VERSION ""

NS_ :

BS_:

BU_: AIL CAB C_ECU C_ECU_GW

BO_ 552 RDR228: 8 C_ECU_GW
 SG_ RDR228_7_0_EYE_TIMEOUT_ERROR_FLG : 56|1@1+ (1,0) [0|1] "" Vector__XXX
 SG_ RDR228_7_1_BLOCKAGE_FORMING_2 : 57|1@1+ (1,0) [0|1] "" Vector__XXX
 SG_ RDR228_7_2_WARN_LCA_R_1ST : 58|1@1+ (1,0) [0|1] "" Vector__XXX
 SG_ RDR228_7_3_WARN_LCA_L_1ST : 59|1@1+ (1,0) [0|1] "" Vector__XXX
 SG_ RDR228_7_4_WARN_LCA_R_2ND : 60|1@1+ (1,0) [0|1] "" Vector__XXX
 SG_ RDR228_7_5_WARN_LCA_L_2ND : 61|1@1+ (1,0) [0|1] "" Vector__XXX
 SG_ RDR228_7_6_WARN_RCTA_R : 62|1@1+ (1,0) [0|1] ""  AIL,CAB
 SG_ RDR228_7_7_WARN_RCTA_L : 63|1@1+ (1,0) [0|1] ""  AIL,CAB
 SG_ RDR228_6_0_WARN_BSD_R_1ST : 48|1@1+ (1,0) [0|1] ""  AIL,CAB
 SG_ RDR228_6_1_WARN_BSD_L_1ST : 49|1@1+ (1,0) [0|1] ""  AIL,CAB
 SG_ RDR228_6_2_WARN_BSD_R_2ND : 50|1@1+ (1,0) [0|1] "" Vector__XXX
 SG_ RDR228_6_3_WARN_BSD_L_2ND : 51|1@1+ (1,0) [0|1] "" Vector__XXX
 SG_ RDR228_6_5_BLOCKAGE_STS : 53|3@1+ (1,0) [0|5] ""  AIL,CAB
 SG_ RDR228_5_0_BSD_R_E : 40|1@1+ (1,0) [0|1] "" Vector__XXX
 SG_ RDR228_5_1_BSD_L_E : 41|1@1+ (1,0) [0|1] "" Vector__XXX
 SG_ RDR228_5_2_LCA_R_E : 42|1@1+ (1,0) [0|1] "" Vector__XXX
 SG_ RDR228_5_3_LCA_L_E : 43|1@1+ (1,0) [0|1] "" Vector__XXX
 SG_ RDR228_5_4_BSD_R_A : 44|1@1+ (1,0) [0|1] "" Vector__XXX
 SG_ RDR228_5_5_BSD_L_A : 45|1@1+ (1,0) [0|1] "" Vector__XXX
 SG_ RDR228_5_6_LCA_R_A : 46|1@1+ (1,0) [0|1] "" Vector__XXX
 SG_ RDR228_5_7_LCA_L_A : 47|1@1+ (1,0) [0|1] "" Vector__XXX
 SG_ RDR228_4_0_DOW_ACTIVELAMP : 32|1@1+ (1,0) [0|1] ""  AIL,CAB
 SG_ RDR228_4_1_WARN_DOW_1ST_R : 33|1@1+ (1,0) [0|1] ""  AIL,CAB
 SG_ RDR228_4_2_WARN_DOW_1ST_L : 34|1@1+ (1,0) [0|1] ""  AIL,CAB
 SG_ RDR228_4_3_WARN_DOW_2ST_R : 35|1@1+ (1,0) [0|1] ""  AIL,CAB
 SG_ RDR228_4_4_WARN_DOW_2ST_L : 36|1@1+ (1,0) [0|1] ""  AIL,CAB
 SG_ RDR228_4_5_CSTM_STS_SRVD : 37|1@1+ (1,0) [0|1] "" Vector__XXX
 SG_ RDR228_4_6_CSTM_STS_BSD_LCA_2ND : 38|1@1+ (1,0) [0|1] "" Vector__XXX
 SG_ RDR228_4_7_CSTM_STS_RCTA : 39|1@1+ (1,0) [0|1] "" Vector__XXX
 SG_ RDR228_3_0_WARN_BSD_LCA_R_2ND : 24|1@1+ (1,0) [0|1] ""  AIL,CAB
 SG_ RDR228_3_1_WARN_BSD_LCA_L_2ND : 25|1@1+ (1,0) [0|1] ""  AIL,CAB
 SG_ RDR228_3_2_CSTM_STS_DOW : 26|1@1+ (1,0) [0|1] "" Vector__XXX
 SG_ RDR228_3_3_CSTM_STS_DOW_SFT_POS : 27|1@1+ (1,0) [0|1] "" Vector__XXX
 SG_ RDR228_3_5_CSTM_DSP_BSD_LCA : 29|1@1+ (1,0) [0|1] "" Vector__XXX
 SG_ RDR228_3_6_CSTM_DSP_BSD_LCA_2ND : 30|1@1+ (1,0) [0|1] "" Vector__XXX
 SG_ RDR228_3_7_CSTM_DSP_RCTA : 31|1@1+ (1,0) [0|1] "" Vector__XXX
 SG_ RDR228_2_0_CSTM_DSP_DOW : 16|1@1+ (1,0) [0|1] "" Vector__XXX
 SG_ RDR228_2_1_EYE_LOCAL_BUS1_FAIL : 17|1@1+ (1,0) [0|1] "" Vector__XXX
 SG_ RDR228_2_2_CSTM_DSP_DOW_SFT_POS : 18|1@1+ (1,0) [0|1] "" Vector__XXX
 SG_ RDR228_2_3_ELK_STOP_REQ_FLG : 19|1@1+ (1,0) [0|1] "" Vector__XXX
 SG_ RDR228_2_4_FAIL_RDRSYS : 20|1@1+ (1,0) [0|1] "" Vector__XXX
 SG_ RDR228_2_5_STOP_RDRSYS : 21|1@1+ (1,0) [0|1] "" Vector__XXX
 SG_ RDR228_2_6_ON_OFF_RDRSYS : 22|1@1+ (1,0) [0|1] "" Vector__XXX
 SG_ RDR228_2_7_BLOCKAGE_FORMING : 23|1@1+ (1,0) [0|1] "" Vector__XXX
 SG_ RDR228_1_0_MSG_COUNTER : 8|4@1+ (1,0) [0|15] ""  AIL
 SG_ RDR228_1_4_BATT_OFF_CAUSE : 12|1@1+ (1,0) [0|1] "" Vector__XXX
 SG_ RDR228_1_5_CSTM_GLO_1 : 13|1@1+ (1,0) [0|1] "" Vector__XXX
 SG_ RDR228_1_6_CSTM_GLO_3 : 14|1@1+ (1,0) [0|1] "" Vector__XXX
 SG_ RDR228_1_7_CSTM_GLO_2 : 15|1@1+ (1,0) [0|1] "" Vector__XXX
 SG_ RDR228_0_0_CHECK_SUM : 0|8@1+ (1,0) [0|255] ""  AIL

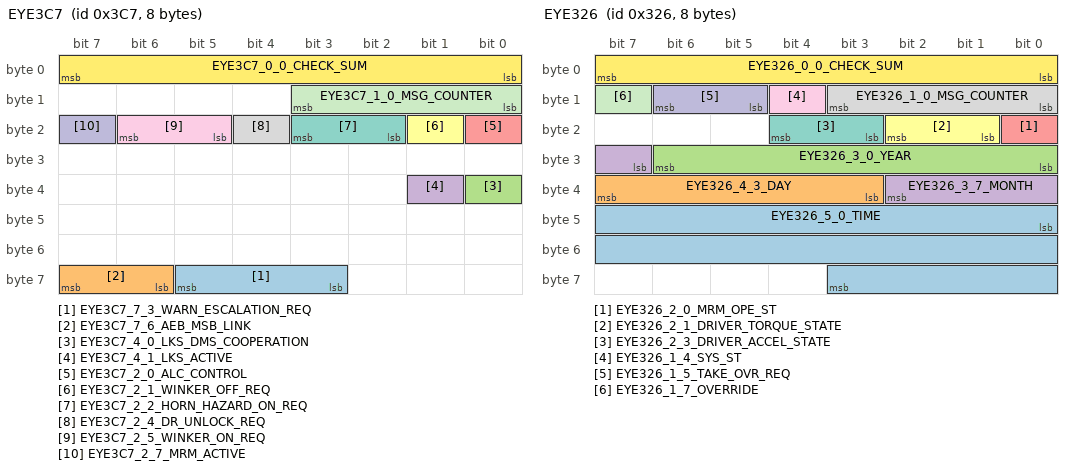
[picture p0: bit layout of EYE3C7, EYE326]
BO_ 967 EYE3C7: 8 C_ECU_GW
 SG_ EYE3C7_7_3_WARN_ESCALATION_REQ : 59|3@1+ (1,0) [0|7] "" Vector__XXX
 SG_ EYE3C7_7_6_AEB_MSB_LINK : 62|2@1+ (1,0) [0|3] "" Vector__XXX
 SG_ EYE3C7_4_0_LKS_DMS_COOPERATION : 32|1@1+ (1,0) [0|1] "" Vector__XXX
 SG_ EYE3C7_4_1_LKS_ACTIVE : 33|1@1+ (1,0) [0|1] "" Vector__XXX
 SG_ EYE3C7_2_0_ALC_CONTROL : 16|1@1+ (1,0) [0|1] "" Vector__XXX
 SG_ EYE3C7_2_1_WINKER_OFF_REQ : 17|1@1+ (1,0) [0|1] "" Vector__XXX
 SG_ EYE3C7_2_2_HORN_HAZARD_ON_REQ : 18|2@1+ (1,0) [0|3] "" Vector__XXX
 SG_ EYE3C7_2_4_DR_UNLOCK_REQ : 20|1@1+ (1,0) [0|1] "" Vector__XXX
 SG_ EYE3C7_2_5_WINKER_ON_REQ : 21|2@1+ (1,0) [0|3] "" Vector__XXX
 SG_ EYE3C7_2_7_MRM_ACTIVE : 23|1@1+ (1,0) [0|1] ""  CAB
 SG_ EYE3C7_1_0_MSG_COUNTER : 8|4@1+ (1,0) [0|15] ""  AIL
 SG_ EYE3C7_0_0_CHECK_SUM : 0|8@1+ (1,0) [0|255] ""  AIL

BO_ 966 EYE3C6: 8 C_ECU_GW
 SG_ EYE3C6_7_0_VEHICLE_DIST_L_LANE1 : 56|7@1+ (1,0) [0|27] "" Vector__XXX
 SG_ EYE3C6_7_7_VEHICLE_L_LANE1 : 63|1@1+ (1,0) [0|1] "" Vector__XXX
 SG_ EYE3C6_6_0_VEHICLE_DIST_R_LANE1 : 48|7@1+ (1,0) [0|27] "" Vector__XXX
 SG_ EYE3C6_6_7_VEHICLE_R_LANE1 : 55|1@1+ (1,0) [0|1] "" Vector__XXX
 SG_ EYE3C6_5_0_VEHICLE_DIST_WY_WAY1 : 40|7@1+ (1,0) [0|27] "" Vector__XXX
 SG_ EYE3C6_5_7_VEHICLE_MY_WAY1 : 47|1@1+ (1,0) [0|1] "" Vector__XXX
 SG_ EYE3C6_4_0_SIDE_MOVEMENT : 32|8@1- (1,0) [-100|100] "" Vector__XXX
 SG_ EYE3C6_3_0_RADER_RR : 24|2@1+ (1,0) [0|3] ""  AIL,CAB
 SG_ EYE3C6_3_2_RADER_RL : 26|2@1+ (1,0) [0|3] ""  AIL,CAB
 SG_ EYE3C6_3_4_RADER_FR : 28|2@1+ (1,0) [0|3] ""  AIL,CAB
 SG_ EYE3C6_3_6_RADER_FL : 30|2@1+ (1,0) [0|3] ""  AIL,CAB
 SG_ EYE3C6_2_0_RADER_R : 16|2@1+ (1,0) [0|3] ""  AIL,CAB
 SG_ EYE3C6_2_2_MY_WAY_LANE_CAR_COLOR : 18|2@1+ (1,0) [0|3] "" Vector__XXX
 SG_ EYE3C6_2_4_TARGET_CAR : 20|3@1+ (1,0) [0|7] "" Vector__XXX
 SG_ EYE3C6_2_7_ALC_STS : 23|1@1+ (1,0) [0|1] "" Vector__XXX
 SG_ EYE3C6_1_0_MSG_COUNTER : 8|4@1+ (1,0) [0|15] ""  AIL
 SG_ EYE3C6_1_4_L_LANE_CAR_COLOR : 12|2@1+ (1,0) [0|3] "" Vector__XXX
 SG_ EYE3C6_1_6_R_LANE_CAR_COLOR : 14|2@1+ (1,0) [0|3] "" Vector__XXX
 SG_ EYE3C6_0_0_CHECK_SUM : 0|8@1+ (1,0) [0|255] ""  AIL

BO_ 965 EYE3C5: 8 C_ECU_GW
 SG_ EYE3C5_7_0_GSR_AEBS_FUNC_INFO : 56|1@1+ (1,0) [0|1] "" Vector__XXX
 SG_ EYE3C5_7_1_CSTM_CRV_ADJUST : 57|2@1+ (1,0) [0|3] "" Vector__XXX
 SG_ EYE3C5_7_3_BRAKE_HAPTIC_CURR : 59|2@1+ (1,0) [0|3] "" Vector__XXX
 SG_ EYE3C5_7_5_SAFETY_MODE_FUNC_INFO : 61|1@1+ (1,0) [0|1] "" Vector__XXX
 SG_ EYE3C5_7_6_SAFETY_MODE_CURR : 62|1@1+ (1,0) [0|1] "" Vector__XXX
 SG_ EYE3C5_7_7_GSR_DDAW_FUNC_INFO : 63|1@1+ (1,0) [0|1] "" Vector__XXX
 SG_ EYE3C5_6_0_IND_SAFETY_MODE : 48|1@1+ (1,0) [0|1] "" Vector__XXX
 SG_ EYE3C5_6_1_ALC_ACTIVE_L : 49|1@1+ (1,0) [0|1] "" Vector__XXX
 SG_ EYE3C5_6_2_FLASHING_IND_SAFETY : 50|1@1+ (1,0) [0|1] "" Vector__XXX
 SG_ EYE3C5_6_3_OVERTAKE_FUNC_INFO : 51|1@1+ (1,0) [0|1] ""  AIL,CAB
 SG_ EYE3C5_6_4_CRV_ADJUST_FUNC_INFO : 52|1@1+ (1,0) [0|1] "" Vector__XXX
 SG_ EYE3C5_6_5_STRG_TOUCHSENSOR_WRNG : 53|1@1+ (1,0) [0|1] "" Vector__XXX
 SG_ EYE3C5_6_6_ALC_ACTIVE_R : 54|1@1+ (1,0) [0|1] "" Vector__XXX
 SG_ EYE3C5_6_7_CSTM_GSR_ISA : 55|1@1+ (1,0) [0|1] "" Vector__XXX
 SG_ EYE3C5_5_0_LANE_COLOR_R : 40|2@1+ (1,0) [0|3] "" Vector__XXX
 SG_ EYE3C5_5_2_LINE_LANE_R : 42|2@1+ (1,0) [0|3] "" Vector__XXX
 SG_ EYE3C5_5_4_LANE_COLOR_L : 44|2@1+ (1,0) [0|3] "" Vector__XXX
 SG_ EYE3C5_5_6_LINE_LANE_L : 46|2@1+ (1,0) [0|3] "" Vector__XXX
 SG_ EYE3C5_4_0_ROAD_SHAPE_CURVE : 32|4@1+ (1,0) [0|15] "" Vector__XXX
 SG_ EYE3C5_4_4_ROAD_SHAPE_DIRECTION : 36|1@1+ (1,0) [0|1] "" Vector__XXX
 SG_ EYE3C5_4_5_CSTM_GSR_ELKS : 37|1@1+ (1,0) [0|1] "" Vector__XXX
 SG_ EYE3C5_4_6_MY_WAY_COLOR : 38|2@1+ (1,0) [0|3] "" Vector__XXX
 SG_ EYE3C5_3_0_AD_DRV_ICON : 24|2@1+ (1,0) [0|3] "" Vector__XXX
 SG_ EYE3C5_3_2_AUTO_HANDLE_ICON : 26|2@1+ (1,0) [0|3] "" Vector__XXX
 SG_ EYE3C5_3_4_WITH_HANDS_ICON : 28|1@1+ (1,0) [0|1] ""  AIL,CAB
 SG_ EYE3C5_3_5_STRG_HAPTIC_WRNG : 29|1@1+ (1,0) [0|1] "" Vector__XXX
 SG_ EYE3C5_3_6_BRK_HPTC_FUNC_INFO : 30|1@1+ (1,0) [0|1] "" Vector__XXX
 SG_ EYE3C5_3_7_SPECIAL_DISP_INFO : 31|1@1+ (1,0) [0|1] "" Vector__XXX
 SG_ EYE3C5_2_0_SLOWDWN_CURVE_ICON : 16|3@1+ (1,0) [0|7] "" Vector__XXX
 SG_ EYE3C5_2_3_FLASHING_IND : 19|1@1+ (1,0) [0|1] "" Vector__XXX
 SG_ EYE3C5_2_4_ATTENTION_TOLLGATE : 20|2@1+ (1,0) [0|3] "" Vector__XXX
 SG_ EYE3C5_2_6_MAPLOCATOR_IND : 22|2@1+ (1,0) [0|3] "" Vector__XXX
 SG_ EYE3C5_1_0_MSG_COUNTER : 8|4@1+ (1,0) [0|15] ""  AIL
 SG_ EYE3C5_1_4_ISA_FAIL_IND : 12|1@1+ (1,0) [0|1] "" Vector__XXX
 SG_ EYE3C5_1_5_SLWF_OFF_IND : 13|1@1+ (1,0) [0|1] "" Vector__XXX
 SG_ EYE3C5_1_6_CSTM_SLWF_SET : 14|1@1+ (1,0) [0|1] "" Vector__XXX
 SG_ EYE3C5_1_7_CSTM_TSR_SOUND_SET : 15|1@1+ (1,0) [0|1] "" Vector__XXX
 SG_ EYE3C5_0_0_CHECK_SUM : 0|8@1+ (1,0) [0|255] ""  AIL

BO_ 964 EYE3C4: 8 C_ECU_GW
 SG_ EYE3C4_7_0_PCR_FAIL_OFF_IND : 56|2@1+ (1,0) [0|3] "" Vector__XXX
 SG_ EYE3C4_7_2_AES_FAIL_OFF_IND : 58|2@1+ (1,0) [0|3] "" Vector__XXX
 SG_ EYE3C4_7_4_LDP_FAIL_OFF_IND : 60|2@1+ (1,0) [0|3] "" Vector__XXX
 SG_ EYE3C4_7_6_ELK_FAIL_OFF_IND : 62|2@1+ (1,0) [0|3] "" Vector__XXX
 SG_ EYE3C4_6_0_MCAM_SYS_FAIL_HALT : 48|2@1+ (1,0) [0|3] "" Vector__XXX
 SG_ EYE3C4_6_2_MCAM_FUNC_INFO : 50|1@1+ (1,0) [0|1] "" Vector__XXX
 SG_ EYE3C4_6_3_EYE_DRV_ACTION_REQ : 51|3@1+ (1,0) [0|7] "" Vector__XXX
 SG_ EYE3C4_6_6_LDW_SND_OFF_FAIL_IND : 54|2@1+ (1,0) [0|3] "" Vector__XXX
 SG_ EYE3C4_5_0_EAM_GREEN : 40|2@1+ (1,0) [0|3] "" Vector__XXX
 SG_ EYE3C4_5_2_EAM_BLUE : 42|2@1+ (1,0) [0|3] "" Vector__XXX
 SG_ EYE3C4_5_4_EAM_GREEN_2 : 44|2@1+ (1,0) [0|3] "" Vector__XXX
 SG_ EYE3C4_5_6_FCW_SND_OFF_FAIL_IND : 46|2@1+ (1,0) [0|3] "" Vector__XXX
 SG_ EYE3C4_4_0_EAM_YELLOW : 32|4@1+ (1,0) [0|15] "" Vector__XXX
 SG_ EYE3C4_4_4_EAM_RED : 36|4@1+ (1,0) [0|15] "" Vector__XXX
 SG_ EYE3C4_3_0_CODE_NO_BUZZER : 24|8@1+ (1,0) [0|255] ""  AIL,CAB
 SG_ EYE3C4_2_0_CODE_WARN : 16|8@1+ (1,0) [0|255] ""  AIL,CAB
 SG_ EYE3C4_1_0_MSG_COUNTER : 8|4@1+ (1,0) [0|15] ""  AIL
 SG_ EYE3C4_1_5_SNR_DRV_ACTION_REQ : 13|3@1+ (1,0) [0|7] "" Vector__XXX
 SG_ EYE3C4_0_0_CHECK_SUM : 0|8@1+ (1,0) [0|255] ""  AIL

BO_ 806 EYE326: 8 C_ECU_GW
 SG_ EYE326_5_0_TIME : 40|20@1+ (0.1,0) [0|86399.9] "sec" Vector__XXX
 SG_ EYE326_4_3_DAY : 35|5@1+ (1,0) [1|31] "日" Vector__XXX
 SG_ EYE326_3_0_YEAR : 24|7@1+ (1,2000) [2000|2126] "年" Vector__XXX
 SG_ EYE326_3_7_MONTH : 31|4@1+ (1,0) [1|12] "月" Vector__XXX
 SG_ EYE326_2_0_MRM_OPE_ST : 16|1@1+ (1,0) [0|1] "" Vector__XXX
 SG_ EYE326_2_1_DRIVER_TORQUE_STATE : 17|2@1+ (1,0) [0|3] "" Vector__XXX
 SG_ EYE326_2_3_DRIVER_ACCEL_STATE : 19|2@1+ (1,0) [0|3] ""  AIL,CAB
 SG_ EYE326_1_0_MSG_COUNTER : 8|4@1+ (1,0) [0|15] ""  AIL
 SG_ EYE326_1_4_SYS_ST : 12|1@1+ (1,0) [0|1] "" Vector__XXX
 SG_ EYE326_1_5_TAKE_OVR_REQ : 13|2@1+ (1,0) [0|3] "" Vector__XXX
 SG_ EYE326_1_7_OVERRIDE : 15|1@1+ (1,0) [0|1] "" Vector__XXX
 SG_ EYE326_0_0_CHECK_SUM : 0|8@1+ (1,0) [0|255] ""  AIL

BO_ 805 EYE325: 8 C_ECU_GW
 SG_ EYE325_6_5_SONAR_DISP_INT : 53|1@1+ (1,0) [0|1] "" Vector__XXX
 SG_ EYE325_5_0_SONAR_R_L_CORNER_4LVL : 40|3@1+ (1,0) [0|7] "" Vector__XXX
 SG_ EYE325_5_3_SONAR_R_R_CORNER_4LVL : 43|3@1+ (1,0) [0|7] "" Vector__XXX
 SG_ EYE325_4_0_SONAR_R_CENTER : 32|3@1+ (1,0) [0|7] "" Vector__XXX
 SG_ EYE325_4_3_SONAR_LEVEL : 35|3@1+ (1,0) [0|7] "" Vector__XXX
 SG_ EYE325_4_6_RAB_WARNING : 38|2@1+ (1,0) [0|3] ""  AIL,CAB
 SG_ EYE325_3_0_SONAR_R_L_CORNER : 24|2@1+ (1,0) [0|3] "" Vector__XXX
 SG_ EYE325_3_2_SONAR_R_R_CORNER : 26|2@1+ (1,0) [0|3] "" Vector__XXX
 SG_ EYE325_3_4_SONAR_R_L_SIDE : 28|2@1+ (1,0) [0|3] "" Vector__XXX
 SG_ EYE325_3_6_SONAR_R_R_SIDE : 30|2@1+ (1,0) [0|3] "" Vector__XXX
 SG_ EYE325_2_0_RAB_OFF : 16|1@1+ (1,0) [0|1] "" Vector__XXX
 SG_ EYE325_2_1_SONAR_OFF : 17|1@1+ (1,0) [0|1] "" Vector__XXX
 SG_ EYE325_2_2_SONAR_SYS_HALT : 18|2@1+ (1,0) [0|3] "" Vector__XXX
 SG_ EYE325_2_4_SONAR_SYS_FAIL : 20|2@1+ (1,0) [0|3] "" Vector__XXX
 SG_ EYE325_2_6_RAB_DISABLE : 22|1@1+ (1,0) [0|1] "" Vector__XXX
 SG_ EYE325_2_7_SONAR_DISABLE : 23|1@1+ (1,0) [0|1] "" Vector__XXX
 SG_ EYE325_1_0_MSG_COUNTER : 8|4@1+ (1,0) [0|15] ""  AIL
 SG_ EYE325_1_4_CSTM_RAB_SET : 12|1@1+ (1,0) [0|1] "" Vector__XXX
 SG_ EYE325_1_5_CSTM_CLR_SNR_SET : 13|1@1+ (1,0) [0|1] "" Vector__XXX
 SG_ EYE325_1_6_RAB : 14|1@1+ (1,0) [0|1] "" Vector__XXX
 SG_ EYE325_1_7_SONAR_NO_DISP : 15|1@1+ (1,0) [0|1] "" Vector__XXX
 SG_ EYE325_0_0_CHECK_SUM : 0|8@1+ (1,0) [0|255] ""  AIL

BO_ 803 EYE323: 8 C_ECU_GW
 SG_ EYE323_7_0_ISA_OFFSET_CURR : 56|5@1+ (1,-10) [-10|10] "" Vector__XXX
 SG_ EYE323_7_5_SLIF_FUNC_INFO : 61|1@1+ (1,0) [0|1] "" Vector__XXX
 SG_ EYE323_7_6_ISA_FUNC_INFO : 62|1@1+ (1,0) [0|1] "" Vector__XXX
 SG_ EYE323_7_7_ISA_CUSTOMIZE_CURR : 63|1@1+ (1,0) [0|1] "" Vector__XXX
 SG_ EYE323_6_0_LDW_OFFSW_INFO : 48|1@1+ (1,0) [0|1] "" Vector__XXX
 SG_ EYE323_6_1_LDW_ON_OFF_SET : 49|1@1+ (1,0) [0|1] "" Vector__XXX
 SG_ EYE323_6_2_CSTM_DDAW_WARN_SET : 50|1@1+ (1,0) [0|1] "" Vector__XXX
 SG_ EYE323_6_3_IACC_FUNC_INFO : 51|1@1+ (1,0) [0|1] "" Vector__XXX
 SG_ EYE323_6_5_CSTM_LDW_TIMING_SET : 53|1@1+ (1,0) [0|1] "" Vector__XXX
 SG_ EYE323_6_6_CSTM_LDW_TIMING : 54|1@1+ (1,0) [0|1] "" Vector__XXX
 SG_ EYE323_6_7_SLOWDOWNL_FUNC_INFO : 55|1@1+ (1,0) [0|1] "" Vector__XXX
 SG_ EYE323_5_0_CNG_GRN_CONT_CURR : 40|1@1+ (1,0) [0|1] "" Vector__XXX
 SG_ EYE323_5_1_TRAFFIC_FUNC_INFO : 41|1@1+ (1,0) [0|1] "" Vector__XXX
 SG_ EYE323_5_2_FCW_OFFSW_INFO : 42|1@1+ (1,0) [0|1] "" Vector__XXX
 SG_ EYE323_5_3_FCW_ON_OFF_SET : 43|1@1+ (1,0) [0|1] "" Vector__XXX
 SG_ EYE323_5_4_WARNING_SEL_CURR : 44|1@1+ (1,0) [0|1] "" Vector__XXX
 SG_ EYE323_5_5_HAPT_FUNC_INFO : 45|1@1+ (1,0) [0|1] "" Vector__XXX
 SG_ EYE323_5_6_TOLLGATE_CONT_CURR : 46|1@1+ (1,0) [0|1] "" Vector__XXX
 SG_ EYE323_5_7_CURVE_CONT_CURR : 47|1@1+ (1,0) [0|1] "" Vector__XXX
 SG_ EYE323_4_0_FCTB_ICON_L : 32|2@1+ (1,0) [0|3] "" Vector__XXX
 SG_ EYE323_4_2_FCTB_ICON_R : 34|2@1+ (1,0) [0|3] "" Vector__XXX
 SG_ EYE323_4_4_FCW_CONT_CURR : 36|2@1+ (1,0) [0|3] "" Vector__XXX
 SG_ EYE323_4_6_FCW_DISPLAY_SEL : 38|2@1+ (1,0) [0|3] "" Vector__XXX
 SG_ EYE323_3_0_AES_FUNC_INFO : 24|1@1+ (1,0) [0|1] "" Vector__XXX
 SG_ EYE323_3_1_CSTM_TSR_NO_ENTRY_SET : 25|1@1+ (1,0) [0|1] "" Vector__XXX
 SG_ EYE323_3_2_CSTM_TSR_STOP_SET : 26|1@1+ (1,0) [0|1] "" Vector__XXX
 SG_ EYE323_3_3_CSTM_TSR_GIVE_WAY_SET : 27|1@1+ (1,0) [0|1] "" Vector__XXX
 SG_ EYE323_3_4_WILDERNESS : 28|1@1+ (1,0) [0|1] "" Vector__XXX
 SG_ EYE323_3_5_AES_OFF : 29|1@1+ (1,0) [0|1] "" Vector__XXX
 SG_ EYE323_3_6_FCTB_IND : 30|2@1+ (1,0) [0|3] "" Vector__XXX
 SG_ EYE323_2_0_CSTM_LDW_ALK_B : 16|2@1+ (1,0) [0|3] "" Vector__XXX
 SG_ EYE323_2_2_CSTM_P_CR : 18|1@1+ (1,0) [0|1] "" Vector__XXX
 SG_ EYE323_2_3_SLOWDOWN_FUNC_INFO2 : 19|1@1+ (1,0) [0|1] "" Vector__XXX
 SG_ EYE323_2_4_CID_CODE_WARN : 20|4@1+ (1,0) [0|15] ""  AIL,CAB
 SG_ EYE323_1_0_MSG_COUNTER : 8|4@1+ (1,0) [0|15] ""  AIL,CAB
 SG_ EYE323_1_4_DISP_FOLLOW_FORWARD : 12|1@1+ (1,0) [0|1] ""  AIL,CAB
 SG_ EYE323_1_5_KEEP_LINE_SENTER_ACT : 13|1@1+ (1,0) [0|1] ""  AIL,CAB
 SG_ EYE323_1_6_DDAW_FAIL_OFF : 14|2@1+ (1,0) [0|3] "" Vector__XXX
 SG_ EYE323_0_0_CHECK_SUM : 0|8@1+ (1,0) [0|255] ""  AIL,CAB

BO_ 802 EYE322: 8 C_ECU_GW
 SG_ EYE322_7_0_CSTM_ACC_CONT_SET : 56|2@1+ (1,0) [0|3] "" Vector__XXX
 SG_ EYE322_7_2_ELK_OFF_IND : 58|1@1+ (1,0) [0|1] "" Vector__XXX
 SG_ EYE322_7_3_LIGHT_EAM_YELLOW : 59|2@1+ (1,0) [0|3] "" Vector__XXX
 SG_ EYE322_7_5_BROKEN_LINE_L : 61|1@1+ (1,0) [0|1] "" Vector__XXX
 SG_ EYE322_7_6_TJA_ACTIVE : 62|1@1+ (1,0) [0|1] "" Vector__XXX
 SG_ EYE322_7_7_BROKEN_LINE_R : 63|1@1+ (1,0) [0|1] "" Vector__XXX
 SG_ EYE322_6_0_CSTM_MIS_AT_START : 48|2@1+ (1,0) [0|3] "" Vector__XXX
 SG_ EYE322_6_2_CSTM_ALK_TJA_SET : 50|1@1+ (1,0) [0|1] "" Vector__XXX
 SG_ EYE322_6_3_CSTM_LANE_SET : 51|1@1+ (1,0) [0|1] "" Vector__XXX
 SG_ EYE322_6_4_LDP_OFF_IND : 52|1@1+ (1,0) [0|1] "" Vector__XXX
 SG_ EYE322_6_5_INDICATOR_MODE_L : 53|2@1+ (1,0) [0|3] "" Vector__XXX
 SG_ EYE322_6_7_CSTM_ELK_SET : 55|1@1+ (1,0) [0|1] "" Vector__XXX
 SG_ EYE322_5_0_CSTM_MIS_AT_BACK : 40|1@1+ (1,0) [0|1] "" Vector__XXX
 SG_ EYE322_5_1_CSTM_ALK_TJA : 41|1@1+ (1,0) [0|1] "" Vector__XXX
 SG_ EYE322_5_2_CSTM_SAS : 42|1@1+ (1,0) [0|1] "" Vector__XXX
 SG_ EYE322_5_3_CSTM_HBA : 43|1@1+ (1,0) [0|1] "" Vector__XXX
 SG_ EYE322_5_4_CSTM_ACC_CONT : 44|1@1+ (1,0) [0|1] "" Vector__XXX
 SG_ EYE322_5_5_CSTM_LANE : 45|1@1+ (1,0) [0|1] "" Vector__XXX
 SG_ EYE322_5_6_LDW_SOUND_OFF_IND : 46|1@1+ (1,0) [0|1] "" Vector__XXX
 SG_ EYE322_5_7_CSTM_ELK_SET : 47|1@1+ (1,0) [0|1] "" Vector__XXX
 SG_ EYE322_4_0_CODE_WARN : 32|5@1+ (1,0) [0|31] "" Vector__XXX
 SG_ EYE322_4_5_CSTM_GSR : 37|1@1+ (1,0) [0|1] "" Vector__XXX
 SG_ EYE322_3_0_LANE_L : 24|2@1+ (1,0) [0|3] "" Vector__XXX
 SG_ EYE322_3_2_LANE_R : 26|2@1+ (1,0) [0|3] "" Vector__XXX
 SG_ EYE322_3_4_LANE_L_COLOR : 28|2@1+ (1,0) [0|3] "" Vector__XXX
 SG_ EYE322_3_6_LANE_R_COLOR : 30|2@1+ (1,0) [0|3] "" Vector__XXX
 SG_ EYE322_2_0_FCW_OFF_IND : 16|1@1+ (1,0) [0|1] "" Vector__XXX
 SG_ EYE322_2_1_MOV_EYESIGHT_SCREEN : 17|1@1+ (1,0) [0|1] "" Vector__XXX
 SG_ EYE322_2_2_ALK_ICON : 18|2@1+ (1,0) [0|3] ""  AIL,CAB
 SG_ EYE322_2_4_INDICATOR_CTRL_REQ : 20|1@1+ (1,0) [0|1] "" Vector__XXX
 SG_ EYE322_2_5_INDICATOR_MODE_R : 21|2@1+ (1,0) [0|3] "" Vector__XXX
 SG_ EYE322_2_7_LIMITER_BACK_SPEED : 23|1@1+ (1,0) [0|1] "" Vector__XXX
 SG_ EYE322_1_0_MSG_COUNTER : 8|4@1+ (1,0) [0|15] ""  AIL
 SG_ EYE322_1_4_CODE_NO_BUZZER : 12|3@1+ (1,0) [0|7] "" Vector__XXX
 SG_ EYE322_1_7_DISTWARN_DMS : 15|1@1+ (1,0) [0|1] "" Vector__XXX
 SG_ EYE322_0_0_CHECK_SUM : 0|8@1+ (1,0) [0|255] ""  AIL

BO_ 801 EYE321: 8 C_ECU_GW
 SG_ EYE321_7_0_INFO_DIST_FORWARD : 56|4@1+ (1,0) [0|15] ""  AIL,CAB
 SG_ EYE321_7_4_INFO_KEEP_STOP : 60|1@1+ (1,0) [0|1] "" Vector__XXX
 SG_ EYE321_7_5_INFO_READY : 61|1@1+ (1,0) [0|1] "" Vector__XXX
 SG_ EYE321_7_6_INFO_SET_CC : 62|1@1+ (1,0) [0|1] ""  AIL,CAB
 SG_ EYE321_7_7_INFO_OFF : 63|1@1+ (1,0) [0|1] "" Vector__XXX
 SG_ EYE321_6_0_FAIL_EYESIGHT : 48|1@1+ (1,0) [0|1] ""  AIL,CAB
 SG_ EYE321_6_1_MOV_EYESIGHT_SCREEN : 49|1@1+ (1,0) [0|1] "" Vector__XXX
 SG_ EYE321_6_2_IND_VEHICLE : 50|1@1+ (1,0) [0|1] "" Vector__XXX
 SG_ EYE321_6_3_BRAKELAMP_VEHICLE : 51|1@1+ (1,0) [0|1] "" Vector__XXX
 SG_ EYE321_6_4_IND_FORWARD_VECL : 52|1@1+ (1,0) [0|1] ""  AIL,CAB
 SG_ EYE321_6_5_BRAKELAMP_FORWARD : 53|1@1+ (1,0) [0|1] ""  AIL,CAB
 SG_ EYE321_6_6_CC_OR_LIM_SON : 54|1@1+ (1,0) [0|1] "" Vector__XXX
 SG_ EYE321_6_7_TEMP_OFF_STATE : 55|1@1+ (1,0) [0|1] "" Vector__XXX
 SG_ EYE321_5_0_INFO_SET_SPD : 40|8@1+ (1,0) [0|255] "km/h or MPH"  CAB
 SG_ EYE321_4_0_ACC_MODE : 32|2@1+ (1,0) [0|3] "" Vector__XXX
 SG_ EYE321_4_2_SRVD_LASTMEM_ST_REQ : 34|1@1+ (1,0) [0|1] "" Vector__XXX
 SG_ EYE321_4_3_INFO_MAIN_CC : 35|2@1+ (1,0) [0|3] ""  AIL,CAB
 SG_ EYE321_4_5_TRAFFIC_LIGHT : 37|3@1+ (1,0) [0|7] "" Vector__XXX
 SG_ EYE321_3_0_CODE_HALT : 24|3@1+ (1,0) [0|7] "" Vector__XXX
 SG_ EYE321_3_3_ELK_EQUIP : 27|1@1+ (1,0) [0|1] "" Vector__XXX
 SG_ EYE321_3_4_SET_DIST : 28|3@1+ (1,0) [0|7] ""  AIL,CAB
 SG_ EYE321_3_7_TJA : 31|1@1+ (1,0) [0|1] "" Vector__XXX
 SG_ EYE321_2_0_ACC_CANCEL_OR_CSTM : 16|4@1+ (1,0) [0|15] "" Vector__XXX
 SG_ EYE321_2_4_ALK_CANCEL_OR_CSTM : 20|3@1+ (1,0) [0|7] "" Vector__XXX
 SG_ EYE321_2_7_ALK_CANCEL_DISP_TYPE : 23|1@1+ (1,0) [0|1] "" Vector__XXX
 SG_ EYE321_1_0_MSG_COUNTER : 8|4@1+ (1,0) [0|15] ""  AIL,CAB
 SG_ EYE321_1_4_PRECRASH_BRAKE_OFF : 12|1@1+ (1,0) [0|1] "" Vector__XXX
 SG_ EYE321_1_5_LANE_DEPARTURE_OFF : 13|1@1+ (1,0) [0|1] "" Vector__XXX
 SG_ EYE321_1_6_MET_AD_DRV_ASS : 14|1@1+ (1,0) [0|1] "" Vector__XXX
 SG_ EYE321_1_7_ALC_EQUIP : 15|1@1+ (1,0) [0|1] "" Vector__XXX
 SG_ EYE321_0_0_CHECK_SUM : 0|8@1+ (1,0) [0|255] ""  AIL,CAB

BO_ 556 EYE22C: 8 C_ECU_GW
 SG_ EYE22C_7_0_COMMANDSW_CC : 56|3@1+ (1,0) [0|7] "" Vector__XXX
 SG_ EYE22C_7_3_MODE_CC : 59|1@1+ (1,0) [0|1] ""  AIL,CAB
 SG_ EYE22C_7_4_CC_SETLAMP_INFO : 60|1@1+ (1,0) [0|1] "" Vector__XXX
 SG_ EYE22C_7_5_MSA_CNT_STS_EGI_HEV : 61|1@1+ (1,0) [0|1] "" Vector__XXX
 SG_ EYE22C_7_6_SET_MSA : 62|1@1+ (1,0) [0|1] "" Vector__XXX
 SG_ EYE22C_7_7_SET_CC : 63|1@1+ (1,0) [0|1] "" Vector__XXX
 SG_ EYE22C_5_0_TRQDWN_FORCE_LIMIT : 40|16@1+ (1.6,0) [0|408] "Nm" Vector__XXX
 SG_ EYE22C_4_0_BLIPPING_INHI : 32|1@1+ (1,0) [0|1] "" Vector__XXX
 SG_ EYE22C_4_4_ACTIVE_BRAKE_ACC : 36|1@1+ (1,0) [0|1] "" Vector__XXX
 SG_ EYE22C_4_5_REQ_FMW : 37|1@1+ (1,0) [0|1] "" Vector__XXX
 SG_ EYE22C_4_6_FLG_BEFORE_RESERVE : 38|1@1+ (1,0) [0|1] "" Vector__XXX
 SG_ EYE22C_4_7_REQ_TARGET_TORQUE : 39|1@1+ (1,0) [0|1] "" Vector__XXX
 SG_ EYE22C_2_0_TGT_SPD_TRQ_FORCE : 16|16@1+ (0.1,-1000) [-1000|5553.5] "Nm" Vector__XXX
 SG_ EYE22C_1_0_MSG_COUNTER : 8|4@1+ (1,0) [0|15] ""  AIL
 SG_ EYE22C_1_4_FLG_ADAPTIVE_CC : 12|1@1+ (1,0) [0|1] ""  AIL,CAB
 SG_ EYE22C_1_5_MAIN_CC : 13|1@1+ (1,0) [0|1] "" Vector__XXX
 SG_ EYE22C_1_6_FLG_EYESIGHT_VERSION : 14|1@1+ (1,0) [0|1] "" Vector__XXX
 SG_ EYE22C_1_7_FAIL_EYESIGHT : 15|1@1+ (1,0) [0|1] "" Vector__XXX
 SG_ EYE22C_0_0_CHECK_SUM : 0|8@1+ (1,0) [0|255] ""  AIL

BO_ 545 EYE221: 8 C_ECU_GW
 SG_ EYE221_7_0_COMMANDSW_CC : 56|3@1+ (1,0) [0|7] "" Vector__XXX
 SG_ EYE221_7_3_MODE_CC : 59|1@1+ (1,0) [0|1] ""  CAB
 SG_ EYE221_7_4_MSA_CNT_STS_EGI_HEV : 60|2@1+ (1,0) [0|2] "" Vector__XXX
 SG_ EYE221_7_6_EQUIP_MSA : 62|1@1+ (1,0) [0|1] "" Vector__XXX
 SG_ EYE221_7_7_INHIBIT_FUEL_CUT : 63|1@1+ (1,0) [0|1] "" Vector__XXX
 SG_ EYE221_5_0_TRQDWN_FORCE_LIMIT : 40|16@1+ (1.6,0) [0|408] "Nm" Vector__XXX
 SG_ EYE221_4_0_STATE_TRACKING : 32|1@1+ (1,0) [0|1] "" Vector__XXX
 SG_ EYE221_4_1_STATE_LSF : 33|1@1+ (1,0) [0|1] "" Vector__XXX
 SG_ EYE221_4_2_FORCED_CANCEL_ACC : 34|1@1+ (1,0) [0|1] "" Vector__XXX
 SG_ EYE221_4_3_BRAKE_TYPE : 35|1@1+ (1,0) [0|1] "" Vector__XXX
 SG_ EYE221_4_4_ACTIVE_BRAKE_ACC : 36|1@1+ (1,0) [0|1] "" Vector__XXX
 SG_ EYE221_4_5_REQ_FMW : 37|1@1+ (1,0) [0|1] "" Vector__XXX
 SG_ EYE221_4_6_FLG_BEFORE_RESERVE : 38|1@1+ (1,0) [0|1] "" Vector__XXX
 SG_ EYE221_4_7_REQ_TARGET_TORQUE : 39|1@1+ (1,0) [0|1] "" Vector__XXX
 SG_ EYE221_2_0_TGT_SPD_TRQ_FORCE : 16|16@1+ (0.1,-1000) [-1000|5553.5] "Nm" Vector__XXX
 SG_ EYE221_1_0_MSG_COUNTER : 8|4@1+ (1,0) [0|15] "" Vector__XXX
 SG_ EYE221_1_4_FLG_ADAPTIVE_CC : 12|1@1+ (1,0) [0|1] ""  CAB
 SG_ EYE221_1_5_CANCEL_SW_INFO : 13|1@1+ (1,0) [0|1] "" Vector__XXX
 SG_ EYE221_1_6_FLG_EYESIGHT_VERSION : 14|1@1+ (1,0) [0|1] "" Vector__XXX
 SG_ EYE221_1_7_FAIL_EYESIGHT : 15|1@1+ (1,0) [0|1] "" Vector__XXX
 SG_ EYE221_0_0_CHECK_SUM : 0|8@1+ (1,0) [0|255] "" Vector__XXX

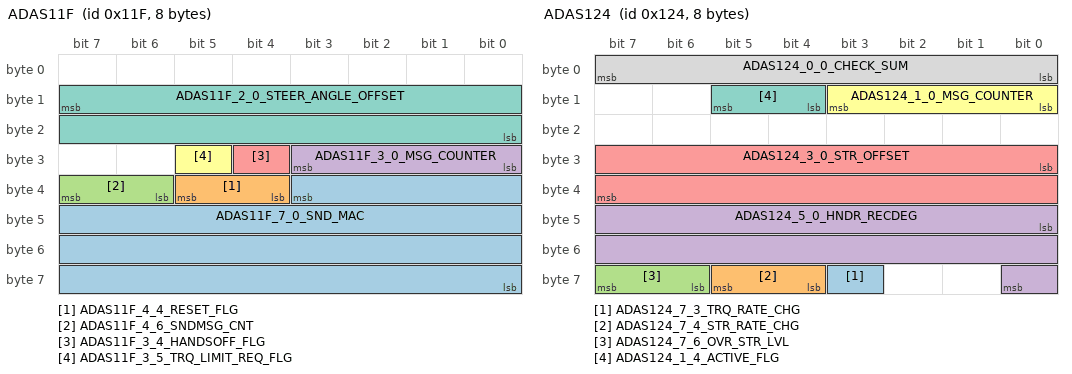
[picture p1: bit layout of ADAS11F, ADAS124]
BO_ 287 ADAS11F: 8 C_ECU_GW
 SG_ ADAS11F_7_0_SND_MAC : 35|28@0+ (1,0) [0|268435455] "" Vector__XXX
 SG_ ADAS11F_4_4_RESET_FLG : 37|2@0+ (1,0) [0|3] "" Vector__XXX
 SG_ ADAS11F_4_6_SNDMSG_CNT : 39|2@0+ (1,0) [0|3] "" Vector__XXX
 SG_ ADAS11F_3_0_MSG_COUNTER : 27|4@0+ (1,0) [0|15] ""  AIL
 SG_ ADAS11F_3_4_HANDSOFF_FLG : 28|1@0+ (1,0) [0|1] ""  AIL,CAB
 SG_ ADAS11F_3_5_TRQ_LIMIT_REQ_FLG : 29|1@0+ (1,0) [0|1] "" Vector__XXX
 SG_ ADAS11F_2_0_STEER_ANGLE_OFFSET : 15|16@0- (0.01,0) [-327.67|327.67] "deg" Vector__XXX

BO_ 292 ADAS124: 8 C_ECU_GW
 SG_ ADAS124_7_3_TRQ_RATE_CHG : 59|1@1+ (1,0) [0|1] "" Vector__XXX
 SG_ ADAS124_7_4_STR_RATE_CHG : 60|2@1+ (1,0) [0|3] "" Vector__XXX
 SG_ ADAS124_7_6_OVR_STR_LVL : 62|2@1+ (1,0) [0|3] "" Vector__XXX
 SG_ ADAS124_5_0_HNDR_RECDEG : 40|17@1- (0.01,0) [-655|655] "deg"  CAB
 SG_ ADAS124_3_0_STR_OFFSET : 24|16@1- (0.01,0) [-327.67|327.67] "deg"  CAB
 SG_ ADAS124_1_0_MSG_COUNTER : 8|4@1+ (1,0) [0|15] ""  CAB
 SG_ ADAS124_1_4_ACTIVE_FLG : 12|2@1+ (1,0) [0|3] ""  CAB
 SG_ ADAS124_0_0_CHECK_SUM : 0|8@1+ (1,0) [0|255] ""  CAB

BO_ 279 SNR117: 8 C_ECU_GW
 SG_ SNR117_16_0_CSTM_SNR_DSPREEQ : 128|2@1+ (1,0) [0|3] "" Vector__XXX
 SG_ SNR117_16_2_CSTM_RAB_DSPREQ : 130|2@1+ (1,0) [0|3] "" Vector__XXX
 SG_ SNR117_16_4_CSTM_PED_DSPREQ : 132|2@1+ (1,0) [0|3] "" Vector__XXX
 SG_ SNR117_16_6_CSTM_PEDTIM_DSPREQ : 134|2@1+ (1,0) [0|3] "" Vector__XXX
 SG_ SNR117_15_0_CSTM_SNR_CLEAR : 120|1@1+ (1,0) [0|1] "" Vector__XXX
 SG_ SNR117_15_1_CSTM_RAB : 121|1@1+ (1,0) [0|1] "" Vector__XXX
 SG_ SNR117_15_2_CSTM_RAB_PED : 122|1@1+ (1,0) [0|1] "" Vector__XXX
 SG_ SNR117_15_3_CSTM_RAB_PED_TIMING : 123|2@1+ (1,0) [0|3] "" Vector__XXX
 SG_ SNR117_14_0_RAB_WARNING : 112|3@1+ (1,0) [0|7] "" Vector__XXX
 SG_ SNR117_14_3_SONAR_LEVEL : 115|5@1+ (1,0) [0|8] "" Vector__XXX
 SG_ SNR117_13_0_PED_WARN_CENTER : 104|1@1+ (1,0) [0|1] "" Vector__XXX
 SG_ SNR117_13_1_PED_WARN_LEFT : 105|1@1+ (1,0) [0|1] "" Vector__XXX
 SG_ SNR117_13_2_PED_WARN_RIGHT : 106|1@1+ (1,0) [0|1] "" Vector__XXX
 SG_ SNR117_13_3_RAB_TRIG_TYPE : 107|2@1+ (1,0) [0|3] "" Vector__XXX
 SG_ SNR117_13_4_RAB_TRIG_TYPE : 108|1@1+ (1,0) [0|0] "" Vector__XXX
 SG_ SNR117_9_0_SONAR_R_R_CORNER_4LV : 72|3@1+ (1,0) [0|7] "" Vector__XXX
 SG_ SNR117_8_0_SONAR_DISP_INT : 64|1@1+ (1,0) [0|1] "" Vector__XXX
 SG_ SNR117_8_1_SONAR_R_CENTER : 65|3@1+ (1,0) [0|7] "" Vector__XXX
 SG_ SNR117_8_4_SONAR_R_L_CORNER_4LV : 68|3@1+ (1,0) [0|7] "" Vector__XXX
 SG_ SNR117_7_0_SONAR_SYS_FAIL : 56|2@1+ (1,0) [0|3] "" Vector__XXX
 SG_ SNR117_7_2_RAB_HALT : 58|2@1+ (1,0) [0|3] "" Vector__XXX
 SG_ SNR117_7_4_CAMERA_FAIL : 60|2@1+ (1,0) [0|3] "" Vector__XXX
 SG_ SNR117_7_6_RAB_PED_HALT : 62|2@1+ (1,0) [0|3] "" Vector__XXX
 SG_ SNR117_6_0_REQ_ACT_EPB : 48|1@1+ (1,0) [0|1] "" Vector__XXX
 SG_ SNR117_6_1_STOP_HOJI_BUZ_ACT : 49|1@1+ (1,0) [0|1] "" Vector__XXX
 SG_ SNR117_6_2_RAB_OFF : 50|1@1+ (1,0) [0|1] "" Vector__XXX
 SG_ SNR117_6_3_SONAR_OFF : 51|1@1+ (1,0) [0|1] "" Vector__XXX
 SG_ SNR117_6_4_RAB_PED_OFF : 52|1@1+ (1,0) [0|1] "" Vector__XXX
 SG_ SNR117_6_5_SONAR_HALT : 53|2@1+ (1,0) [0|3] "" Vector__XXX
 SG_ SNR117_5_0_YOATSU_ACT : 40|1@1+ (1,0) [0|1] "" Vector__XXX
 SG_ SNR117_5_1_TORQUE_LIM_ACT : 41|1@1+ (1,0) [0|1] "" Vector__XXX
 SG_ SNR117_5_2_TORQUE_LIM_VAL : 42|6@1+ (0.01,0) [0|0.63] "G" Vector__XXX
 SG_ SNR117_4_0_RAB_ACT : 32|1@1+ (1,0) [0|1] ""  CAB
 SG_ SNR117_4_1_RAB_VAL : 33|7@1+ (0.01,0) [0|1.27] "G" Vector__XXX
 SG_ SNR117_3_0_RAB : 24|1@1+ (1,0) [0|1] "" Vector__XXX
 SG_ SNR117_3_1_RAB_PED : 25|1@1+ (1,0) [0|1] "" Vector__XXX
 SG_ SNR117_2_0_E2E_COUNTER : 16|8@1+ (1,0) [0|255] "" Vector__XXX
 SG_ SNR117_0_0_E2E_CRC : 0|16@1+ (1,0) [0|65535] "" Vector__XXX

BO_ 845 ADAS34D: 8 Vector__XXX
 SG_ ADAS34D_16_0_CSTM_SNR_DSPREEQ : 128|2@1+ (1,0) [0|3] "" Vector__XXX
 SG_ ADAS34D_16_2_CSTM_RAB_DSPREQ : 130|2@1+ (1,0) [0|3] "" Vector__XXX
 SG_ ADAS34D_16_4_CSTM_PED_DSPREQ : 132|2@1+ (1,0) [0|3] "" Vector__XXX
 SG_ ADAS34D_16_6_CSTM_PEDTIM_DSPREQ : 134|2@1+ (1,0) [0|3] "" Vector__XXX
 SG_ ADAS34D_15_0_CSTM_SNR_CLEAR : 120|1@1+ (1,0) [0|1] "" Vector__XXX
 SG_ ADAS34D_15_1_CSTM_RAB : 121|1@1+ (1,0) [0|1] "" Vector__XXX
 SG_ ADAS34D_15_2_CSTM_RAB_PED : 122|1@1+ (1,0) [0|1] "" Vector__XXX
 SG_ ADAS34D_15_3_CSTM_RAB_PED_TIMING : 123|2@1+ (1,0) [0|3] "" Vector__XXX
 SG_ ADAS34D_15_5_CSTM_TEMP_OFF : 125|2@1+ (1,0) [0|3] "" Vector__XXX
 SG_ ADAS34D_15_7_TEMP_OFF_STATE : 127|1@1+ (1,0) [0|1] "" Vector__XXX
 SG_ ADAS34D_14_0_RAB_WARNING : 112|3@1+ (1,0) [0|7] "" Vector__XXX
 SG_ ADAS34D_14_3_SONAR_LEVEL : 115|5@1+ (1,0) [0|8] "" Vector__XXX
 SG_ ADAS34D_13_0_PED_WARN_CENTER : 104|1@1+ (1,0) [0|1] "" Vector__XXX
 SG_ ADAS34D_13_1_PED_WARN_LEFT : 105|1@1+ (1,0) [0|1] "" Vector__XXX
 SG_ ADAS34D_13_2_PED_WARN_RIGHT : 106|1@1+ (1,0) [0|1] "" Vector__XXX
 SG_ ADAS34D_13_3_RAB_TRIG_TYPE : 107|2@1+ (1,0) [0|3] "" Vector__XXX
 SG_ ADAS34D_9_0_SONAR_R_R_CORNER_4LV : 72|3@1+ (1,0) [0|7] "" Vector__XXX
 SG_ ADAS34D_8_0_SONAR_DISP_INT : 64|1@1+ (1,0) [0|1] "" Vector__XXX
 SG_ ADAS34D_8_1_SONAR_R_CENTER : 65|3@1+ (1,0) [0|7] "" Vector__XXX
 SG_ ADAS34D_8_4_SONAR_R_L_CORNER_4LV : 68|3@1+ (1,0) [0|7] "" Vector__XXX
 SG_ ADAS34D_7_0_SONAR_SYS_FAIL : 56|2@1+ (1,0) [0|3] "" Vector__XXX
 SG_ ADAS34D_7_2_RAB_HALT : 58|2@1+ (1,0) [0|3] "" Vector__XXX
 SG_ ADAS34D_7_4_CAMERA_FAIL : 60|2@1+ (1,0) [0|3] "" Vector__XXX
 SG_ ADAS34D_7_6_RAB_PED_HALT : 62|2@1+ (1,0) [0|3] "" Vector__XXX
 SG_ ADAS34D_6_0_REQ_ACT_EPB : 48|1@1+ (1,0) [0|1] "" Vector__XXX
 SG_ ADAS34D_6_1_STOP_HOJI_BUZ_ACT : 49|1@1+ (1,0) [0|1] "" Vector__XXX
 SG_ ADAS34D_6_2_RAB_OFF : 50|1@1+ (1,0) [0|1] "" Vector__XXX
 SG_ ADAS34D_6_3_SONAR_OFF : 51|1@1+ (1,0) [0|1] "" Vector__XXX
 SG_ ADAS34D_6_4_RAB_PED_OFF : 52|1@1+ (1,0) [0|1] "" Vector__XXX
 SG_ ADAS34D_6_5_SONAR_HALT : 53|2@1+ (1,0) [0|3] "" Vector__XXX
 SG_ ADAS34D_5_0_YOATSU_ACT : 40|1@1+ (1,0) [0|1] "" Vector__XXX
 SG_ ADAS34D_5_1_TORQUE_LIM_ACT : 41|1@1+ (1,0) [0|1] "" Vector__XXX
 SG_ ADAS34D_5_2_TORQUE_LIM_VAL : 42|6@1+ (0.01,0) [0|0.63] "G" Vector__XXX
 SG_ ADAS34D_4_0_RAB_ACT : 32|1@1+ (1,0) [0|1] ""  CAB
 SG_ ADAS34D_4_1_RAB_VAL : 33|7@1+ (0.01,0) [0|1.27] "G" Vector__XXX
 SG_ ADAS34D_3_0_RAB : 24|1@1+ (1,0) [0|1] "" Vector__XXX
 SG_ ADAS34D_3_1_RAB_PED : 25|1@1+ (1,0) [0|1] "" Vector__XXX
 SG_ ADAS34D_2_0_E2E_COUNTER : 16|8@1+ (1,0) [0|255] "" Vector__XXX
 SG_ ADAS34D_0_0_E2E_CRC : 0|16@1+ (1,0) [0|65535] "" Vector__XXX

BO_ 1109 CHR455: 8 Vector__XXX
 SG_ CHR455_31_3_CHGCNRLOCSTT_DISPREQ : 251|2@1+ (1,0) [0|2] "" Vector__XXX
 SG_ CHR455_28_4_VEH_CHGPWRUPLMT : 228|17@1+ (1,0) [0|131071] "kW" Vector__XXX
 SG_ CHR455_27_4_V2H_MODE : 220|8@1+ (1,0) [0|1] "" Vector__XXX
 SG_ CHR455_26_4_DCPWRSUPSTT : 212|8@1+ (1,0) [0|255] "" Vector__XXX
 SG_ CHR455_26_3_CHGMNTDISP_REQ : 211|1@1+ (1,0) [0|1] "" Vector__XXX
 SG_ CHR455_26_2_MNTLIT_REQ : 210|1@1+ (1,0) [0|1] "" Vector__XXX
 SG_ CHR455_25_0_CHGVLT_DISP : 200|10@1+ (1,0) [0|1023] "V" Vector__XXX
 SG_ CHR455_23_0_CHGCUR_DISP : 184|16@1+ (1,0) [0|65535] "A" Vector__XXX
 SG_ CHR455_22_1_CHGSTPCOMP : 177|1@1+ (1,0) [0|1] "" Vector__XXX
 SG_ CHR455_20_1_ENERGY_CHARGED_DISP : 161|16@1+ (1,0) [0|65535] "kWh" Vector__XXX
 SG_ CHR455_19_2_DLTSOCCALC_FIN : 154|7@1+ (1,0) [0|127] "%"  CAB
 SG_ CHR455_18_3_DLTSOCCALC_STRT : 147|7@1+ (1,0) [0|127] "%"  CAB
 SG_ CHR455_18_2_STLMT_TYPE : 146|1@1+ (1,0) [0|1] "" Vector__XXX
 SG_ CHR455_18_1_ACDC_INFO : 145|1@1+ (1,0) [0|1] ""  CAB
 SG_ CHR455_16_6_EVSEOUTPWR : 134|10@1+ (1,0) [0|1023] "kW" Vector__XXX
 SG_ CHR455_13_3_CHG_FINTIM : 107|27@1+ (1,0) [0|134217727] ""  CAB
 SG_ CHR455_12_0_CHGTIM : 96|12@1+ (1,0) [0|63] "min" Vector__XXX
 SG_ CHR455_10_7_DCPWRSUP_PWR_DISP : 87|8@1+ (1,0) [0|255] "kW" Vector__XXX
 SG_ CHR455_8_7_CHGPWR_DISP : 71|16@1+ (1,0) [0|65535] "kW" Vector__XXX
 SG_ CHR455_7_1_DCPWRSUP_ADMTIM : 57|14@1+ (1,0) [0|16383] "min" Vector__XXX
 SG_ CHR455_6_1_CHGSTT : 49|8@1+ (1,0) [0|255] "" Vector__XXX
 SG_ CHR455_5_2_FED_LOLMT : 42|7@1+ (1,0) [0|100] "%" Vector__XXX
 SG_ CHR455_4_6_DCCHG_PWRUPLMT : 38|4@1+ (1,0) [0|15] "" Vector__XXX
 SG_ CHR455_4_2_ACCHG_CURUPLMT : 34|4@1+ (1,0) [0|15] "" Vector__XXX
 SG_ CHR455_3_3_CHG_HILMT : 27|7@1+ (1,0) [0|127] "%" Vector__XXX
 SG_ CHR455_3_1_CHG_CNRLOCSTT : 25|2@1+ (1,0) [0|3] "" Vector__XXX
 SG_ CHR455_3_0_CHG_CNRCNTSTT : 24|1@1+ (1,0) [0|1] "" Vector__XXX
 SG_ CHR455_2_0_E2E_COUNTER : 16|8@1+ (1,0) [0|255] "" Vector__XXX
 SG_ CHR455_0_0_E2E_CRC : 0|16@1+ (1,0) [0|65535] "" Vector__XXX

BO_ 116 BEV074: 8 C_ECU_GW
 SG_ BEV074_7_0_LVPWRDWN : 56|6@1+ (1,0) [0|3] ""  AIL
 SG_ BEV074_7_6_CHRCONSTA : 62|1@1+ (1,0) [0|1] "" Vector__XXX
 SG_ BEV074_7_7_VEHICLE_IGN : 63|1@1+ (1,0) [0|1] "" Vector__XXX
 SG_ BEV074_6_0_EV_CAU : 48|2@1+ (1,0) [0|3] "" Vector__XXX
 SG_ BEV074_6_2_BEV_OBD_CAU : 50|3@1+ (1,0) [0|7] "" Vector__XXX
 SG_ BEV074_6_5_SIDRIVE_DISP : 53|3@1+ (1,0) [0|7] "" Vector__XXX
 SG_ BEV074_5_0_ACCHG_STATE : 40|1@1+ (1,0) [0|1] ""  AIL,CAB
 SG_ BEV074_5_1_DCCHG_STATE : 41|1@1+ (1,0) [0|1] ""  AIL,CAB
 SG_ BEV074_5_2_RANGE_DG : 42|1@1+ (1,0) [0|1] "" Vector__XXX
 SG_ BEV074_5_3_ACCP_DG : 43|1@1+ (1,0) [0|1] "" Vector__XXX
 SG_ BEV074_5_4_REZ_SPD_BK : 44|2@1+ (1,0) [0|3] "" Vector__XXX
 SG_ BEV074_5_6_OBDRDY : 46|1@1+ (1,0) [0|1] "" Vector__XXX
 SG_ BEV074_5_7_FHVB : 47|1@1+ (1,0) [0|1] "" Vector__XXX
 SG_ BEV074_3_0_RANGE_POS : 24|3@1+ (1,0) [0|7] "" Vector__XXX
 SG_ BEV074_3_3_DRVRDY : 27|2@1+ (1,0) [0|3] ""  AIL
 SG_ BEV074_3_5_HVSYSTS : 29|2@1+ (1,0) [0|3] "" Vector__XXX
 SG_ BEV074_3_7_REZ_SPD_GL : 31|9@1- (1,0) [-256|255] "km/h" Vector__XXX
 SG_ BEV074_2_0_ACCP_USR : 16|8@1+ (0.5,0) [0|127.5] "%"  AIL,CAB
 SG_ BEV074_1_0_MSG_COUNTER : 8|4@1+ (1,0) [0|15] ""  AIL
 SG_ BEV074_1_4_RANGE_DG2 : 12|1@1+ (1,0) [0|1] "" Vector__XXX
 SG_ BEV074_1_5_REZ_SPD_BK : 13|3@1+ (1,0) [0|5] "" Vector__XXX
 SG_ BEV074_0_0_CHECK_SUM : 0|8@1+ (1,0) [0|255] ""  AIL

BO_ 2564481223 AIL18DAE0C7: 8 AIL
 SG_ AIL18DAE0C7_DIAG_DATA : 7|64@0+ (1,0) [0|1.844674407371E+19] ""  C_ECU_GW

BO_ 2564474848 DNT18DAC7E0: 8 C_ECU_GW
 SG_ DNT18DAC7E0_DIAG_DATA : 7|64@0+ (1,0) [0|1.844674407371E+19] ""  AIL

BO_ 2564550625 CECU18DBEFE1: 8 C_ECU
 SG_ CECU18DBEFE1_DIAG_DATA : 7|64@0+ (1,0) [0|1.844674407371E+19] ""  AIL,CAB

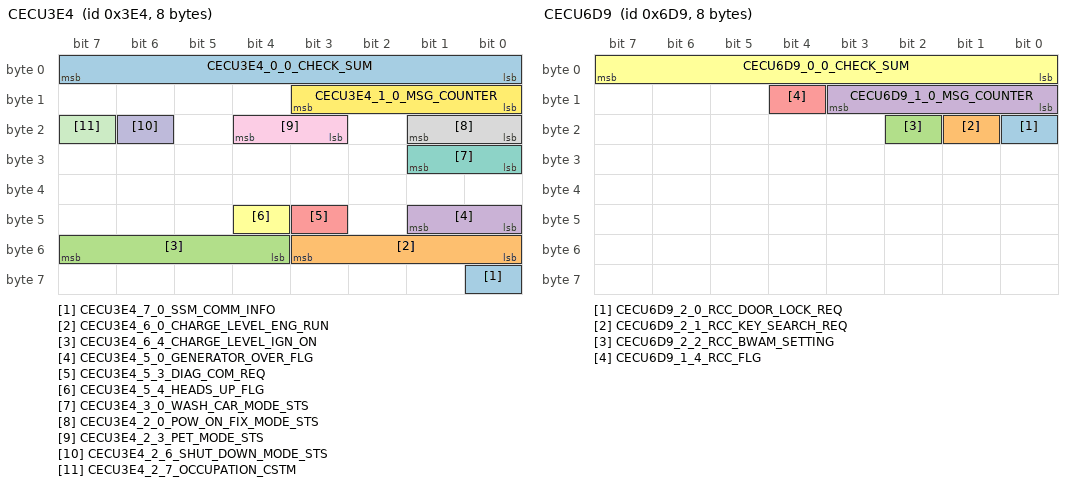
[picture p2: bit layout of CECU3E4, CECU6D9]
BO_ 996 CECU3E4: 8 C_ECU
 SG_ CECU3E4_7_0_SSM_COMM_INFO : 56|1@0+ (1,0) [0|1] ""  AIL
 SG_ CECU3E4_6_0_CHARGE_LEVEL_ENG_RUN : 51|4@0+ (1,0) [0|9] ""  AIL
 SG_ CECU3E4_6_4_CHARGE_LEVEL_IGN_ON : 55|4@0+ (1,0) [0|9] ""  AIL
 SG_ CECU3E4_5_0_GENERATOR_OVER_FLG : 41|2@0+ (1,0) [0|3] ""  AIL
 SG_ CECU3E4_5_3_DIAG_COM_REQ : 43|1@0+ (1,0) [0|1] ""  AIL
 SG_ CECU3E4_5_4_HEADS_UP_FLG : 44|1@0+ (1,0) [0|1] ""  AIL
 SG_ CECU3E4_3_0_WASH_CAR_MODE_STS : 25|2@0+ (1,0) [0|3] "" Vector__XXX
 SG_ CECU3E4_2_0_POW_ON_FIX_MODE_STS : 17|2@0+ (1,0) [0|3] "" Vector__XXX
 SG_ CECU3E4_2_3_PET_MODE_STS : 20|2@0+ (1,0) [0|3] ""  AIL
 SG_ CECU3E4_2_6_SHUT_DOWN_MODE_STS : 22|1@0+ (1,0) [0|1] "" Vector__XXX
 SG_ CECU3E4_2_7_OCCUPATION_CSTM : 23|1@0+ (1,0) [0|1] "" Vector__XXX
 SG_ CECU3E4_1_0_MSG_COUNTER : 11|4@0+ (1,0) [0|15] ""  AIL
 SG_ CECU3E4_0_0_CHECK_SUM : 7|8@0+ (1,0) [0|255] ""  AIL

BO_ 1280 CGW500: 8 C_ECU
 SG_ CGW500_1_4_ActiveWakeUpBit : 12|1@1+ (1,0) [0|1] ""  AIL
 SG_ CGW500_0_0_SourceNodeID : 0|8@1+ (1,0) [0|255] ""  AIL

BO_ 1749 CECU6D5: 8 C_ECU
 SG_ CECU6D5_6_0_CSTM_FMHD : 48|3@1+ (1,0) [0|7] "" Vector__XXX
 SG_ CECU6D5_5_0_CSTM_WRH : 40|1@1+ (1,0) [0|1] "" Vector__XXX
 SG_ CECU6D5_5_1_CSTM_LMHD : 41|2@1+ (1,0) [0|3] ""  AIL
 SG_ CECU6D5_5_3 : 43|2@1+ (1,0) [0|3] ""  AIL
 SG_ CECU6D5_5_5_CSTM_HBA : 45|2@1+ (1,0) [0|3] "" Vector__XXX
 SG_ CECU6D5_5_7_ADB_ACTIVE : 47|1@1+ (1,0) [0|1] "" Vector__XXX
 SG_ CECU6D5_4_0_JUDGE_ILL : 32|1@1+ (1,0) [0|1] "" Vector__XXX
 SG_ CECU6D5_4_1_HEADLAMP_AUTO_SW : 33|1@1+ (1,0) [0|1] "" Vector__XXX
 SG_ CECU6D5_4_2_IND_ACTIVE_HBA : 34|2@1+ (1,0) [0|3] "" Vector__XXX
 SG_ CECU6D5_4_4_FGT_LGTOFF_WARNING : 36|1@1+ (1,0) [0|1] "" Vector__XXX
 SG_ CECU6D5_3_0_CRN_R_REQ : 24|2@1+ (1,0) [0|3] "" Vector__XXX
 SG_ CECU6D5_3_2_CRN_L_REQ : 26|2@1+ (1,0) [0|3] "" Vector__XXX
 SG_ CECU6D5_3_4_FMH : 28|1@1+ (1,0) [0|1] "" Vector__XXX
 SG_ CECU6D5_3_5_LMH : 29|1@1+ (1,0) [0|1] "" Vector__XXX
 SG_ CECU6D5_2_0_LGT_1 : 16|1@1+ (1,0) [0|1] "" Vector__XXX
 SG_ CECU6D5_2_1_LGT_LO : 17|1@1+ (1,0) [0|1] "" Vector__XXX
 SG_ CECU6D5_2_2_LGT_HI : 18|2@1+ (1,0) [0|1] "" Vector__XXX
 SG_ CECU6D5_2_4_FFOG_RELAY_REQ : 20|1@1+ (1,0) [0|1] "" Vector__XXX
 SG_ CECU6D5_2_5_RFOG_RELAY_REQ : 21|1@1+ (1,0) [0|1] "" Vector__XXX
 SG_ CECU6D5_2_6_LGT_DRL : 22|1@1+ (1,0) [0|1] "" Vector__XXX
 SG_ CECU6D5_1_0_MSG_COUNTER : 8|4@1+ (1,0) [0|15] ""  AIL
 SG_ CECU6D5_0_0_CHECK_SUM : 0|8@1+ (1,0) [0|255] ""  AIL

BO_ 1753 CECU6D9: 8 C_ECU
 SG_ CECU6D9_2_0_RCC_DOOR_LOCK_REQ : 16|1@1+ (1,0) [0|1] "" Vector__XXX
 SG_ CECU6D9_2_1_RCC_KEY_SEARCH_REQ : 17|1@1+ (1,0) [0|1] "" Vector__XXX
 SG_ CECU6D9_2_2_RCC_BWAM_SETTING : 18|1@1+ (1,0) [0|1] "" Vector__XXX
 SG_ CECU6D9_1_0_MSG_COUNTER : 8|4@1+ (1,0) [0|15] "" Vector__XXX
 SG_ CECU6D9_1_4_RCC_FLG : 12|1@1+ (1,0) [0|1] "" Vector__XXX
 SG_ CECU6D9_0_0_CHECK_SUM : 0|8@1+ (1,0) [0|255] "" Vector__XXX

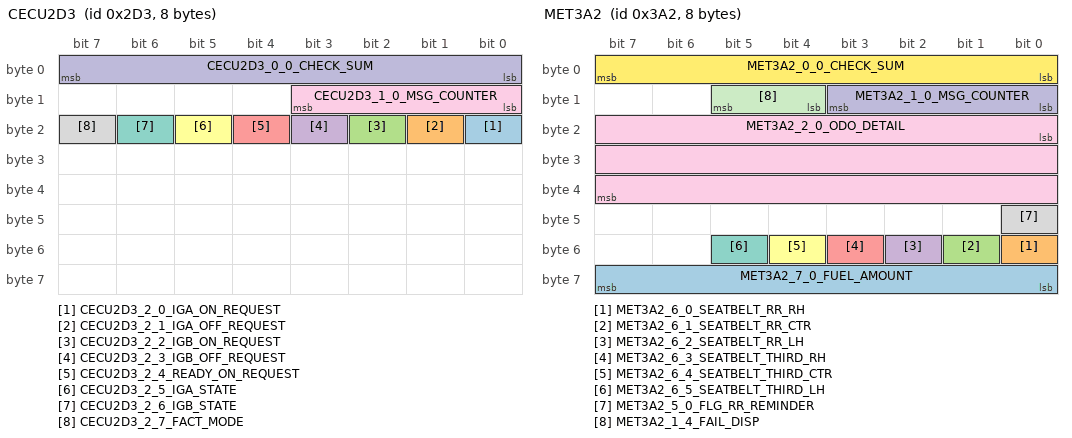
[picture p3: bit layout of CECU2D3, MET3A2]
BO_ 723 CECU2D3: 8 C_ECU
 SG_ CECU2D3_2_0_IGA_ON_REQUEST : 16|1@1+ (1,0) [0|1] "" Vector__XXX
 SG_ CECU2D3_2_1_IGA_OFF_REQUEST : 17|1@1+ (1,0) [0|1] "" Vector__XXX
 SG_ CECU2D3_2_2_IGB_ON_REQUEST : 18|1@1+ (1,0) [0|1] "" Vector__XXX
 SG_ CECU2D3_2_3_IGB_OFF_REQUEST : 19|1@1+ (1,0) [0|1] "" Vector__XXX
 SG_ CECU2D3_2_4_READY_ON_REQUEST : 20|1@1+ (1,0) [0|1] "" Vector__XXX
 SG_ CECU2D3_2_5_IGA_STATE : 21|1@1+ (1,0) [0|1] ""  AIL,CAB
 SG_ CECU2D3_2_6_IGB_STATE : 22|1@1+ (1,0) [0|1] ""  AIL,CAB
 SG_ CECU2D3_2_7_FACT_MODE : 23|1@1+ (1,0) [0|1] "" Vector__XXX
 SG_ CECU2D3_1_0_MSG_COUNTER : 8|4@1+ (1,0) [0|15] ""  AIL
 SG_ CECU2D3_0_0_CHECK_SUM : 0|8@1+ (1,0) [0|255] ""  AIL

BO_ 1739 DCM6CB: 8 C_ECU_GW
 SG_ DCM6CB_7_0 : 56|40@1+ (1,0) [0|1099511627775] "" Vector__XXX
 SG_ DCM6CB_5_0_DKY_SLOT_ID : 40|16@1+ (1,0) [0|65535] "" Vector__XXX
 SG_ DCM6CB_4_0_DKY_COM_REQ : 32|4@1+ (1,0) [0|18] "" Vector__XXX
 SG_ DCM6CB_3_5_PNC_SW_REQ_SRV : 29|3@1+ (1,0) [0|5] "" Vector__XXX
 SG_ DCM6CB_2_0_SHUTDOWN_REQ : 16|1@1+ (1,0) [0|1] "" Vector__XXX
 SG_ DCM6CB_2_3_IGB_OFF_REQUEST : 19|1@1+ (1,0) [0|1] "" Vector__XXX
 SG_ DCM6CB_2_4_IGB_ON_REQUEST : 20|1@1+ (1,0) [0|1] "" Vector__XXX
 SG_ DCM6CB_2_5_REARGATE_UNLOCK_REQ : 21|1@1+ (1,0) [0|1] ""  AIL,CAB
 SG_ DCM6CB_2_6_DOOR_UNLOCK_REQ : 22|1@1+ (1,0) [0|1] ""  AIL,CAB
 SG_ DCM6CB_2_7_DOOR_LOCK_REQUEST : 23|1@1+ (1,0) [0|1] ""  AIL,CAB
 SG_ DCM6CB_1_0_MSG_COUNTER : 8|4@1+ (1,0) [0|15] ""  AIL
 SG_ DCM6CB_1_4_REQ_SVR_HAZARD_ON : 12|1@1+ (1,0) [0|1] ""  AIL,CAB
 SG_ DCM6CB_1_5_HORNHZRD_DEACT_REQ : 13|1@1+ (1,0) [0|1] "" Vector__XXX
 SG_ DCM6CB_1_6_HAZARD_ACT_REQ : 14|1@1+ (1,0) [0|1] "" Vector__XXX
 SG_ DCM6CB_1_7_HORNHAZARD_ACT_REQ : 15|1@1+ (1,0) [0|1] "" Vector__XXX
 SG_ DCM6CB_0_0_CHECK_SUM : 0|8@1+ (1,0) [0|255] ""  AIL

BO_ 1705 MVS6A9: 8 C_ECU_GW
 SG_ MVS6A9_6_0_CSTM_HITCHLINE_DSPREQ : 48|2@1+ (1,0) [0|3] "" Vector__XXX
 SG_ MVS6A9_6_2_CSTM_HITCHLINE : 50|1@1+ (1,0) [0|1] "" Vector__XXX
 SG_ MVS6A9_5_0_RR_WIDE_VIEW_SW_STATE : 40|2@1+ (1,0) [0|3] "" Vector__XXX
 SG_ MVS6A9_5_2_RR_NRW_VIEW_SW_STATE : 42|2@1+ (1,0) [0|3] "" Vector__XXX
 SG_ MVS6A9_5_4_HITCH_VIEW_SW_STATE : 44|2@1+ (1,0) [0|3] "" Vector__XXX
 SG_ MVS6A9_4_0_FT_NRW_VIEW_SW_STATE : 32|2@1+ (1,0) [0|3] "" Vector__XXX
 SG_ MVS6A9_4_2_FT_WIDE_VIEW_SW_STATE : 34|2@1+ (1,0) [0|3] "" Vector__XXX
 SG_ MVS6A9_4_4_SIDE_VIEW_SW_STATE : 36|2@1+ (1,0) [0|3] "" Vector__XXX
 SG_ MVS6A9_4_6_3D_VIEW_SW_STATE : 38|2@1+ (1,0) [0|3] "" Vector__XXX
 SG_ MVS6A9_3_0_CSTM_AUTO_DISPLAY_SET : 24|1@1+ (1,0) [0|1] "" Vector__XXX
 SG_ MVS6A9_3_1_CSTM_AUTO_DISPLAY : 25|1@1+ (1,0) [0|1] "" Vector__XXX
 SG_ MVS6A9_3_2_VIEW_MODE : 26|3@1+ (1,0) [0|3] "" Vector__XXX
 SG_ MVS6A9_3_5_STOP_SWITCH : 29|1@1+ (1,0) [0|1] "" Vector__XXX
 SG_ MVS6A9_3_6_CSTM_HITCH_VIEW : 30|1@1+ (1,0) [0|1] "" Vector__XXX
 SG_ MVS6A9_2_0_CURRENT_VIEW : 16|5@1+ (1,0) [0|31] ""  CAB
 SG_ MVS6A9_2_5_HOLD_TIME : 21|1@1+ (1,0) [0|1] "" Vector__XXX
 SG_ MVS6A9_1_0_MSG_COUNTER : 8|4@1+ (1,0) [0|15] ""  CAB
 SG_ MVS6A9_1_4_FAIL_MVS : 12|1@1+ (1,0) [0|1] ""  CAB
 SG_ MVS6A9_1_5_FAIL_MVS_CAUSE : 13|3@1+ (1,0) [0|7] ""  CAB
 SG_ MVS6A9_0_0_CHECK_SUM : 0|8@1+ (1,0) [0|255] ""  CAB

BO_ 930 MET3A2: 8 C_ECU_GW
 SG_ MET3A2_7_0_FUEL_AMOUNT : 56|8@1+ (1,0) [0|100] "%" Vector__XXX
 SG_ MET3A2_6_0_SEATBELT_RR_RH : 48|1@1+ (1,0) [0|1] "" Vector__XXX
 SG_ MET3A2_6_1_SEATBELT_RR_CTR : 49|1@1+ (1,0) [0|1] "" Vector__XXX
 SG_ MET3A2_6_2_SEATBELT_RR_LH : 50|1@1+ (1,0) [0|1] "" Vector__XXX
 SG_ MET3A2_6_3_SEATBELT_THIRD_RH : 51|1@1+ (1,0) [0|1] "" Vector__XXX
 SG_ MET3A2_6_4_SEATBELT_THIRD_CTR : 52|1@1+ (1,0) [0|1] "" Vector__XXX
 SG_ MET3A2_6_5_SEATBELT_THIRD_LH : 53|1@1+ (1,0) [0|1] "" Vector__XXX
 SG_ MET3A2_5_0_FLG_RR_REMINDER : 40|1@1+ (1,0) [0|1] ""  CAB
 SG_ MET3A2_2_0_ODO_DETAIL : 16|24@1+ (0.1,0) [0|1609103.5] "km" Vector__XXX
 SG_ MET3A2_1_0_MSG_COUNTER : 8|4@1+ (1,0) [0|15] "" Vector__XXX
 SG_ MET3A2_1_4_FAIL_DISP : 12|2@1+ (1,0) [0|3] "" Vector__XXX
 SG_ MET3A2_0_0_CHECK_SUM : 0|8@1+ (1,0) [0|255] "" Vector__XXX

BO_ 1677 MET68D: 8 C_ECU_GW
 SG_ MET68D_7_0_STATUS_WASHER_LAMP : 56|1@1+ (1,0) [0|1] "" Vector__XXX
 SG_ MET68D_7_1_OILPRESSURE_SW : 57|1@1+ (1,0) [0|1] "" Vector__XXX
 SG_ MET68D_7_2_FLG_EAM : 58|1@1+ (1,0) [0|1] "" Vector__XXX
 SG_ MET68D_7_3_CSTM_IND_RED : 59|1@1+ (1,0) [0|1] "" Vector__XXX
 SG_ MET68D_7_4_CSTM_IND_YELLOW : 60|1@1+ (1,0) [0|1] "" Vector__XXX
 SG_ MET68D_7_5_CSTM_IND_GREEN : 61|1@1+ (1,0) [0|1] "" Vector__XXX
 SG_ MET68D_7_6_REQ_CSTM_SRH : 62|1@1+ (1,0) [0|1] "" Vector__XXX
 SG_ MET68D_7_7_CSTM_SRH : 63|1@1+ (1,0) [0|1] "" Vector__XXX
 SG_ MET68D_6_5_REQ_CHG_CSTM_RAB : 53|1@1+ (1,0) [0|1] "" Vector__XXX
 SG_ MET68D_6_6_CSTM_RAB : 54|1@1+ (1,0) [0|1] "" Vector__XXX
 SG_ MET68D_6_7_CSTM_SONNER : 55|1@1+ (1,0) [0|1] "" Vector__XXX
 SG_ MET68D_5_0_TEMP_FOR_PPA : 40|13@1- (0.1,-400) [-400|419.1] "℃" Vector__XXX
 SG_ MET68D_2_0_ODO : 16|24@1+ (0.1,0) [0|999999.9] "km"  CAB
 SG_ MET68D_1_0_MSG_COUNTER : 8|4@1+ (1,0) [0|15] ""  CAB
 SG_ MET68D_1_4_RESET_CSTM_TPMS_RAEB : 12|1@1+ (1,0) [0|1] "" Vector__XXX
 SG_ MET68D_1_5_REQ_CHG_CSTM_TPMS : 13|1@1+ (1,0) [0|1] "" Vector__XXX
 SG_ MET68D_1_6_CSTM_TIRE_UNIT : 14|2@1+ (1,0) [0|3] "" Vector__XXX
 SG_ MET68D_0_0_CHECK_SUM : 0|8@1+ (1,0) [0|255] ""  CAB

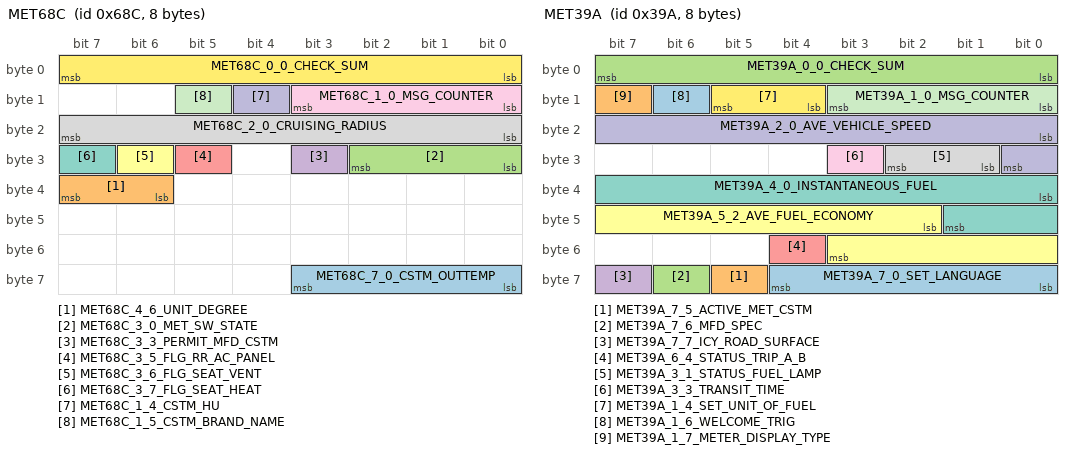
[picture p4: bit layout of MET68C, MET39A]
BO_ 1676 MET68C: 8 C_ECU_GW
 SG_ MET68C_7_0_CSTM_OUTTEMP : 56|4@1+ (1,0) [0|15] "℃" Vector__XXX
 SG_ MET68C_4_6_UNIT_DEGREE : 38|2@1+ (1,0) [0|3] "" Vector__XXX
 SG_ MET68C_3_0_MET_SW_STATE : 24|3@1+ (1,0) [0|3] "" Vector__XXX
 SG_ MET68C_3_3_PERMIT_MFD_CSTM : 27|1@1+ (1,0) [0|1] "" Vector__XXX
 SG_ MET68C_3_5_FLG_RR_AC_PANEL : 29|1@1+ (1,0) [0|1] "" Vector__XXX
 SG_ MET68C_3_6_FLG_SEAT_VENT : 30|1@1+ (1,0) [0|1] "" Vector__XXX
 SG_ MET68C_3_7_FLG_SEAT_HEAT : 31|1@1+ (1,0) [0|1] "" Vector__XXX
 SG_ MET68C_2_0_CRUISING_RADIUS : 16|8@1+ (10,0) [10|2540] "km(mile)"  CAB
 SG_ MET68C_1_0_MSG_COUNTER : 8|4@1+ (1,0) [0|15] ""  CAB
 SG_ MET68C_1_4_CSTM_HU : 12|1@1+ (1,0) [0|1] "" Vector__XXX
 SG_ MET68C_1_5_CSTM_BRAND_NAME : 13|1@1+ (1,0) [0|1] "" Vector__XXX
 SG_ MET68C_0_0_CHECK_SUM : 0|8@1+ (1,0) [0|255] ""  CAB

BO_ 922 MET39A: 8 C_ECU_GW
 SG_ MET39A_7_0_SET_LANGUAGE : 56|5@1+ (1,0) [0|21] "" Vector__XXX
 SG_ MET39A_7_5_ACTIVE_MET_CSTM : 61|1@1+ (1,0) [0|1] "" Vector__XXX
 SG_ MET39A_7_6_MFD_SPEC : 62|1@1+ (1,0) [0|1] "" Vector__XXX
 SG_ MET39A_7_7_ICY_ROAD_SURFACE : 63|1@1+ (1,0) [0|2] ""  CAB
 SG_ MET39A_6_4_STATUS_TRIP_A_B : 52|1@1+ (1,0) [0|1] ""  CAB
 SG_ MET39A_5_2_AVE_FUEL_ECONOMY : 42|10@1+ (0.1,0) [0|99.9] "km/l,l/100km,MPG"  CAB
 SG_ MET39A_4_0_INSTANTANEOUS_FUEL : 32|10@1+ (0.1,0) [0|99.9] "km/l,l/100km,MPG"  CAB
 SG_ MET39A_3_1_STATUS_FUEL_LAMP : 25|2@1+ (1,0) [0|3] ""  CAB
 SG_ MET39A_3_3_TRANSIT_TIME : 27|1@1+ (1,0) [0|1] ""  AIL,CAB
 SG_ MET39A_2_0_AVE_VEHICLE_SPEED : 16|9@1+ (1,0) [0|300] "km/h(MPH)"  AIL,CAB
 SG_ MET39A_1_0_MSG_COUNTER : 8|4@1+ (1,0) [0|15] ""  AIL,CAB
 SG_ MET39A_1_4_SET_UNIT_OF_FUEL : 12|2@1+ (1,0) [0|3] ""  CAB
 SG_ MET39A_1_6_WELCOME_TRIG : 14|1@1+ (1,0) [0|2] ""  AIL,CAB
 SG_ MET39A_1_7_METER_DISPLAY_TYPE : 15|1@1+ (1,0) [0|2] "" Vector__XXX
 SG_ MET39A_0_0_CHECK_SUM : 0|8@1+ (1,0) [0|255] ""  AIL,CAB

BO_ 915 MET393: 8 C_ECU_GW
 SG_ MET393_7_0_REQ_CHG_CSTM_EYE : 56|1@1+ (1,0) [0|1] "" Vector__XXX
 SG_ MET393_7_1_REQ_RESET_CSTM_EYE : 57|1@1+ (1,0) [0|1] "" Vector__XXX
 SG_ MET393_7_2_CSTM_ALK : 58|1@1+ (1,0) [0|1] "" Vector__XXX
 SG_ MET393_7_3_CSTM_HBA : 59|1@1+ (1,0) [0|1] "" Vector__XXX
 SG_ MET393_7_4_CSTM_MIS_AT_BACK : 60|2@1+ (1,0) [0|3] "" Vector__XXX
 SG_ MET393_7_6_CSTM_ACC_CONT : 62|2@1+ (1,0) [0|3] "" Vector__XXX
 SG_ MET393_6_0_R_DIFF_TEMP : 48|8@1+ (1,-50) [-50|200] "℃" Vector__XXX
 SG_ MET393_5_2_WARN_R_DIFF_TEMP : 42|2@1+ (1,0) [0|3] "" Vector__XXX
 SG_ MET393_5_4_ADAPTIVECC_NOALIVE : 44|1@1+ (1,0) [0|1] "" Vector__XXX
 SG_ MET393_5_5_DUAL_RANGE_LO : 45|1@1+ (1,0) [0|1] "" Vector__XXX
 SG_ MET393_5_6_CSTM_SPD_LIMITER : 46|1@1+ (1,0) [0|1] "" Vector__XXX
 SG_ MET393_5_7_CSTM_LANE_CONT : 47|1@1+ (1,0) [0|1] "" Vector__XXX
 SG_ MET393_4_0_FUEL_LEVEL_RESIST : 32|10@1+ (0.5,0) [0|480] "ohm" Vector__XXX
 SG_ MET393_3_5_SI_DRIVE_SW : 29|3@1+ (1,0) [0|7] ""  AIL
 SG_ MET393_2_0_OUTTEMP_FOR_DIAG : 16|13@1+ (0.1,-400) [-400|419.1] "℃"  CAB
 SG_ MET393_1_0_MSG_COUNTER : 8|4@1+ (1,0) [0|15] ""  AIL,CAB
 SG_ MET393_1_4_CSTM_IND_BLUE : 12|1@1+ (1,0) [0|1] "" Vector__XXX
 SG_ MET393_1_5_CSTM_AES_CONT : 13|1@1+ (1,0) [0|1] "" Vector__XXX
 SG_ MET393_1_6_FLG_PEDESTRIAN_AIRBAG : 14|1@1+ (1,0) [0|1] "" Vector__XXX
 SG_ MET393_0_0_CHECK_SUM : 0|8@1+ (1,0) [0|255] ""  AIL,CAB

BO_ 912 MET390: 8 C_ECU_GW
 SG_ MET390_7_0_VDC_ON_OFF : 56|2@1+ (1,0) [0|3] "" Vector__XXX
 SG_ MET390_7_2_RR_DOOR_RECORD_L : 58|1@1+ (1,0) [0|1] "" Vector__XXX
 SG_ MET390_7_3_RR_DOOR_RECORD_R : 59|1@1+ (1,0) [0|1] "" Vector__XXX
 SG_ MET390_7_4_REQ_CHG_CSTM_PSM : 60|1@1+ (1,0) [0|1] "" Vector__XXX
 SG_ MET390_7_5_REQ_RESET_CSTM_PSM : 61|1@1+ (1,0) [0|1] "" Vector__XXX
 SG_ MET390_7_6_CSTM_MIR_AFOLD_CONT : 62|1@1+ (1,0) [0|1] "" Vector__XXX
 SG_ MET390_7_7_CSTM_MIR_RTILT_CONT : 63|1@1+ (1,0) [0|1] "" Vector__XXX
 SG_ MET390_6_0_SEATBELT_DRVR : 48|1@1+ (1,0) [0|1] ""  AIL,CAB
 SG_ MET390_6_1_SEATBELT_PASS : 49|1@1+ (1,0) [0|1] ""  AIL,CAB
 SG_ MET390_6_2_TURN_SIG_LEFT : 50|1@1+ (1,0) [0|1] ""  CAB
 SG_ MET390_6_3_TURN_SIG_RIGHT : 51|1@1+ (1,0) [0|1] ""  CAB
 SG_ MET390_6_4_BRIGHT_SW : 52|1@1+ (1,0) [0|1] ""  AIL,CAB
 SG_ MET390_6_5_FAIL_UART_WA_BOX : 53|1@1+ (1,0) [0|1] "" Vector__XXX
 SG_ MET390_6_6_ISS_OFF_SW : 54|1@1+ (1,0) [0|1] "" Vector__XXX
 SG_ MET390_6_7_FLG_DMS : 55|1@1+ (1,0) [0|1] "" Vector__XXX
 SG_ MET390_5_0_ILL_BRIGHTNESS : 40|8@1+ (0.4,0) [0|100] "%"  AIL,CAB
 SG_ MET390_4_0_OUTTEMP_FOR_IND : 32|8@1+ (0.5,-40) [-40|80] "℃"  AIL,CAB
 SG_ MET390_3_0_UNIT_SPEED_TRIP : 24|1@1+ (1,0) [0|1] ""  AIL,CAB
 SG_ MET390_3_1_FLG_EYESIGHT : 25|1@1+ (1,0) [0|1] "" Vector__XXX
 SG_ MET390_3_2_FLG_ISS : 26|1@1+ (1,0) [0|1] "" Vector__XXX
 SG_ MET390_3_3_FLG_HEV : 27|1@1+ (1,0) [0|1] "" Vector__XXX
 SG_ MET390_3_4_FLG_IMB : 28|1@1+ (1,0) [0|1] "" Vector__XXX
 SG_ MET390_3_5_TIRE_SIZE : 29|1@1+ (1,0) [0|1] "" Vector__XXX
 SG_ MET390_3_6_FLG_XMODE : 30|2@1+ (1,0) [0|3] "" Vector__XXX
 SG_ MET390_2_0_VEHICLE_SERIES : 16|3@1+ (1,0) [0|7] "" Vector__XXX
 SG_ MET390_2_3_DESTINATION : 19|4@1+ (1,0) [0|12] "" Vector__XXX
 SG_ MET390_2_7_PASS_DOOR_RECORD : 23|1@1+ (1,0) [0|1] "" Vector__XXX
 SG_ MET390_1_0_MSG_COUNTER : 8|4@1+ (1,0) [0|15] ""  AIL,CAB
 SG_ MET390_1_4_WAKE_UP_FRAME : 12|1@1+ (1,0) [0|1] "" Vector__XXX
 SG_ MET390_1_5_REQ_COMM_CONT : 13|1@1+ (1,0) [0|1] "" Vector__XXX
 SG_ MET390_1_6_DMS_ID_SET : 14|1@1+ (1,0) [0|1] "" Vector__XXX
 SG_ MET390_1_7_FAIL_EEPROM : 15|1@1+ (1,0) [0|1] "" Vector__XXX
 SG_ MET390_0_0_CHECK_SUM : 0|8@1+ (1,0) [0|255] ""  AIL,CAB

CM_ SG_ 552 RDR228_7_0_EYE_TIMEOUT_ERROR_FLG "後側方ﾚｰﾀﾞ ｱｲｻｲﾄﾃﾞｰﾀ未着・異常検知ﾌﾗｸﾞ
";
CM_ SG_ 552 RDR228_7_1_BLOCKAGE_FORMING_2 "ﾌﾞﾛｯｹｰｼﾞ2条件成立ﾌﾗｸﾞ
";
CM_ SG_ 552 RDR228_7_2_WARN_LCA_R_1ST "右側LCA警報1次ﾌﾗｸﾞ（注意喚起）
";
CM_ SG_ 552 RDR228_7_3_WARN_LCA_L_1ST "左側LCA警報1次ﾌﾗｸﾞ（注意喚起）
";
CM_ SG_ 552 RDR228_7_4_WARN_LCA_R_2ND "右側LCA警報2次ﾌﾗｸﾞ（ｳｨﾝｶｰON）
";
CM_ SG_ 552 RDR228_7_5_WARN_LCA_L_2ND "左側LCA警報2次ﾌﾗｸﾞ（ｳｨﾝｶｰON）
";
CM_ SG_ 552 RDR228_7_6_WARN_RCTA_R "右RCTA警報ﾌﾗｸﾞ
";
CM_ SG_ 552 RDR228_7_7_WARN_RCTA_L "左RCTA警報ﾌﾗｸﾞ
";
CM_ SG_ 552 RDR228_6_0_WARN_BSD_R_1ST "右側BSD警報ﾌﾗｸﾞ(注意喚起)
";
CM_ SG_ 552 RDR228_6_1_WARN_BSD_L_1ST "左側BSD警報ﾌﾗｸﾞ(注意喚起)
";
CM_ SG_ 552 RDR228_6_2_WARN_BSD_R_2ND "右側BSD警報2次ﾌﾗｸﾞ(ｳｨﾝｶｰON)
";
CM_ SG_ 552 RDR228_6_3_WARN_BSD_L_2ND "左側BSD警報2次ﾌﾗｸﾞ(ｳｨﾝｶｰON)
";
CM_ SG_ 552 RDR228_6_5_BLOCKAGE_STS "ﾌﾞﾛｯｹｰｼﾞｽﾃｰﾀｽ
";
CM_ SG_ 552 RDR228_5_0_BSD_R_E "右側BSDﾌﾗｸﾞ(EYE-ELK用)
";
CM_ SG_ 552 RDR228_5_1_BSD_L_E "左側BSDﾌﾗｸﾞ(EYE-ELK用)
";
CM_ SG_ 552 RDR228_5_2_LCA_R_E "右側LCAﾌﾗｸﾞ(EYE-ELK用)
";
CM_ SG_ 552 RDR228_5_3_LCA_L_E "左側LCAﾌﾗｸﾞ(EYE-ELK用)
";
CM_ SG_ 552 RDR228_5_4_BSD_R_A "右側BSDﾌﾗｸﾞ(EYE-AES用)
";
CM_ SG_ 552 RDR228_5_5_BSD_L_A "左側BSDﾌﾗｸﾞ(EYE-AES用)
";
CM_ SG_ 552 RDR228_5_6_LCA_R_A "右側LCAﾌﾗｸﾞ(EYE-AES用)
";
CM_ SG_ 552 RDR228_5_7_LCA_L_A "左側LCAﾌﾗｸﾞ(EYE-AES用)
";
CM_ SG_ 552 RDR228_4_0_DOW_ACTIVELAMP "DOW Active灯表示ﾌﾗｸﾞ
";
CM_ SG_ 552 RDR228_4_1_WARN_DOW_1ST_R "右側DOW警報1次ﾌﾗｸﾞ
";
CM_ SG_ 552 RDR228_4_2_WARN_DOW_1ST_L "左側DOW警報1次ﾌﾗｸﾞ
";
CM_ SG_ 552 RDR228_4_3_WARN_DOW_2ST_R "右側DOW警報2次ﾌﾗｸﾞ
";
CM_ SG_ 552 RDR228_4_4_WARN_DOW_2ST_L "左側DOW警報2次ﾌﾗｸﾞ
";
CM_ SG_ 552 RDR228_4_5_CSTM_STS_SRVD "ｶｽﾀﾏｲｽﾞ状態－BSD/LCA警報ON-OFF
";
CM_ SG_ 552 RDR228_4_6_CSTM_STS_BSD_LCA_2ND "ｶｽﾀﾏｲｽﾞ状態－BSD/LCA2次ﾌﾞｻﾞｰON-OFF
";
CM_ SG_ 552 RDR228_4_7_CSTM_STS_RCTA "ｶｽﾀﾏｲｽﾞ状態－RCTA　ON-OFF
";
CM_ SG_ 552 RDR228_3_0_WARN_BSD_LCA_R_2ND "右側BSD/LCA2次ﾌﾞｻﾞｰﾌﾗｸﾞ
";
CM_ SG_ 552 RDR228_3_1_WARN_BSD_LCA_L_2ND "左側BSD/LCA2次ﾌﾞｻﾞｰﾌﾗｸﾞ
";
CM_ SG_ 552 RDR228_3_2_CSTM_STS_DOW "ｶｽﾀﾏｲｽﾞ状態－DOW　ON-OFF
";
CM_ SG_ 552 RDR228_3_3_CSTM_STS_DOW_SFT_POS "ｶｽﾀﾏｲｽﾞ状態－DOW有効ｼﾌﾄﾎﾟｼﾞｼｮﾝ
";
CM_ SG_ 552 RDR228_3_5_CSTM_DSP_BSD_LCA "ｶｽﾀﾏｲｽﾞ表示有効－BSD/LCA警報
";
CM_ SG_ 552 RDR228_3_6_CSTM_DSP_BSD_LCA_2ND "ｶｽﾀﾏｲｽﾞ表示有効－BSD/LCA2次ﾌﾞｻﾞｰ
";
CM_ SG_ 552 RDR228_3_7_CSTM_DSP_RCTA "ｶｽﾀﾏｲｽﾞ表示有効－RCTA
";
CM_ SG_ 552 RDR228_2_0_CSTM_DSP_DOW "ｶｽﾀﾏｲｽﾞ表示有効－DOW
";
CM_ SG_ 552 RDR228_2_1_EYE_LOCAL_BUS1_FAIL "後側方ﾚｰﾀﾞ ｱｲｻｲﾄﾛｰｶﾙBUS1異常検知ﾌﾗｸﾞ
";
CM_ SG_ 552 RDR228_2_2_CSTM_DSP_DOW_SFT_POS "ｶｽﾀﾏｲｽﾞ表示有効－DOW有効ｼﾌﾄﾎﾟｼﾞｼｮﾝ
";
CM_ SG_ 552 RDR228_2_3_ELK_STOP_REQ_FLG "後側方ﾚｰﾀﾞELK停止要求ﾌﾗｸﾞ
";
CM_ SG_ 552 RDR228_2_4_FAIL_RDRSYS "後側方ﾚｰﾀﾞｼｽﾃﾑﾌｪｰﾙﾌﾗｸﾞ
";
CM_ SG_ 552 RDR228_2_5_STOP_RDRSYS "後側方ﾚｰﾀﾞｼｽﾃﾑ一時停止ﾌﾗｸﾞ
";
CM_ SG_ 552 RDR228_2_6_ON_OFF_RDRSYS "後側方ﾚｰﾀﾞｼｽﾃﾑON-OFFﾌﾗｸﾞ
";
CM_ SG_ 552 RDR228_2_7_BLOCKAGE_FORMING "ﾌﾞﾛｯｹｰｼﾞ条件成立ﾌﾗｸﾞ
";
CM_ SG_ 552 RDR228_1_0_MSG_COUNTER "ﾒｯｾｰｼﾞｶｳﾝﾀ
";
CM_ SG_ 552 RDR228_1_4_BATT_OFF_CAUSE "DOW電源OFF要求ﾌﾗｸﾞ
";
CM_ SG_ 552 RDR228_1_5_CSTM_GLO_1 "ｶｽﾀﾏｲｽﾞ表示ｸﾞﾚｰｱｳﾄ－1
";
CM_ SG_ 552 RDR228_1_6_CSTM_GLO_3 "ｶｽﾀﾏｲｽﾞ表示ｸﾞﾚｰｱｳﾄ－3
";
CM_ SG_ 552 RDR228_1_7_CSTM_GLO_2 "ｶｽﾀﾏｲｽﾞ表示ｸﾞﾚｰｱｳﾄ－2
";
CM_ SG_ 552 RDR228_0_0_CHECK_SUM "ﾁｪｯｸｻﾑ
";
CM_ SG_ 967 EYE3C7_7_3_WARN_ESCALATION_REQ "警報エスカレーション連動
";
CM_ SG_ 967 EYE3C7_7_6_AEB_MSB_LINK "AEB連動信号
";
CM_ SG_ 967 EYE3C7_4_0_LKS_DMS_COOPERATION "LKS_DMS連携有無
";
CM_ SG_ 967 EYE3C7_4_1_LKS_ACTIVE "LKSアクティブ状態
";
CM_ SG_ 967 EYE3C7_2_0_ALC_CONTROL "ALC制御状態
";
CM_ SG_ 967 EYE3C7_2_1_WINKER_OFF_REQ "ウィンカー消灯要求
";
CM_ SG_ 967 EYE3C7_2_2_HORN_HAZARD_ON_REQ "ホーンハザード駆動要求
";
CM_ SG_ 967 EYE3C7_2_4_DR_UNLOCK_REQ "ドアアンロック要求
";
CM_ SG_ 967 EYE3C7_2_5_WINKER_ON_REQ "ウィンカー点灯要求
";
CM_ SG_ 967 EYE3C7_2_7_MRM_ACTIVE "MRMアクティブ状態
";
CM_ SG_ 967 EYE3C7_1_0_MSG_COUNTER "ﾒｯｾｰｼﾞｶｳﾝﾀ
";
CM_ SG_ 967 EYE3C7_0_0_CHECK_SUM "ﾁｪｯｸｻﾑ
";
CM_ SG_ 966 EYE3C6_7_0_VEHICLE_DIST_L_LANE1 "左車線先行車１縦位置
";
CM_ SG_ 966 EYE3C6_7_7_VEHICLE_L_LANE1 "左車線先行車１
";
CM_ SG_ 966 EYE3C6_6_0_VEHICLE_DIST_R_LANE1 "右車線先行車１縦位置
";
CM_ SG_ 966 EYE3C6_6_7_VEHICLE_R_LANE1 "右車線先行車１
";
CM_ SG_ 966 EYE3C6_5_0_VEHICLE_DIST_WY_WAY1 "自車線先行車１縦位置
";
CM_ SG_ 966 EYE3C6_5_7_VEHICLE_MY_WAY1 "自車線先行車１
";
CM_ SG_ 966 EYE3C6_4_0_SIDE_MOVEMENT "自車表示_位置
";
CM_ SG_ 966 EYE3C6_3_0_RADER_RR "後側方レーダ-_右
";
CM_ SG_ 966 EYE3C6_3_2_RADER_RL "後側方レーダ-_左
";
CM_ SG_ 966 EYE3C6_3_4_RADER_FR "前側方レーダ-_右
";
CM_ SG_ 966 EYE3C6_3_6_RADER_FL "前側方レーダ-_左
";
CM_ SG_ 966 EYE3C6_2_0_RADER_R "後方レーダ-
";
CM_ SG_ 966 EYE3C6_2_2_MY_WAY_LANE_CAR_COLOR "自車線車両色
";
CM_ SG_ 966 EYE3C6_2_4_TARGET_CAR "先行車ターゲット
";
CM_ SG_ 966 EYE3C6_2_7_ALC_STS "ALC状態
";
CM_ SG_ 966 EYE3C6_1_0_MSG_COUNTER "ﾒｯｾｰｼﾞｶｳﾝﾀ
";
CM_ SG_ 966 EYE3C6_1_4_L_LANE_CAR_COLOR "左車線車両色
";
CM_ SG_ 966 EYE3C6_1_6_R_LANE_CAR_COLOR "右車線車両色
";
CM_ SG_ 966 EYE3C6_0_0_CHECK_SUM "ﾁｪｯｸｻﾑ
";
CM_ SG_ 965 EYE3C5_7_0_GSR_AEBS_FUNC_INFO "GSR-AEBS機能有無フラグ
";
CM_ SG_ 965 EYE3C5_7_1_CSTM_CRV_ADJUST "カスタマイズ現在値(カーブ前減速度調整機能)
";
CM_ SG_ 965 EYE3C5_7_3_BRAKE_HAPTIC_CURR "カスタマイズ現在値設定(ブレーキハプティック)
";
CM_ SG_ 965 EYE3C5_7_5_SAFETY_MODE_FUNC_INFO "障害物なし加速抑制機能有無フラグ
";
CM_ SG_ 965 EYE3C5_7_6_SAFETY_MODE_CURR "カスタマイズ現在値設定(障害物なし加速抑制)
";
CM_ SG_ 965 EYE3C5_7_7_GSR_DDAW_FUNC_INFO "GSR-DDAW機能有無フラグ
";
CM_ SG_ 965 EYE3C5_6_0_IND_SAFETY_MODE "アクセル急踏み加速抑制機能ON灯
";
CM_ SG_ 965 EYE3C5_6_1_ALC_ACTIVE_L "ALC制御中表示_左
";
CM_ SG_ 965 EYE3C5_6_2_FLASHING_IND_SAFETY "安全重視モード点滅表示指示
";
CM_ SG_ 965 EYE3C5_6_3_OVERTAKE_FUNC_INFO "追い抜き抑制制御有無フラグ
";
CM_ SG_ 965 EYE3C5_6_4_CRV_ADJUST_FUNC_INFO "カーブ前減速度調整機能有無フラグ
";
CM_ SG_ 965 EYE3C5_6_5_STRG_TOUCHSENSOR_WRNG "ステアリングタッチセンサ故障灯
";
CM_ SG_ 965 EYE3C5_6_6_ALC_ACTIVE_R "ALC制御中表示_右
";
CM_ SG_ 965 EYE3C5_6_7_CSTM_GSR_ISA "GSR-ISA有無フラグ
";
CM_ SG_ 965 EYE3C5_5_0_LANE_COLOR_R "隣レーン色_右
";
CM_ SG_ 965 EYE3C5_5_2_LINE_LANE_R "隣外側車線表示_右
";
CM_ SG_ 965 EYE3C5_5_4_LANE_COLOR_L "隣レーン色_左
";
CM_ SG_ 965 EYE3C5_5_6_LINE_LANE_L "隣外側車線表示_左
";
CM_ SG_ 965 EYE3C5_4_0_ROAD_SHAPE_CURVE "道路形状_湾曲
";
CM_ SG_ 965 EYE3C5_4_4_ROAD_SHAPE_DIRECTION "道路形状_方向
";
CM_ SG_ 965 EYE3C5_4_5_CSTM_GSR_ELKS "GSR-ELKS有無フラグ
";
CM_ SG_ 965 EYE3C5_4_6_MY_WAY_COLOR "自レーンの色
";
CM_ SG_ 965 EYE3C5_3_0_AD_DRV_ICON "高度運転支援アイコン
";
CM_ SG_ 965 EYE3C5_3_2_AUTO_HANDLE_ICON "AUTOハンドルアイコン
";
CM_ SG_ 965 EYE3C5_3_4_WITH_HANDS_ICON "ハンズオン/ハンズオフ表示
";
CM_ SG_ 965 EYE3C5_3_5_STRG_HAPTIC_WRNG "ステアリングハプティック故障灯
";
CM_ SG_ 965 EYE3C5_3_6_BRK_HPTC_FUNC_INFO "ブレーキハプティック機能有無フラグ
";
CM_ SG_ 965 EYE3C5_3_7_SPECIAL_DISP_INFO "特殊標識表示機能有無フラグ
";
CM_ SG_ 965 EYE3C5_2_0_SLOWDWN_CURVE_ICON "カーブ前減速アイコン
";
CM_ SG_ 965 EYE3C5_2_3_FLASHING_IND "自車点滅指示
";
CM_ SG_ 965 EYE3C5_2_4_ATTENTION_TOLLGATE "料金所注意アイコン
";
CM_ SG_ 965 EYE3C5_2_6_MAPLOCATOR_IND "ロケータインジケータ
";
CM_ SG_ 965 EYE3C5_1_0_MSG_COUNTER "ﾒｯｾｰｼﾞｶｳﾝﾀ
";
CM_ SG_ 965 EYE3C5_1_4_ISA_FAIL_IND "ISA故障灯
";
CM_ SG_ 965 EYE3C5_1_5_SLWF_OFF_IND "SLWFOFF灯
";
CM_ SG_ 965 EYE3C5_1_6_CSTM_SLWF_SET "カスタマイズ現在値(SLWF)
";
CM_ SG_ 965 EYE3C5_1_7_CSTM_TSR_SOUND_SET "カスタマイズ現在値(標識切り替わり警報音)
";
CM_ SG_ 965 EYE3C5_0_0_CHECK_SUM "ﾁｪｯｸｻﾑ
";
CM_ SG_ 964 EYE3C4_7_0_PCR_FAIL_OFF_IND "プリクラ故障/OFF灯指示
";
CM_ SG_ 964 EYE3C4_7_2_AES_FAIL_OFF_IND "AES故障/OFF灯指示
";
CM_ SG_ 964 EYE3C4_7_4_LDP_FAIL_OFF_IND "LDP故障/OFF灯指示
";
CM_ SG_ 964 EYE3C4_7_6_ELK_FAIL_OFF_IND "ELK故障/OFF灯指示
";
CM_ SG_ 964 EYE3C4_6_0_MCAM_SYS_FAIL_HALT "単眼故障状態通知(HALT/FAIL)
";
CM_ SG_ 964 EYE3C4_6_2_MCAM_FUNC_INFO "単眼機能有無フラグ
";
CM_ SG_ 964 EYE3C4_6_3_EYE_DRV_ACTION_REQ "アイサイトドライバアクション要求
";
CM_ SG_ 964 EYE3C4_6_6_LDW_SND_OFF_FAIL_IND "LDW音OFF灯/SW故障警告表示
";
CM_ SG_ 964 EYE3C4_5_0_EAM_GREEN "EAM点灯指示　緑
";
CM_ SG_ 964 EYE3C4_5_2_EAM_BLUE "EAM点灯指示　青
";
CM_ SG_ 964 EYE3C4_5_4_EAM_GREEN_2 "EAM点灯指示_緑2
";
CM_ SG_ 964 EYE3C4_5_6_FCW_SND_OFF_FAIL_IND "FCW音OFF灯/SW故障警告表示
";
CM_ SG_ 964 EYE3C4_4_0_EAM_YELLOW "EAM点灯指示　黄
";
CM_ SG_ 964 EYE3C4_4_4_EAM_RED "EAM点灯指示　赤
";
CM_ SG_ 964 EYE3C4_3_0_CODE_NO_BUZZER "警報コード（表示のみ）
";
CM_ SG_ 964 EYE3C4_2_0_CODE_WARN "警報コード（音有）
";
CM_ SG_ 964 EYE3C4_1_0_MSG_COUNTER "ﾒｯｾｰｼﾞｶｳﾝﾀ
";
CM_ SG_ 964 EYE3C4_1_5_SNR_DRV_ACTION_REQ "ソナードライバアクション要求
";
CM_ SG_ 964 EYE3C4_0_0_CHECK_SUM "ﾁｪｯｸｻﾑ
";
CM_ SG_ 806 EYE326_5_0_TIME "時刻情報
";
CM_ SG_ 806 EYE326_4_3_DAY "日付情報：日
";
CM_ SG_ 806 EYE326_3_0_YEAR "日付情報：年
";
CM_ SG_ 806 EYE326_3_7_MONTH "日付情報：月
";
CM_ SG_ 806 EYE326_2_0_MRM_OPE_ST "MRM動作状態
";
CM_ SG_ 806 EYE326_2_1_DRIVER_TORQUE_STATE "ドライバートルク状態
";
CM_ SG_ 806 EYE326_2_3_DRIVER_ACCEL_STATE "ドライバーアクセル状態
";
CM_ SG_ 806 EYE326_1_0_MSG_COUNTER "ﾒｯｾｰｼﾞｶｳﾝﾀ
";
CM_ SG_ 806 EYE326_1_4_SYS_ST "システム状態
";
CM_ SG_ 806 EYE326_1_5_TAKE_OVR_REQ "引継要求
";
CM_ SG_ 806 EYE326_1_7_OVERRIDE "オーバライド
";
CM_ SG_ 806 EYE326_0_0_CHECK_SUM "ﾁｪｯｸｻﾑ
";
CM_ SG_ 805 EYE325_6_5_SONAR_DISP_INT "ｸﾘｿﾅ割り込み表示ﾌﾗｸﾞ
";
CM_ SG_ 805 EYE325_5_0_SONAR_R_L_CORNER_4LVL "リアソナー距離警報情報(左コーナー4段階)
";
CM_ SG_ 805 EYE325_5_3_SONAR_R_R_CORNER_4LVL "リアソナー距離警報情報(右コーナー4段階)
";
CM_ SG_ 805 EYE325_4_0_SONAR_R_CENTER "ﾘｱｿﾅｰ距離警報情報：Rcenter（中央4段階）
";
CM_ SG_ 805 EYE325_4_3_SONAR_LEVEL "RAB/ｸﾘｿﾅ警報音ﾚﾍﾞﾙ
";
CM_ SG_ 805 EYE325_4_6_RAB_WARNING "RAB警報割込み表示指示
";
CM_ SG_ 805 EYE325_3_0_SONAR_R_L_CORNER "ﾘｱｿﾅｰ距離警報情報：RLConner（左ｺｰﾅ3段階）
";
CM_ SG_ 805 EYE325_3_2_SONAR_R_R_CORNER "ﾘｱｿﾅｰ距離警報情報：RRConner（右ｺｰﾅ3段階）
";
CM_ SG_ 805 EYE325_3_4_SONAR_R_L_SIDE "ﾘｱｿﾅｰ距離警報情報：RLSide（左ｻｲﾄﾞ3段階：予約）
";
CM_ SG_ 805 EYE325_3_6_SONAR_R_R_SIDE "ﾘｱｿﾅｰ距離警報情報：RRSide（右ｻｲﾄﾞ3段階：予約）
";
CM_ SG_ 805 EYE325_2_0_RAB_OFF "RAB 機能OFF状態通知
";
CM_ SG_ 805 EYE325_2_1_SONAR_OFF "警報音機能OFF状態通知
";
CM_ SG_ 805 EYE325_2_2_SONAR_SYS_HALT "ｿﾅｰｼｽﾃﾑ一時停止状態通知 (Fault)
";
CM_ SG_ 805 EYE325_2_4_SONAR_SYS_FAIL "ｿﾅｰｼｽﾃﾑ故障状態通知 (Fail)
";
CM_ SG_ 805 EYE325_2_6_RAB_DISABLE "RAB機能一時OFF操作不可
";
CM_ SG_ 805 EYE325_2_7_SONAR_DISABLE "警報音一時OFF操作不可
";
CM_ SG_ 805 EYE325_1_0_MSG_COUNTER "ﾒｯｾｰｼﾞｶｳﾝﾀ
";
CM_ SG_ 805 EYE325_1_4_CSTM_RAB_SET "SNRｶｽﾀﾏｲｽﾞ現在値設定(RAB機能)
";
CM_ SG_ 805 EYE325_1_5_CSTM_CLR_SNR_SET "SNRｶｽﾀﾏｲｽﾞ現在値設定(ｸﾘｱﾗﾝｽｿﾅｰ機能)
";
CM_ SG_ 805 EYE325_1_6_RAB "RAB機能設定ﾌﾗｸﾞ
";
CM_ SG_ 805 EYE325_1_7_SONAR_NO_DISP "ｿﾅｰｼｽﾃﾑ画面非表示ﾌﾗｸﾞ
";
CM_ SG_ 805 EYE325_0_0_CHECK_SUM "ﾁｪｯｸｻﾑ
";
CM_ SG_ 803 EYE323_7_0_ISA_OFFSET_CURR "ISA制限車速オフセット値
";
CM_ SG_ 803 EYE323_7_5_SLIF_FUNC_INFO "標識認識機能有無情報
";
CM_ SG_ 803 EYE323_7_6_ISA_FUNC_INFO "ISA機能有無情報
";
CM_ SG_ 803 EYE323_7_7_ISA_CUSTOMIZE_CURR "ｱｲｻｲﾄｶｽﾀﾏｲｽﾞ現在設定値(ISA)
";
CM_ SG_ 803 EYE323_6_0_LDW_OFFSW_INFO "LDW音　OFFスイッチ有無
";
CM_ SG_ 803 EYE323_6_1_LDW_ON_OFF_SET "LDW音 ON/OFF現在設定値
";
CM_ SG_ 803 EYE323_6_2_CSTM_DDAW_WARN_SET "カスタマイズ現在値(DDAW警報)
";
CM_ SG_ 803 EYE323_6_3_IACC_FUNC_INFO "iACC機能有無フラグ
";
CM_ SG_ 803 EYE323_6_5_CSTM_LDW_TIMING_SET "LDWタイミングカスタマイズ現在設定値
";
CM_ SG_ 803 EYE323_6_6_CSTM_LDW_TIMING "LDWタイミングカスタマイズ有無
";
CM_ SG_ 803 EYE323_6_7_SLOWDOWNL_FUNC_INFO "カーブ前減速機能有無
";
CM_ SG_ 803 EYE323_5_0_CNG_GRN_CONT_CURR "カスタマイズ現在値（青信号切り替わりお知らせ）
";
CM_ SG_ 803 EYE323_5_1_TRAFFIC_FUNC_INFO "信号制御機能有無
";
CM_ SG_ 803 EYE323_5_2_FCW_OFFSW_INFO "FCW OFFスイッチ有無
";
CM_ SG_ 803 EYE323_5_3_FCW_ON_OFF_SET "FCW ON/OFF現在設定値
";
CM_ SG_ 803 EYE323_5_4_WARNING_SEL_CURR "カスタマイズ現在値（警報方法）
";
CM_ SG_ 803 EYE323_5_5_HAPT_FUNC_INFO "ステア振動（警報方法）機能有無
";
CM_ SG_ 803 EYE323_5_6_TOLLGATE_CONT_CURR "カスタマイズ現在値（料金所減速 ）
";
CM_ SG_ 803 EYE323_5_7_CURVE_CONT_CURR "カスタマイズ現在値（カーブ減速 ）
";
CM_ SG_ 803 EYE323_4_0_FCTB_ICON_L "FCTBお知らせアイコン_左
";
CM_ SG_ 803 EYE323_4_2_FCTB_ICON_R "FCTBお知らせアイコン_右
";
CM_ SG_ 803 EYE323_4_4_FCW_CONT_CURR "カスタマイズ現在値（FCW)
";
CM_ SG_ 803 EYE323_4_6_FCW_DISPLAY_SEL "FCWカスタマイズ項目表示指示
";
CM_ SG_ 803 EYE323_3_0_AES_FUNC_INFO "AES機能有無
";
CM_ SG_ 803 EYE323_3_1_CSTM_TSR_NO_ENTRY_SET "カスタマイズ現在値(進入禁止標識)
";
CM_ SG_ 803 EYE323_3_2_CSTM_TSR_STOP_SET "カスタマイズ現在値(一時停止標識)
";
CM_ SG_ 803 EYE323_3_3_CSTM_TSR_GIVE_WAY_SET "カスタマイズ現在値(前方優先道路標識)
";
CM_ SG_ 803 EYE323_3_4_WILDERNESS "Wilderness識別情報
";
CM_ SG_ 803 EYE323_3_5_AES_OFF "AES  OFFｲﾝｼﾞｹｰﾀ信号
";
CM_ SG_ 803 EYE323_3_6_FCTB_IND "FCTBインジケータ
";
CM_ SG_ 803 EYE323_2_0_CSTM_LDW_ALK_B "ｱｲｻｲﾄｶｽﾀﾏｲｽﾞ現在値設定（LDW/ALK-B）
";
CM_ SG_ 803 EYE323_2_2_CSTM_P_CR "ｱｲｻｲﾄｶｽﾀﾏｲｽﾞ現在値設定（P-CR）
";
CM_ SG_ 803 EYE323_2_3_SLOWDOWN_FUNC_INFO2 "料金所前減速機能有無
";
CM_ SG_ 803 EYE323_2_4_CID_CODE_WARN "CID警報ｺｰﾄﾞ
";
CM_ SG_ 803 EYE323_1_0_MSG_COUNTER "ﾒｯｾｰｼﾞｶｳﾝﾀ
";
CM_ SG_ 803 EYE323_1_4_DISP_FOLLOW_FORWARD "先行車追従表示フラグ
";
CM_ SG_ 803 EYE323_1_5_KEEP_LINE_SENTER_ACT "白線中央維持制御中フラグ
";
CM_ SG_ 803 EYE323_1_6_DDAW_FAIL_OFF "DDAW故障/OFF灯
";
CM_ SG_ 803 EYE323_0_0_CHECK_SUM "ﾁｪｯｸｻﾑ
";
CM_ SG_ 802 EYE322_7_0_CSTM_ACC_CONT_SET "ｱｲｻｲﾄｶｽﾀﾏｲｽﾞ現在値設定（ACC加速特性）
";
CM_ SG_ 802 EYE322_7_2_ELK_OFF_IND "ELK OFF灯表示
";
CM_ SG_ 802 EYE322_7_3_LIGHT_EAM_YELLOW "EAM(黄)点灯指示
";
CM_ SG_ 802 EYE322_7_5_BROKEN_LINE_L "車線表示切替_左
";
CM_ SG_ 802 EYE322_7_6_TJA_ACTIVE "TJA作動中フラグ
";
CM_ SG_ 802 EYE322_7_7_BROKEN_LINE_R "車線表示切替_右
";
CM_ SG_ 802 EYE322_6_0_CSTM_MIS_AT_START "ｱｲｻｲﾄｶｽﾀﾏｲｽﾞ現在設定値(AT誤後進抑制制御)
";
CM_ SG_ 802 EYE322_6_2_CSTM_ALK_TJA_SET "ｱｲｻｲﾄｶｽﾀﾏｲｽﾞ現在値設定(車線中央維持・TJA)
";
CM_ SG_ 802 EYE322_6_3_CSTM_LANE_SET "ｱｲｻｲﾄｶｽﾀﾏｲｽﾞ現在設定値（通行車線）
";
CM_ SG_ 802 EYE322_6_4_LDP_OFF_IND "LDP OFF灯表示
";
CM_ SG_ 802 EYE322_6_5_INDICATOR_MODE_L "左側ミラーインジケータ制御指示フラグ
";
CM_ SG_ 802 EYE322_6_7_CSTM_ELK_SET "ｱｲｻｲﾄｶｽﾀﾏｲｽﾞ現在設定値（ELK)
";
CM_ SG_ 802 EYE322_5_0_CSTM_MIS_AT_BACK "ｱｲｻｲﾄ機能有無情報(AT誤後進抑制制御)
";
CM_ SG_ 802 EYE322_5_1_CSTM_ALK_TJA "ｱｲｻｲﾄ機能有無情報(車線中央維持・TJA)
";
CM_ SG_ 802 EYE322_5_2_CSTM_SAS "ｱｲｻｲﾄ機能有無情報(SAS)
";
CM_ SG_ 802 EYE322_5_3_CSTM_HBA "ｱｲｻｲﾄ機能有無情報(HBA)
";
CM_ SG_ 802 EYE322_5_4_CSTM_ACC_CONT "ｱｲｻｲﾄ機能有無情報(ACC加速特性)
";
CM_ SG_ 802 EYE322_5_5_CSTM_LANE "ｱｲｻｲﾄ機能有無情報（通行車線）
";
CM_ SG_ 802 EYE322_5_6_LDW_SOUND_OFF_IND "LDW音 OFF灯表示
";
CM_ SG_ 802 EYE322_5_7_CSTM_ELK_SET "ｱｲｻｲﾄ機能有無情報（ELK）
";
CM_ SG_ 802 EYE322_4_0_CODE_WARN "警報ｺｰﾄﾞ（音有り）
";
CM_ SG_ 802 EYE322_4_5_CSTM_GSR "GSR対応有無フラグ
";
CM_ SG_ 802 EYE322_3_0_LANE_L "車線左表示
";
CM_ SG_ 802 EYE322_3_2_LANE_R "車線右表示
";
CM_ SG_ 802 EYE322_3_4_LANE_L_COLOR "車線左色
";
CM_ SG_ 802 EYE322_3_6_LANE_R_COLOR "車線右色
";
CM_ SG_ 802 EYE322_2_0_FCW_OFF_IND "FCW OFF灯表示
";
CM_ SG_ 802 EYE322_2_1_MOV_EYESIGHT_SCREEN "ｱｲｻｲﾄ画面移行ﾌﾗｸﾞ(ID322)
";
CM_ SG_ 802 EYE322_2_2_ALK_ICON "ALK表示
";
CM_ SG_ 802 EYE322_2_4_INDICATOR_CTRL_REQ "ミラーインジケータ制御フラグ
";
CM_ SG_ 802 EYE322_2_5_INDICATOR_MODE_R "右側ミラーインジケータ制御指示フラグ
";
CM_ SG_ 802 EYE322_2_7_LIMITER_BACK_SPEED "後退速度ﾘﾐｯﾀｰ設定値表示
";
CM_ SG_ 802 EYE322_1_0_MSG_COUNTER "ﾒｯｾｰｼﾞｶｳﾝﾀ
";
CM_ SG_ 802 EYE322_1_4_CODE_NO_BUZZER "警報ｺｰﾄﾞ（表示のみ）
";
CM_ SG_ 802 EYE322_1_7_DISTWARN_DMS "車間距離警報早鳴りﾌﾗｸﾞ
";
CM_ SG_ 802 EYE322_0_0_CHECK_SUM "ﾁｪｯｸｻﾑ
";
CM_ SG_ 801 EYE321_7_0_INFO_DIST_FORWARD "先行車距離
";
CM_ SG_ 801 EYE321_7_4_INFO_KEEP_STOP "停止保持中(HOLD)表示
";
CM_ SG_ 801 EYE321_7_5_INFO_READY "READY表示
";
CM_ SG_ 801 EYE321_7_6_INFO_SET_CC "ｸﾙｺﾝSET表示
";
CM_ SG_ 801 EYE321_7_7_INFO_OFF "OFF表示
";
CM_ SG_ 801 EYE321_6_0_FAIL_EYESIGHT "ｱｲｻｲﾄﾌｪｰﾙﾌﾗｸﾞ
";
CM_ SG_ 801 EYE321_6_1_MOV_EYESIGHT_SCREEN "ｱｲｻｲﾄ画面移行ﾌﾗｸﾞ(ID321)
";
CM_ SG_ 801 EYE321_6_2_IND_VEHICLE "自車表示
";
CM_ SG_ 801 EYE321_6_3_BRAKELAMP_VEHICLE "自車ﾌﾞﾚｰｷﾗﾝﾌﾟ点灯状態
";
CM_ SG_ 801 EYE321_6_4_IND_FORWARD_VECL "先行車表示
";
CM_ SG_ 801 EYE321_6_5_BRAKELAMP_FORWARD "先行車ﾌﾞﾚｰｷﾗﾝﾌﾟ点灯状態
";
CM_ SG_ 801 EYE321_6_6_CC_OR_LIM_SON "ｸﾙｺﾝ・ﾘﾐｯﾀｾｯﾄ状態
";
CM_ SG_ 801 EYE321_6_7_TEMP_OFF_STATE "一括一時OFF状態
";
CM_ SG_ 801 EYE321_5_0_INFO_SET_SPD "ｾｯﾄ車速表示
";
CM_ SG_ 801 EYE321_4_0_ACC_MODE "ACC/CC/SASﾓｰﾄﾞﾌﾗｸﾞ
";
CM_ SG_ 801 EYE321_4_2_SRVD_LASTMEM_ST_REQ "SRVDラストメモリ起動要求フラグ
";
CM_ SG_ 801 EYE321_4_3_INFO_MAIN_CC "ｸﾙｺﾝﾒｲﾝ表示
";
CM_ SG_ 801 EYE321_4_5_TRAFFIC_LIGHT "信号表示
";
CM_ SG_ 801 EYE321_3_0_CODE_HALT "ＨＡＬＴｺｰﾄﾞ
";
CM_ SG_ 801 EYE321_3_3_ELK_EQUIP "ELK機能有無
";
CM_ SG_ 801 EYE321_3_4_SET_DIST "車間距離設定表示
";
CM_ SG_ 801 EYE321_3_7_TJA "TJA機能有無
";
CM_ SG_ 801 EYE321_2_0_ACC_CANCEL_OR_CSTM "ｸﾙｺﾝｷｬﾝｾﾙ理由表示
";
CM_ SG_ 801 EYE321_2_4_ALK_CANCEL_OR_CSTM "ALKｷｬﾝｾﾙ理由表示
";
CM_ SG_ 801 EYE321_2_7_ALK_CANCEL_DISP_TYPE "ALKｷｬﾝｾﾙ表示種別
";
CM_ SG_ 801 EYE321_1_0_MSG_COUNTER "ﾒｯｾｰｼﾞｶｳﾝﾀ
";
CM_ SG_ 801 EYE321_1_4_PRECRASH_BRAKE_OFF "ﾌﾟﾘｸﾗｯｼｭﾌﾞﾚｰｷOFFｲﾝｼﾞｹｰﾀON flg
";
CM_ SG_ 801 EYE321_1_5_LANE_DEPARTURE_OFF "車線逸脱警報OFFｲﾝｼﾞｹｰﾀON flg
";
CM_ SG_ 801 EYE321_1_6_MET_AD_DRV_ASS "MET用高度運転支援有無ﾌﾗｸﾞ
";
CM_ SG_ 801 EYE321_1_7_ALC_EQUIP "ALC機能有無フラグ
";
CM_ SG_ 801 EYE321_0_0_CHECK_SUM "ﾁｪｯｸｻﾑ
";
CM_ SG_ 556 EYE22C_7_0_COMMANDSW_CC "ｸﾙｺﾝｽｲｯﾁ情報
";
CM_ SG_ 556 EYE22C_7_3_MODE_CC "ｸﾙｺﾝﾓｰﾄﾞﾌﾗｸﾞ
";
CM_ SG_ 556 EYE22C_7_4_CC_SETLAMP_INFO "ｸﾙｺﾝｾｯﾄﾗﾝﾌﾟ情報
";
CM_ SG_ 556 EYE22C_7_5_MSA_CNT_STS_EGI_HEV "MSA制御状態(EGI)
";
CM_ SG_ 556 EYE22C_7_6_SET_MSA "MSAｾｯﾄ状態(xCCSONLIM)
";
CM_ SG_ 556 EYE22C_7_7_SET_CC "ｸﾙｺﾝｾｯﾄ状態(xCCSON)
";
CM_ SG_ 556 EYE22C_5_0_TRQDWN_FORCE_LIMIT "FMWｴﾝｼﾞﾝﾄﾙｸﾀﾞｳﾝ指示 or 駆動力制限値
";
CM_ SG_ 556 EYE22C_4_0_BLIPPING_INHI "ﾌﾞﾘｯﾋﾟﾝｸﾞ禁止ﾌﾗｸﾞ
";
CM_ SG_ 556 EYE22C_4_4_ACTIVE_BRAKE_ACC "ﾌﾞﾚｰｷ制御実施ﾌﾗｸﾞ(ACCﾌﾞﾚｰｷ中のみ)
";
CM_ SG_ 556 EYE22C_4_5_REQ_FMW "FMW指示ﾌﾗｸﾞ
";
CM_ SG_ 556 EYE22C_4_6_FLG_BEFORE_RESERVE "停止保持予約前ﾌﾗｸﾞ
";
CM_ SG_ 556 EYE22C_4_7_REQ_TARGET_TORQUE "目標ﾄﾙｸ指示情報
";
CM_ SG_ 556 EYE22C_2_0_TGT_SPD_TRQ_FORCE "目標ﾄﾙｸ or 目標駆動力
";
CM_ SG_ 556 EYE22C_1_0_MSG_COUNTER "ﾒｯｾｰｼﾞｶｳﾝﾀ
";
CM_ SG_ 556 EYE22C_1_4_FLG_ADAPTIVE_CC "追従ｸﾙｺﾝﾌﾗｸﾞ
";
CM_ SG_ 556 EYE22C_1_5_MAIN_CC "ｸﾙｺﾝﾒｲﾝSW状態
";
CM_ SG_ 556 EYE22C_1_6_FLG_EYESIGHT_VERSION "ｱｲｻｲﾄﾊﾞｰｼﾞｮﾝﾌﾗｸﾞ
";
CM_ SG_ 556 EYE22C_1_7_FAIL_EYESIGHT "ｱｲｻｲﾄﾌｪｰﾙﾌﾗｸﾞ
";
CM_ SG_ 556 EYE22C_0_0_CHECK_SUM "ﾁｪｯｸｻﾑ
";
CM_ SG_ 545 EYE221_7_0_COMMANDSW_CC "ｸﾙｺﾝｽｲｯﾁ情報
";
CM_ SG_ 545 EYE221_7_3_MODE_CC "ｸﾙｺﾝﾓｰﾄﾞﾌﾗｸﾞ
";
CM_ SG_ 545 EYE221_7_4_MSA_CNT_STS_EGI_HEV "MSA制御状態(EGI・HEV)
";
CM_ SG_ 545 EYE221_7_6_EQUIP_MSA "MSA有無フラグ
";
CM_ SG_ 545 EYE221_7_7_INHIBIT_FUEL_CUT "燃料ｶｯﾄ禁止要求ﾌﾗｸﾞ
";
CM_ SG_ 545 EYE221_5_0_TRQDWN_FORCE_LIMIT "FMWｴﾝｼﾞﾝﾄﾙｸﾀﾞｳﾝ指示 or 駆動力制限値
";
CM_ SG_ 545 EYE221_4_0_STATE_TRACKING "追尾ﾌﾗｸﾞ
";
CM_ SG_ 545 EYE221_4_1_STATE_LSF "LSFﾌﾗｸﾞ
";
CM_ SG_ 545 EYE221_4_2_FORCED_CANCEL_ACC "ACC強制ｷｬﾝｾﾙﾌﾗｸﾞ
";
CM_ SG_ 545 EYE221_4_3_BRAKE_TYPE "ﾌﾞﾚｰｷｼｽﾃﾑﾌﾗｸﾞ
";
CM_ SG_ 545 EYE221_4_4_ACTIVE_BRAKE_ACC "ﾌﾞﾚｰｷ制御実施ﾌﾗｸﾞ(ACCﾌﾞﾚｰｷ中のみ)
";
CM_ SG_ 545 EYE221_4_5_REQ_FMW "FMW指示ﾌﾗｸﾞ
";
CM_ SG_ 545 EYE221_4_6_FLG_BEFORE_RESERVE "停止保持予約前ﾌﾗｸﾞ
";
CM_ SG_ 545 EYE221_4_7_REQ_TARGET_TORQUE "目標ﾄﾙｸ指示情報
";
CM_ SG_ 545 EYE221_2_0_TGT_SPD_TRQ_FORCE "目標ﾄﾙｸ or 目標駆動力
";
CM_ SG_ 545 EYE221_1_0_MSG_COUNTER "ﾒｯｾｰｼﾞｶｳﾝﾀ
";
CM_ SG_ 545 EYE221_1_4_FLG_ADAPTIVE_CC "追従ｸﾙｺﾝﾌﾗｸﾞ
";
CM_ SG_ 545 EYE221_1_5_CANCEL_SW_INFO "ｸﾙｺﾝｷｬﾝｾﾙSW有無情報
";
CM_ SG_ 545 EYE221_1_6_FLG_EYESIGHT_VERSION "ｱｲｻｲﾄﾊﾞｰｼﾞｮﾝﾌﾗｸﾞ
";
CM_ SG_ 545 EYE221_1_7_FAIL_EYESIGHT "ｱｲｻｲﾄﾌｪｰﾙﾌﾗｸﾞ
";
CM_ SG_ 545 EYE221_0_0_CHECK_SUM "ﾁｪｯｸｻﾑ
";
CM_ SG_ 287 ADAS11F_7_0_SND_MAC "送信用MAC
";
CM_ SG_ 287 ADAS11F_4_4_RESET_FLG "ﾘｾｯﾄﾌﾗｸﾞ
";
CM_ SG_ 287 ADAS11F_4_6_SNDMSG_CNT "送信用ﾒｯｾｰｼﾞｶｳﾝﾀ
";
CM_ SG_ 287 ADAS11F_3_0_MSG_COUNTER "ﾒｯｾｰｼﾞｶｳﾝﾀ
";
CM_ SG_ 287 ADAS11F_3_4_HANDSOFF_FLG "ﾊﾝｽﾞｵﾌﾌﾗｸﾞ
";
CM_ SG_ 287 ADAS11F_3_5_TRQ_LIMIT_REQ_FLG "舵角制御ﾄﾙｸ制限要求ﾌﾗｸﾞ
";
CM_ SG_ 287 ADAS11F_2_0_STEER_ANGLE_OFFSET "ﾊﾝﾄﾞﾙ角 ｵﾌｾｯﾄ補償値
";
CM_ SG_ 292 ADAS124_7_3_TRQ_RATE_CHG "指示トルクレート切り替えフラグ
";
CM_ SG_ 292 ADAS124_7_4_STR_RATE_CHG "指示舵角レート切り替えフラグ
";
CM_ SG_ 292 ADAS124_7_6_OVR_STR_LVL "オーバーライド舵力可変フラグ
";
CM_ SG_ 292 ADAS124_5_0_HNDR_RECDEG "指示ハンドル角
";
CM_ SG_ 292 ADAS124_3_0_STR_OFFSET "ハンドル角 オフセット補償値
";
CM_ SG_ 292 ADAS124_1_0_MSG_COUNTER "ﾒｯｾｰｼﾞｶｳﾝﾀ
";
CM_ SG_ 292 ADAS124_1_4_ACTIVE_FLG "アクティブフラグ
";
CM_ SG_ 292 ADAS124_0_0_CHECK_SUM "ﾁｪｯｸｻﾑ
";
CM_ SG_ 279 SNR117_16_0_CSTM_SNR_DSPREEQ "カスタマイズ表示要求(クリソナON/OFF)
";
CM_ SG_ 279 SNR117_16_2_CSTM_RAB_DSPREQ "カスタマイズ表示要求(RAB ON/OFF)
";
CM_ SG_ 279 SNR117_16_4_CSTM_PED_DSPREQ "カスタマイズ表示要求(歩行者RAB ON/OFF)
";
CM_ SG_ 279 SNR117_16_6_CSTM_PEDTIM_DSPREQ "カスタマイズ表示要求(歩行者RABタイミング)
";
CM_ SG_ 279 SNR117_15_0_CSTM_SNR_CLEAR "SNRｶｽﾀﾏｲｽﾞ現在値設定(ｸﾘｱﾗﾝｽｿﾅｰ機能)
";
CM_ SG_ 279 SNR117_15_1_CSTM_RAB "SNRｶｽﾀﾏｲｽﾞ現在値設定(RAB機能)
";
CM_ SG_ 279 SNR117_15_2_CSTM_RAB_PED "SNRｶｽﾀﾏｲｽﾞ現在値設定(歩行者RAB機能)
";
CM_ SG_ 279 SNR117_15_3_CSTM_RAB_PED_TIMING "SNRｶｽﾀﾏｲｽﾞ現在値設定(歩行者RABタイミング)
";
CM_ SG_ 279 SNR117_14_0_RAB_WARNING "割り込み表示要求
";
CM_ SG_ 279 SNR117_14_3_SONAR_LEVEL "警報音指示
";
CM_ SG_ 279 SNR117_13_0_PED_WARN_CENTER "歩行者お知らせ中央表示
";
CM_ SG_ 279 SNR117_13_1_PED_WARN_LEFT "歩行者お知らせ左表示
";
CM_ SG_ 279 SNR117_13_2_PED_WARN_RIGHT "歩行者お知らせ右表示
";
CM_ SG_ 279 SNR117_13_3_RAB_TRIG_TYPE "RAB作動トリガ種類
";
CM_ SG_ 279 SNR117_9_0_SONAR_R_R_CORNER_4LV "リアソナー距離警報情報(右コーナー4段階)
";
CM_ SG_ 279 SNR117_8_0_SONAR_DISP_INT "クリソナ割り込み表示要求
";
CM_ SG_ 279 SNR117_8_1_SONAR_R_CENTER "ﾘｱｿﾅｰ距離警報情報：Rcenter（中央4段階）
";
CM_ SG_ 279 SNR117_8_4_SONAR_R_L_CORNER_4LV "リアソナー距離警報情報(左コーナー4段階)
";
CM_ SG_ 279 SNR117_7_0_SONAR_SYS_FAIL "ｿﾅｰｼｽﾃﾑ故障状態通知 (FAIL)
";
CM_ SG_ 279 SNR117_7_2_RAB_HALT "RAB一時停止状態通知 (HALT)
";
CM_ SG_ 279 SNR117_7_4_CAMERA_FAIL "ｶﾒﾗｼｽﾃﾑ故障状態通知(FAIL)
";
CM_ SG_ 279 SNR117_7_6_RAB_PED_HALT "歩行者RAB一時停止状態通知(HALT)
";
CM_ SG_ 279 SNR117_6_0_REQ_ACT_EPB "EPB作動要求
";
CM_ SG_ 279 SNR117_6_1_STOP_HOJI_BUZ_ACT "停止保持解除音フラグ
";
CM_ SG_ 279 SNR117_6_2_RAB_OFF "RAB OFF灯　点灯要求
";
CM_ SG_ 279 SNR117_6_3_SONAR_OFF "警報音機能OFF灯 点灯要求
";
CM_ SG_ 279 SNR117_6_4_RAB_PED_OFF "歩行者RAB OFF灯 点灯要求
";
CM_ SG_ 279 SNR117_6_5_SONAR_HALT "警報音一時停止状態通知(HALT)
";
CM_ SG_ 279 SNR117_5_0_YOATSU_ACT "ﾌﾞﾚｰｷ予圧ﾌﾗｸﾞ
";
CM_ SG_ 279 SNR117_5_1_TORQUE_LIM_ACT "加速抑制実施フラグ
";
CM_ SG_ 279 SNR117_5_2_TORQUE_LIM_VAL "加速抑制値
";
CM_ SG_ 279 SNR117_4_0_RAB_ACT "RAB実施フラグ
";
CM_ SG_ 279 SNR117_4_1_RAB_VAL "減速度制動指示
";
CM_ SG_ 279 SNR117_3_0_RAB "RAB機能有無
";
CM_ SG_ 279 SNR117_3_1_RAB_PED "歩行者RAB機能有無
";
CM_ SG_ 279 SNR117_2_0_E2E_COUNTER "E2Eｶｳﾝﾀ
";
CM_ SG_ 279 SNR117_0_0_E2E_CRC "CRC
";
CM_ SG_ 845 ADAS34D_16_0_CSTM_SNR_DSPREEQ "カスタマイズ表示要求(クリソナON/OFF)
";
CM_ SG_ 845 ADAS34D_16_2_CSTM_RAB_DSPREQ "カスタマイズ表示要求(RAB ON/OFF)
";
CM_ SG_ 845 ADAS34D_16_4_CSTM_PED_DSPREQ "カスタマイズ表示要求(歩行者RAB ON/OFF)
";
CM_ SG_ 845 ADAS34D_16_6_CSTM_PEDTIM_DSPREQ "カスタマイズ表示要求(歩行者RABタイミング)
";
CM_ SG_ 845 ADAS34D_15_0_CSTM_SNR_CLEAR "SNRｶｽﾀﾏｲｽﾞ現在値設定(ｸﾘｱﾗﾝｽｿﾅｰ機能)
";
CM_ SG_ 845 ADAS34D_15_1_CSTM_RAB "SNRｶｽﾀﾏｲｽﾞ現在値設定(RAB機能)
";
CM_ SG_ 845 ADAS34D_15_2_CSTM_RAB_PED "SNRｶｽﾀﾏｲｽﾞ現在値設定(歩行者RAB機能)
";
CM_ SG_ 845 ADAS34D_15_3_CSTM_RAB_PED_TIMING "SNRｶｽﾀﾏｲｽﾞ現在値設定(歩行者RABタイミング)
";
CM_ SG_ 845 ADAS34D_15_5_CSTM_TEMP_OFF "ｶｽﾀﾏｲｽﾞ現在設定値(一括一時OFF)
";
CM_ SG_ 845 ADAS34D_15_7_TEMP_OFF_STATE "一括一時OFF状態
";
CM_ SG_ 845 ADAS34D_14_0_RAB_WARNING "割り込み表示要求
";
CM_ SG_ 845 ADAS34D_14_3_SONAR_LEVEL "警報音指示
";
CM_ SG_ 845 ADAS34D_13_0_PED_WARN_CENTER "歩行者お知らせ中央表示
";
CM_ SG_ 845 ADAS34D_13_1_PED_WARN_LEFT "歩行者お知らせ左表示
";
CM_ SG_ 845 ADAS34D_13_2_PED_WARN_RIGHT "歩行者お知らせ右表示
";
CM_ SG_ 845 ADAS34D_13_3_RAB_TRIG_TYPE "RAB作動トリガ種類
";
CM_ SG_ 845 ADAS34D_9_0_SONAR_R_R_CORNER_4LV "リアソナー距離警報情報(右コーナー4段階)
";
CM_ SG_ 845 ADAS34D_8_0_SONAR_DISP_INT "クリソナ割り込み表示要求
";
CM_ SG_ 845 ADAS34D_8_1_SONAR_R_CENTER "ﾘｱｿﾅｰ距離警報情報：Rcenter（中央4段階）
";
CM_ SG_ 845 ADAS34D_8_4_SONAR_R_L_CORNER_4LV "リアソナー距離警報情報(左コーナー4段階)
";
CM_ SG_ 845 ADAS34D_7_0_SONAR_SYS_FAIL "ｿﾅｰｼｽﾃﾑ故障状態通知 (FAIL)
";
CM_ SG_ 845 ADAS34D_7_2_RAB_HALT "RAB一時停止状態通知 (HALT)
";
CM_ SG_ 845 ADAS34D_7_4_CAMERA_FAIL "ｶﾒﾗｼｽﾃﾑ故障状態通知(FAIL)
";
CM_ SG_ 845 ADAS34D_7_6_RAB_PED_HALT "歩行者RAB一時停止状態通知(HALT)
";
CM_ SG_ 845 ADAS34D_6_0_REQ_ACT_EPB "EPB作動要求
";
CM_ SG_ 845 ADAS34D_6_1_STOP_HOJI_BUZ_ACT "停止保持解除音フラグ
";
CM_ SG_ 845 ADAS34D_6_2_RAB_OFF "RAB OFF灯　点灯要求
";
CM_ SG_ 845 ADAS34D_6_3_SONAR_OFF "警報音機能OFF灯 点灯要求
";
CM_ SG_ 845 ADAS34D_6_4_RAB_PED_OFF "歩行者RAB OFF灯 点灯要求
";
CM_ SG_ 845 ADAS34D_6_5_SONAR_HALT "警報音一時停止状態通知(HALT)
";
CM_ SG_ 845 ADAS34D_5_0_YOATSU_ACT "ﾌﾞﾚｰｷ予圧ﾌﾗｸﾞ
";
CM_ SG_ 845 ADAS34D_5_1_TORQUE_LIM_ACT "加速抑制実施フラグ
";
CM_ SG_ 845 ADAS34D_5_2_TORQUE_LIM_VAL "加速抑制値
";
CM_ SG_ 845 ADAS34D_4_0_RAB_ACT "RAB実施フラグ
";
CM_ SG_ 845 ADAS34D_4_1_RAB_VAL "減速度制動指示
";
CM_ SG_ 845 ADAS34D_3_0_RAB "RAB機能有無
";
CM_ SG_ 845 ADAS34D_3_1_RAB_PED "歩行者RAB機能有無
";
CM_ SG_ 845 ADAS34D_2_0_E2E_COUNTER "E2Eｶｳﾝﾀ
";
CM_ SG_ 845 ADAS34D_0_0_E2E_CRC "CRC
";
CM_ SG_ 1109 CHR455_31_3_CHGCNRLOCSTT_DISPREQ "充電コネクタロック状態表示要求
";
CM_ SG_ 1109 CHR455_28_4_VEH_CHGPWRUPLMT "車両受け入れ可能上限電力
";
CM_ SG_ 1109 CHR455_27_4_V2H_MODE "V2H充放電モード
";
CM_ SG_ 1109 CHR455_26_4_DCPWRSUPSTT "DC給電状態
";
CM_ SG_ 1109 CHR455_26_3_CHGMNTDISP_REQ "充電画面表示要求
";
CM_ SG_ 1109 CHR455_26_2_MNTLIT_REQ "画面点灯要求
";
CM_ SG_ 1109 CHR455_25_0_CHGVLT_DISP "充電電圧(表示用)
";
CM_ SG_ 1109 CHR455_23_0_CHGCUR_DISP "充電電流(表示用)
";
CM_ SG_ 1109 CHR455_22_1_CHGSTPCOMP "充電停止完了通知
";
CM_ SG_ 1109 CHR455_20_1_ENERGY_CHARGED_DISP "充電電力量(kWh)
";
CM_ SG_ 1109 CHR455_19_2_DLTSOCCALC_FIN "デルタSOC(充電完了後)_統合CU
";
CM_ SG_ 1109 CHR455_18_3_DLTSOCCALC_STRT "デルタSOC(充電開始時)_統合CU
";
CM_ SG_ 1109 CHR455_18_2_STLMT_TYPE "決済方式_統合CU
";
CM_ SG_ 1109 CHR455_18_1_ACDC_INFO "AC/DC 情報_統合CU
";
CM_ SG_ 1109 CHR455_16_6_EVSEOUTPWR "充電スタンド出力電力
";
CM_ SG_ 1109 CHR455_13_3_CHG_FINTIM "充電完了時間_統合CU
";
CM_ SG_ 1109 CHR455_12_0_CHGTIM "充電時間_統合CU
";
CM_ SG_ 1109 CHR455_10_7_DCPWRSUP_PWR_DISP "DC車両供給電力（表示用）
";
CM_ SG_ 1109 CHR455_8_7_CHGPWR_DISP "充電電力（表示用）
";
CM_ SG_ 1109 CHR455_7_1_DCPWRSUP_ADMTIM "DC給電可能時間
";
CM_ SG_ 1109 CHR455_6_1_CHGSTT "充電状態
";
CM_ SG_ 1109 CHR455_5_2_FED_LOLMT "給電量下限値
";
CM_ SG_ 1109 CHR455_4_6_DCCHG_PWRUPLMT "DC充電電力上限設定値
";
CM_ SG_ 1109 CHR455_4_2_ACCHG_CURUPLMT "AC充電電流上限設定値
";
CM_ SG_ 1109 CHR455_3_3_CHG_HILMT "充電量上限値
";
CM_ SG_ 1109 CHR455_3_1_CHG_CNRLOCSTT "充電コネクタロック状態（表示用）
";
CM_ SG_ 1109 CHR455_3_0_CHG_CNRCNTSTT "充電コネクタ接続状態(表示用)
";
CM_ SG_ 1109 CHR455_2_0_E2E_COUNTER "E2Eカウンタ
";
CM_ SG_ 1109 CHR455_0_0_E2E_CRC "CRC
";
CM_ SG_ 116 BEV074_7_0_LVPWRDWN "12V電力抑制信号
";
CM_ SG_ 116 BEV074_7_6_CHRCONSTA "充電コネクタ接続状態
";
CM_ SG_ 116 BEV074_7_7_VEHICLE_IGN "車両イグニッション情報
";
CM_ SG_ 116 BEV074_6_0_EV_CAU "EVコーション点灯要求
";
CM_ SG_ 116 BEV074_6_2_BEV_OBD_CAU "BEV_OBD警告灯点灯要求
";
CM_ SG_ 116 BEV074_6_5_SIDRIVE_DISP "SIドライブモード表示情報
";
CM_ SG_ 116 BEV074_5_0_ACCHG_STATE "AC充電状態
";
CM_ SG_ 116 BEV074_5_1_DCCHG_STATE "DC充電状態
";
CM_ SG_ 116 BEV074_5_2_RANGE_DG "シフト故障状態
";
CM_ SG_ 116 BEV074_5_3_ACCP_DG "アクセル故障状態
";
CM_ SG_ 116 BEV074_5_4_REZ_SPD_BK "レゾルバ車速バックアップ状態
";
CM_ SG_ 116 BEV074_5_6_OBDRDY "OBD Ready状態
";
CM_ SG_ 116 BEV074_5_7_FHVB "高電圧バッテリ異常
";
CM_ SG_ 116 BEV074_3_0_RANGE_POS "現在レンジ位置情報
";
CM_ SG_ 116 BEV074_3_3_DRVRDY "運転可能表示状態
";
CM_ SG_ 116 BEV074_3_5_HVSYSTS "高電圧システムステータス
";
CM_ SG_ 116 BEV074_3_7_REZ_SPD_GL "レゾルバ車速_GL
";
CM_ SG_ 116 BEV074_2_0_ACCP_USR "アクセル開度(ユーザー)
";
CM_ SG_ 116 BEV074_1_0_MSG_COUNTER "ﾒｯｾｰｼﾞｶｳﾝﾀ
";
CM_ SG_ 116 BEV074_1_4_RANGE_DG2 "シフト故障状態2
";
CM_ SG_ 116 BEV074_1_5_REZ_SPD_BK "レゾルバ車速バックアップ状態
";
CM_ SG_ 116 BEV074_0_0_CHECK_SUM "ﾁｪｯｸｻﾑ
";
CM_ SG_ 2564481223 AIL18DAE0C7_DIAG_DATA "ﾃﾞｰﾀ
";
CM_ SG_ 2564474848 DNT18DAC7E0_DIAG_DATA "ﾃﾞｰﾀ
";
CM_ SG_ 2564550625 CECU18DBEFE1_DIAG_DATA "ﾃﾞｰﾀ
";
CM_ SG_ 996 CECU3E4_7_0_SSM_COMM_INFO "SSM通信情報
";
CM_ SG_ 996 CECU3E4_6_0_CHARGE_LEVEL_ENG_RUN "エンジンRUN中充電レベル
";
CM_ SG_ 996 CECU3E4_6_4_CHARGE_LEVEL_IGN_ON "IG-ONエンスト中充電レベル
";
CM_ SG_ 996 CECU3E4_5_0_GENERATOR_OVER_FLG "発電機過大ﾌﾗｸﾞ
";
CM_ SG_ 996 CECU3E4_5_3_DIAG_COM_REQ "ﾃﾚﾏ診断通信要求
";
CM_ SG_ 996 CECU3E4_5_4_HEADS_UP_FLG "注意喚起ﾌﾗｸﾞ
";
CM_ SG_ 996 CECU3E4_3_0_WASH_CAR_MODE_STS "洗車モード状態
";
CM_ SG_ 996 CECU3E4_2_0_POW_ON_FIX_MODE_STS "電源ON固定モード状態
";
CM_ SG_ 996 CECU3E4_2_3_PET_MODE_STS "ペットモード状態
";
CM_ SG_ 996 CECU3E4_2_6_SHUT_DOWN_MODE_STS "シャットダウンモード遷移可否状態
";
CM_ SG_ 996 CECU3E4_2_7_OCCUPATION_CSTM "乗員検知設定値
";
CM_ SG_ 996 CECU3E4_1_0_MSG_COUNTER "ﾒｯｾｰｼﾞｶｳﾝﾀ
";
CM_ SG_ 996 CECU3E4_0_0_CHECK_SUM "ﾁｪｯｸｻﾑ
";
CM_ SG_ 1280 CGW500_1_4_ActiveWakeUpBit "Active Wakeup ﾌﾗｸﾞ
";
CM_ SG_ 1280 CGW500_0_0_SourceNodeID "送信元ID
";
CM_ SG_ 1749 CECU6D5_6_0_CSTM_FMHD "ウェルカムランプ(降車)
";
CM_ SG_ 1749 CECU6D5_5_0_CSTM_WRH "ワイパ連動オートライト機能ON/OFF設定
";
CM_ SG_ 1749 CECU6D5_5_1_CSTM_LMHD "ウェルカムランプ(乗車)
";
CM_ SG_ 1749 CECU6D5_5_3 "北米ウェルカムランプ(リービング)（カスタマイズ）
";
CM_ SG_ 1749 CECU6D5_5_5_CSTM_HBA "HBA 有無設定
";
CM_ SG_ 1749 CECU6D5_5_7_ADB_ACTIVE "ADB有無設定
";
CM_ SG_ 1749 CECU6D5_4_0_JUDGE_ILL "照度判定
";
CM_ SG_ 1749 CECU6D5_4_1_HEADLAMP_AUTO_SW "ライティングAUTO SW 出力信号
";
CM_ SG_ 1749 CECU6D5_4_2_IND_ACTIVE_HBA "HBA 作動灯
";
CM_ SG_ 1749 CECU6D5_4_4_FGT_LGTOFF_WARNING "ライト消し忘れ警報
";
CM_ SG_ 1749 CECU6D5_3_0_CRN_R_REQ "コーナリングランプR 出力要求
";
CM_ SG_ 1749 CECU6D5_3_2_CRN_L_REQ "コーナリングランプL 出力要求
";
CM_ SG_ 1749 CECU6D5_3_4_FMH "フォローミーホーム出力情報
";
CM_ SG_ 1749 CECU6D5_3_5_LMH "リードミーホーム出力情報
";
CM_ SG_ 1749 CECU6D5_2_0_LGT_1 "ライティング1 リレー出力要求
";
CM_ SG_ 1749 CECU6D5_2_1_LGT_LO "ライティングLo リレー出力要求
";
CM_ SG_ 1749 CECU6D5_2_2_LGT_HI "ライティングHi リレー出力要求
";
CM_ SG_ 1749 CECU6D5_2_4_FFOG_RELAY_REQ "Fフォグランプリレー出力要求
";
CM_ SG_ 1749 CECU6D5_2_5_RFOG_RELAY_REQ "Rフォグランプリレー出力要求
";
CM_ SG_ 1749 CECU6D5_2_6_LGT_DRL "DRL リレー出力要求
";
CM_ SG_ 1749 CECU6D5_1_0_MSG_COUNTER "ﾒｯｾｰｼﾞｶｳﾝﾀ
";
CM_ SG_ 1749 CECU6D5_0_0_CHECK_SUM "ﾁｪｯｸｻﾑ
";
CM_ SG_ 1753 CECU6D9_2_0_RCC_DOOR_LOCK_REQ "RCC ドアロック要求
";
CM_ SG_ 1753 CECU6D9_2_1_RCC_KEY_SEARCH_REQ "RCC アクセスキー確認要求
";
CM_ SG_ 1753 CECU6D9_2_2_RCC_BWAM_SETTING "バッテリ温調設定
";
CM_ SG_ 1753 CECU6D9_1_0_MSG_COUNTER "ﾒｯｾｰｼﾞｶｳﾝﾀ
";
CM_ SG_ 1753 CECU6D9_1_4_RCC_FLG "RCC実行中フラグ
";
CM_ SG_ 1753 CECU6D9_0_0_CHECK_SUM "ﾁｪｯｸｻﾑ
";
CM_ SG_ 723 CECU2D3_2_0_IGA_ON_REQUEST "IGaON要求
";
CM_ SG_ 723 CECU2D3_2_1_IGA_OFF_REQUEST "IGaOFF要求
";
CM_ SG_ 723 CECU2D3_2_2_IGB_ON_REQUEST "IGbON要求
";
CM_ SG_ 723 CECU2D3_2_3_IGB_OFF_REQUEST "IGbOFF要求
";
CM_ SG_ 723 CECU2D3_2_4_READY_ON_REQUEST "ReadyON要求
";
CM_ SG_ 723 CECU2D3_2_5_IGA_STATE "IGa状態
";
CM_ SG_ 723 CECU2D3_2_6_IGB_STATE "IGb状態
";
CM_ SG_ 723 CECU2D3_2_7_FACT_MODE "電源遷移制限モード
";
CM_ SG_ 723 CECU2D3_1_0_MSG_COUNTER "ﾒｯｾｰｼﾞｶｳﾝﾀ
";
CM_ SG_ 723 CECU2D3_0_0_CHECK_SUM "ﾁｪｯｸｻﾑ
";
CM_ SG_ 1739 DCM6CB_7_0 "Reserve
";
CM_ SG_ 1739 DCM6CB_5_0_DKY_SLOT_ID "Degital Key SlotID
";
CM_ SG_ 1739 DCM6CB_4_0_DKY_COM_REQ "Degital Keyコマンド要求
";
CM_ SG_ 1739 DCM6CB_3_5_PNC_SW_REQ_SRV "SVISからのPnCサービスOnOff切替要求
";
CM_ SG_ 1739 DCM6CB_2_0_SHUTDOWN_REQ "リモートシャットダウン要求
";
CM_ SG_ 1739 DCM6CB_2_3_IGB_OFF_REQUEST "IGb OFF電源遷移要求
";
CM_ SG_ 1739 DCM6CB_2_4_IGB_ON_REQUEST "IGb ON電源遷移要求
";
CM_ SG_ 1739 DCM6CB_2_5_REARGATE_UNLOCK_REQ "ﾘﾓｰﾄﾘｱｹﾞｰﾄｱﾝﾛｯｸ要求
";
CM_ SG_ 1739 DCM6CB_2_6_DOOR_UNLOCK_REQ "ﾘﾓｰﾄﾄﾞｱｱﾝﾛｯｸ要求
";
CM_ SG_ 1739 DCM6CB_2_7_DOOR_LOCK_REQUEST "ﾘﾓｰﾄﾄﾞｱﾛｯｸ要求
";
CM_ SG_ 1739 DCM6CB_1_0_MSG_COUNTER "ﾒｯｾｰｼﾞｶｳﾝﾀ
";
CM_ SG_ 1739 DCM6CB_1_4_REQ_SVR_HAZARD_ON "次世代盗難車両追跡用ハザード点滅要求
";
CM_ SG_ 1739 DCM6CB_1_5_HORNHZRD_DEACT_REQ "ﾘﾓｰﾄﾎｰﾝ&ﾊｻﾞｰﾄﾞ停止要求
";
CM_ SG_ 1739 DCM6CB_1_6_HAZARD_ACT_REQ "ﾘﾓｰﾄﾊｻﾞｰﾄﾞ動作要求
";
CM_ SG_ 1739 DCM6CB_1_7_HORNHAZARD_ACT_REQ "ﾘﾓｰﾄﾎｰﾝ&ﾊｻﾞｰﾄﾞ動作要求
";
CM_ SG_ 1739 DCM6CB_0_0_CHECK_SUM "ﾁｪｯｸｻﾑ
";
CM_ SG_ 1705 MVS6A9_6_0_CSTM_HITCHLINE_DSPREQ "ヒッチボールガイド線カスタマイズ表示要求
";
CM_ SG_ 1705 MVS6A9_6_2_CSTM_HITCHLINE "ヒッチボールガイド線ON/OFF情報
";
CM_ SG_ 1705 MVS6A9_5_0_RR_WIDE_VIEW_SW_STATE "リアワイドビューSW表示状態
";
CM_ SG_ 1705 MVS6A9_5_2_RR_NRW_VIEW_SW_STATE "リアナロービューSW表示状態
";
CM_ SG_ 1705 MVS6A9_5_4_HITCH_VIEW_SW_STATE "ヒッチボールビューSW表示状態
";
CM_ SG_ 1705 MVS6A9_4_0_FT_NRW_VIEW_SW_STATE "フロントナロービューSW表示状態
";
CM_ SG_ 1705 MVS6A9_4_2_FT_WIDE_VIEW_SW_STATE "フロントワイドビューSW表示状態
";
CM_ SG_ 1705 MVS6A9_4_4_SIDE_VIEW_SW_STATE "サイドビューSW表示状態
";
CM_ SG_ 1705 MVS6A9_4_6_3D_VIEW_SW_STATE "３DビューSW表示状態
";
CM_ SG_ 1705 MVS6A9_3_0_CSTM_AUTO_DISPLAY_SET "自動表示カスタマイズ機能有無
";
CM_ SG_ 1705 MVS6A9_3_1_CSTM_AUTO_DISPLAY "自動表示カスタマイズ設定
";
CM_ SG_ 1705 MVS6A9_3_2_VIEW_MODE "カメラ画面表示モード
";
CM_ SG_ 1705 MVS6A9_3_5_STOP_SWITCH "カメラ表示停止スイッチ操作可否
";
CM_ SG_ 1705 MVS6A9_3_6_CSTM_HITCH_VIEW "ヒッチボールビュー有無
";
CM_ SG_ 1705 MVS6A9_2_0_CURRENT_VIEW "映像出力情報
";
CM_ SG_ 1705 MVS6A9_2_5_HOLD_TIME "カメラ表示待ち時間(4カメラ用)
";
CM_ SG_ 1705 MVS6A9_1_0_MSG_COUNTER "ﾒｯｾｰｼﾞｶｳﾝﾀ
";
CM_ SG_ 1705 MVS6A9_1_4_FAIL_MVS "MVSﾌｪｰﾙﾌﾗｸﾞ
";
CM_ SG_ 1705 MVS6A9_1_5_FAIL_MVS_CAUSE "MVSﾌｪｰﾙ通知(FCTI向け)
";
CM_ SG_ 1705 MVS6A9_0_0_CHECK_SUM "ﾁｪｯｸｻﾑ
";
CM_ SG_ 930 MET3A2_7_0_FUEL_AMOUNT "残燃料表示
";
CM_ SG_ 930 MET3A2_6_0_SEATBELT_RR_RH "ｼｰﾄﾍﾞﾙﾄﾊﾞｯｸﾙSW　後席右
";
CM_ SG_ 930 MET3A2_6_1_SEATBELT_RR_CTR "ｼｰﾄﾍﾞﾙﾄﾊﾞｯｸﾙSW　後席中央
";
CM_ SG_ 930 MET3A2_6_2_SEATBELT_RR_LH "ｼｰﾄﾍﾞﾙﾄﾊﾞｯｸﾙSW　後席左
";
CM_ SG_ 930 MET3A2_6_3_SEATBELT_THIRD_RH "ｼｰﾄﾍﾞﾙﾄﾊﾞｯｸﾙSW　3rd後席右
";
CM_ SG_ 930 MET3A2_6_4_SEATBELT_THIRD_CTR "ｼｰﾄﾍﾞﾙﾄﾊﾞｯｸﾙSW　3rd後席中央
";
CM_ SG_ 930 MET3A2_6_5_SEATBELT_THIRD_LH "ｼｰﾄﾍﾞﾙﾄﾊﾞｯｸﾙSW　3rd後席左
";
CM_ SG_ 930 MET3A2_5_0_FLG_RR_REMINDER "幼児置き去り警報実施フラグ
";
CM_ SG_ 930 MET3A2_2_0_ODO_DETAIL "オドﾒｰﾀ値
";
CM_ SG_ 930 MET3A2_1_0_MSG_COUNTER "ﾒｯｾｰｼﾞｶｳﾝﾀ
";
CM_ SG_ 930 MET3A2_1_4_FAIL_DISP "MET表示フェールフラグ
";
CM_ SG_ 930 MET3A2_0_0_CHECK_SUM "ﾁｪｯｸｻﾑ
";
CM_ SG_ 1677 MET68D_7_0_STATUS_WASHER_LAMP "ｳｫｯｼｬ残量警告灯状態
";
CM_ SG_ 1677 MET68D_7_1_OILPRESSURE_SW "ｵｲﾙﾌﾟﾚｯｼｬSW状態
";
CM_ SG_ 1677 MET68D_7_2_FLG_EAM "EAM車両装備情報
";
CM_ SG_ 1677 MET68D_7_3_CSTM_IND_RED "ｱｲｻｲﾄﾓﾆﾀｰ変更設定赤色ｲﾝｼﾞｹｰﾀ
";
CM_ SG_ 1677 MET68D_7_4_CSTM_IND_YELLOW "ｱｲｻｲﾄﾓﾆﾀｰ変更設定黄色ｲﾝｼﾞｹｰﾀ
";
CM_ SG_ 1677 MET68D_7_5_CSTM_IND_GREEN "ｱｲｻｲﾄﾓﾆﾀｰ変更設定緑色ｲﾝｼﾞｹｰﾀ
";
CM_ SG_ 1677 MET68D_7_6_REQ_CSTM_SRH "SRHｶｽﾀﾏｲｽﾞ変更要求
";
CM_ SG_ 1677 MET68D_7_7_CSTM_SRH "SRHｶｽﾀﾏｲｽﾞ変更設定
";
CM_ SG_ 1677 MET68D_6_5_REQ_CHG_CSTM_RAB "RABｶｽﾀﾏｲｽﾞ要求変更
";
CM_ SG_ 1677 MET68D_6_6_CSTM_RAB "ｿﾅｰｶｽﾀﾏｲｽﾞ変更設定(RABON/OFF)
";
CM_ SG_ 1677 MET68D_6_7_CSTM_SONNER "ｿﾅｰｶｽﾀﾏｲｽﾞ変更設定(ｿﾅｰON/OFF)
";
CM_ SG_ 1677 MET68D_5_0_TEMP_FOR_PPA "歩行者保護A/B用温度
";
CM_ SG_ 1677 MET68D_2_0_ODO "ｵﾄﾞﾒｰﾀ値
";
CM_ SG_ 1677 MET68D_1_0_MSG_COUNTER "ﾒｯｾｰｼﾞｶｳﾝﾀ
";
CM_ SG_ 1677 MET68D_1_4_RESET_CSTM_TPMS_RAEB "ｶｽﾀﾏｲｽﾞﾘｾｯﾄ要求(TPMS/RAEB)
";
CM_ SG_ 1677 MET68D_1_5_REQ_CHG_CSTM_TPMS "TPMSｶｽﾀﾏｲｽﾞ要求変更
";
CM_ SG_ 1677 MET68D_1_6_CSTM_TIRE_UNIT "ﾀｲﾔ空気圧表示単位設定
";
CM_ SG_ 1677 MET68D_0_0_CHECK_SUM "ﾁｪｯｸｻﾑ
";
CM_ SG_ 1676 MET68C_7_0_CSTM_OUTTEMP "外気温ｶｽﾀﾏｲｽﾞ設定値
";
CM_ SG_ 1676 MET68C_4_6_UNIT_DEGREE "外気温単位設定値
";
CM_ SG_ 1676 MET68C_3_0_MET_SW_STATE "ﾒｰﾀSW操作状態ﾌﾗｸﾞ
";
CM_ SG_ 1676 MET68C_3_3_PERMIT_MFD_CSTM "MFDｶｽﾀﾏｲｽﾞ許可ﾌﾗｸﾞ
";
CM_ SG_ 1676 MET68C_3_5_FLG_RR_AC_PANEL "リアﾋｰｺﾝﾊﾟﾈﾙ装備
";
CM_ SG_ 1676 MET68C_3_6_FLG_SEAT_VENT "シート空調装備情報
";
CM_ SG_ 1676 MET68C_3_7_FLG_SEAT_HEAT "ｼｰﾄﾋｰﾀ装備情報
";
CM_ SG_ 1676 MET68C_2_0_CRUISING_RADIUS "航続可能距離表示値
";
CM_ SG_ 1676 MET68C_1_0_MSG_COUNTER "ﾒｯｾｰｼﾞｶｳﾝﾀ
";
CM_ SG_ 1676 MET68C_1_4_CSTM_HU "HU有無ﾌﾗｸﾞ
";
CM_ SG_ 1676 MET68C_1_5_CSTM_BRAND_NAME "ブランドフラグ
";
CM_ SG_ 1676 MET68C_0_0_CHECK_SUM "ﾁｪｯｸｻﾑ
";
CM_ SG_ 922 MET39A_7_0_SET_LANGUAGE "各国言語設定
";
CM_ SG_ 922 MET39A_7_5_ACTIVE_MET_CSTM "車両ｶｽﾀﾏｲｽﾞ実施状態ﾌﾗｸﾞ（ﾒｰﾀ）
";
CM_ SG_ 922 MET39A_7_6_MFD_SPEC "MFD判別ﾌﾗｸﾞ
";
CM_ SG_ 922 MET39A_7_7_ICY_ROAD_SURFACE "路面凍結警報状態
";
CM_ SG_ 922 MET39A_6_4_STATUS_TRIP_A_B "TRIP表示状態(A or B)
";
CM_ SG_ 922 MET39A_5_2_AVE_FUEL_ECONOMY "平均燃費
";
CM_ SG_ 922 MET39A_4_0_INSTANTANEOUS_FUEL "瞬間燃費
";
CM_ SG_ 922 MET39A_3_1_STATUS_FUEL_LAMP "燃料残量警告灯状態
";
CM_ SG_ 922 MET39A_3_3_TRANSIT_TIME "運転経過時間
";
CM_ SG_ 922 MET39A_2_0_AVE_VEHICLE_SPEED "平均車速表示
";
CM_ SG_ 922 MET39A_1_0_MSG_COUNTER "ﾒｯｾｰｼﾞｶｳﾝﾀ
";
CM_ SG_ 922 MET39A_1_4_SET_UNIT_OF_FUEL "燃費単位設定
";
CM_ SG_ 922 MET39A_1_6_WELCOME_TRIG "ｳｪﾙｶﾑ演出開始ﾄﾘｶﾞ
";
CM_ SG_ 922 MET39A_1_7_METER_DISPLAY_TYPE "ﾒｰﾀ液晶ﾀｲﾌﾟ
";
CM_ SG_ 922 MET39A_0_0_CHECK_SUM "ﾁｪｯｸｻﾑ
";
CM_ SG_ 915 MET393_7_0_REQ_CHG_CSTM_EYE "ｱｲｻｲﾄｶｽﾀﾏｲｽﾞ要求変更
";
CM_ SG_ 915 MET393_7_1_REQ_RESET_CSTM_EYE "ｱｲｻｲﾄｶｽﾀﾏｲｽﾞﾘｾｯﾄ要求
";
CM_ SG_ 915 MET393_7_2_CSTM_ALK "ｱｲｻｲﾄｶｽﾀﾏｲｽﾞ変更設定(車線中央維持)
";
CM_ SG_ 915 MET393_7_3_CSTM_HBA "ｱｲｻｲﾄｶｽﾀﾏｲｽﾞ変更設定値(HBA)
";
CM_ SG_ 915 MET393_7_4_CSTM_MIS_AT_BACK "ｱｲｻｲﾄｶｽﾀﾏｲｽﾞ変更設定(AT誤後進抑制制御)
";
CM_ SG_ 915 MET393_7_6_CSTM_ACC_CONT "ｱｲｻｲﾄｶｽﾀﾏｲｽﾞ変更設定(ACC加速特性)
";
CM_ SG_ 915 MET393_6_0_R_DIFF_TEMP "R.DIFF油温ｾﾝｻ
";
CM_ SG_ 915 MET393_5_2_WARN_R_DIFF_TEMP "R.DIFF油温警告灯
";
CM_ SG_ 915 MET393_5_4_ADAPTIVECC_NOALIVE "追従ｸﾙｺﾝ未着判定ﾌﾗｸﾞ
";
CM_ SG_ 915 MET393_5_5_DUAL_RANGE_LO "ﾃﾞｭｱﾙﾚﾝｼﾞLo
";
CM_ SG_ 915 MET393_5_6_CSTM_SPD_LIMITER "ｱｲｻｲﾄｶｽﾀﾏｲｽﾞ変更設定(SAS)
";
CM_ SG_ 915 MET393_5_7_CSTM_LANE_CONT "ｱｲｻｲﾄｶｽﾀﾏｲｽﾞ変更設定(通行車線)
";
CM_ SG_ 915 MET393_4_0_FUEL_LEVEL_RESIST "燃料ﾚﾍﾞﾙｾﾝｻ抵抗値
";
CM_ SG_ 915 MET393_3_5_SI_DRIVE_SW "SI-DRIVE SW情報
";
CM_ SG_ 915 MET393_2_0_OUTTEMP_FOR_DIAG "診断用外気温
";
CM_ SG_ 915 MET393_1_0_MSG_COUNTER "ﾒｯｾｰｼﾞｶｳﾝﾀ
";
CM_ SG_ 915 MET393_1_4_CSTM_IND_BLUE "ｱｲｻｲﾄﾓﾆﾀｰ変更設定青色ｲﾝｼﾞｹｰﾀ
";
CM_ SG_ 915 MET393_1_5_CSTM_AES_CONT "ｱｲｻｲﾄｶｽﾀﾏｲｽﾞ変更設定(AES)
";
CM_ SG_ 915 MET393_1_6_FLG_PEDESTRIAN_AIRBAG "歩行者保護A/B有無ﾌﾗｸﾞ
";
CM_ SG_ 915 MET393_0_0_CHECK_SUM "ﾁｪｯｸｻﾑ
";
CM_ SG_ 912 MET390_7_0_VDC_ON_OFF "VDC SW情報
";
CM_ SG_ 912 MET390_7_2_RR_DOOR_RECORD_L "後席ﾄﾞｱ開履歴送信（左）
";
CM_ SG_ 912 MET390_7_3_RR_DOOR_RECORD_R "後席ﾄﾞｱ開履歴送信（右）
";
CM_ SG_ 912 MET390_7_4_REQ_CHG_CSTM_PSM "PSMｶｽﾀﾏｲｽﾞ要求変更
";
CM_ SG_ 912 MET390_7_5_REQ_RESET_CSTM_PSM "PSM　ｶｽﾀﾏｲｽﾞﾘｾｯﾄ要求
";
CM_ SG_ 912 MET390_7_6_CSTM_MIR_AFOLD_CONT "ﾄﾞｱﾐﾗｰｶｽﾀﾏｲｽﾞ変更設定(ｵｰﾄ電動格納ﾐﾗｰ)
";
CM_ SG_ 912 MET390_7_7_CSTM_MIR_RTILT_CONT "ﾄﾞｱﾐﾗｰｶｽﾀﾏｲｽﾞ変更設定(ﾘﾊﾞｰｽ連動ﾐﾗｰ)
";
CM_ SG_ 912 MET390_6_0_SEATBELT_DRVR "ｼｰﾄﾍﾞﾙﾄﾊﾞｯｸﾙSW　D席
";
CM_ SG_ 912 MET390_6_1_SEATBELT_PASS "ｼｰﾄﾍﾞﾙﾄﾊﾞｯｸﾙSW　P席
";
CM_ SG_ 912 MET390_6_2_TURN_SIG_LEFT "ﾀｰﾝ左出力信号
";
CM_ SG_ 912 MET390_6_3_TURN_SIG_RIGHT "ﾀｰﾝ右出力信号
";
CM_ SG_ 912 MET390_6_4_BRIGHT_SW "ﾌﾞﾗｲﾄ信号
";
CM_ SG_ 912 MET390_6_5_FAIL_UART_WA_BOX "WA-BOX UART通信異常
";
CM_ SG_ 912 MET390_6_6_ISS_OFF_SW "ISS OFFｽｲｯﾁ状態
";
CM_ SG_ 912 MET390_6_7_FLG_DMS "DMS車両装備情報
";
CM_ SG_ 912 MET390_5_0_ILL_BRIGHTNESS "ｲﾙﾐ輝度値
";
CM_ SG_ 912 MET390_4_0_OUTTEMP_FOR_IND "表示用外気温
";
CM_ SG_ 912 MET390_3_0_UNIT_SPEED_TRIP "速度計/距離計表示単位
";
CM_ SG_ 912 MET390_3_1_FLG_EYESIGHT "EyeSightﾌﾗｸﾞ
";
CM_ SG_ 912 MET390_3_2_FLG_ISS "ISSﾌﾗｸﾞ
";
CM_ SG_ 912 MET390_3_3_FLG_HEV "HEVﾌﾗｸﾞ
";
CM_ SG_ 912 MET390_3_4_FLG_IMB "IMﾌﾗｸﾞ
";
CM_ SG_ 912 MET390_3_5_TIRE_SIZE "ﾀｲﾔ径情報
";
CM_ SG_ 912 MET390_3_6_FLG_XMODE "Xモード車両装備情報
";
CM_ SG_ 912 MET390_2_0_VEHICLE_SERIES "車型情報
";
CM_ SG_ 912 MET390_2_3_DESTINATION "仕向地情報
";
CM_ SG_ 912 MET390_2_7_PASS_DOOR_RECORD "助手席ﾄﾞｱ開履歴送信
";
CM_ SG_ 912 MET390_1_0_MSG_COUNTER "ﾒｯｾｰｼﾞｶｳﾝﾀ
";
CM_ SG_ 912 MET390_1_4_WAKE_UP_FRAME "ｳｪｲｸｱｯﾌﾟﾌﾚｰﾑ識別ﾌﾗｸﾞ
";
CM_ SG_ 912 MET390_1_5_REQ_COMM_CONT "通信継続要求ﾌﾗｸﾞ
";
CM_ SG_ 912 MET390_1_6_DMS_ID_SET "DMS ID設定完了ﾌﾗｸﾞ
";
CM_ SG_ 912 MET390_1_7_FAIL_EEPROM "EEPROMﾌｪｰﾙ
";
CM_ SG_ 912 MET390_0_0_CHECK_SUM "ﾁｪｯｸｻﾑ
";
BA_DEF_  "DBCConverterVersion" STRING ;
BA_DEF_  "Manufacturer" STRING ;
BA_DEF_ BU_  "DiagNode" ENUM  "No","Yes";
BA_DEF_ BU_  "ILUsed" ENUM  "No","Yes";
BA_DEF_ BU_  "NodeLayerModules" STRING ;
BA_DEF_ SG_  "Fhi_SignalComment" STRING ;
BA_DEF_ SG_  "GenSigInactiveValue" INT 0 10000;
BA_DEF_ SG_  "GenSigStartValue" FLOAT 0 100000000000;
BA_DEF_ SG_  "GenSigSendType" ENUM  "Cyclic","OnWrite","OnWriteWithRepetition","OnChange","OnChangeWithRepetition","IfActive","IfActiveWithRepetition","NoSigSendType";
BA_DEF_ BO_  "MsgRoutingId" STRING ;
BA_DEF_ BO_  "DiagResponse" ENUM  "No","Yes";
BA_DEF_ BO_  "DiagRequest" ENUM  "No","Yes";
BA_DEF_ BO_  "DiagState" ENUM  "No","Yes";
BA_DEF_ BO_  "GenMsgILSupport" ENUM  "No","Yes";
BA_DEF_ BO_  "GenMsgNrOfRepetition" INT 0 999999;
BA_DEF_ BO_  "GenMsgDelayTime" INT 0 1000;
BA_DEF_ BO_  "GenMsgCycleTimeFast" INT 0 10000;
BA_DEF_ BO_  "GenMsgCycleTime" INT 0 10000;
BA_DEF_ BO_  "GenMsgSendType" ENUM  "Cyclic","NotUsed","NotUsed","NotUsed","NotUsed","Cyclic","NotUsed","IfActive","NoMsgSendType";
BA_DEF_DEF_  "DBCConverterVersion" "2.0";
BA_DEF_DEF_  "Manufacturer" "FHI";
BA_DEF_DEF_  "DiagNode" "No";
BA_DEF_DEF_  "ILUsed" "Yes";
BA_DEF_DEF_  "NodeLayerModules" "CANoeILNLSubaru.dll";
BA_DEF_DEF_  "Fhi_SignalComment" "";
BA_DEF_DEF_  "GenSigInactiveValue" 0;
BA_DEF_DEF_  "GenSigStartValue" 0;
BA_DEF_DEF_  "GenSigSendType" "NoSigSendType";
BA_DEF_DEF_  "MsgRoutingId" "";
BA_DEF_DEF_  "DiagResponse" "No";
BA_DEF_DEF_  "DiagRequest" "No";
BA_DEF_DEF_  "DiagState" "No";
BA_DEF_DEF_  "GenMsgILSupport" "Yes";
BA_DEF_DEF_  "GenMsgNrOfRepetition" 0;
BA_DEF_DEF_  "GenMsgDelayTime" 0;
BA_DEF_DEF_  "GenMsgCycleTimeFast" 0;
BA_DEF_DEF_  "GenMsgCycleTime" 0;
BA_DEF_DEF_  "GenMsgSendType" "Cyclic";
BA_ "DiagNode" BU_ AIL 1;
BA_ "DiagNode" BU_ C_ECU 1;
BA_ "DiagNode" BU_ C_ECU_GW 1;
BA_ "GenMsgCycleTime" BO_ 552 50;
BA_ "GenMsgDelayTime" BO_ 552 10;
BA_ "GenMsgNrOfRepetition" BO_ 552 1;
BA_ "MsgRoutingId" BO_ 552 "279 ";
BA_ "GenMsgILSupport" BO_ 552 0;
BA_ "GenMsgCycleTime" BO_ 967 100;
BA_ "GenMsgDelayTime" BO_ 967 50;
BA_ "GenMsgCycleTimeFast" BO_ 967 50;
BA_ "GenMsgNrOfRepetition" BO_ 967 2;
BA_ "MsgRoutingId" BO_ 967 "277 ";
BA_ "GenMsgILSupport" BO_ 967 0;
BA_ "GenMsgCycleTime" BO_ 966 100;
BA_ "GenMsgDelayTime" BO_ 966 50;
BA_ "GenMsgCycleTimeFast" BO_ 966 50;
BA_ "GenMsgNrOfRepetition" BO_ 966 2;
BA_ "MsgRoutingId" BO_ 966 "276 ";
BA_ "GenMsgILSupport" BO_ 966 0;
BA_ "GenMsgCycleTime" BO_ 965 100;
BA_ "GenMsgDelayTime" BO_ 965 50;
BA_ "GenMsgCycleTimeFast" BO_ 965 50;
BA_ "GenMsgNrOfRepetition" BO_ 965 2;
BA_ "MsgRoutingId" BO_ 965 "275 ";
BA_ "GenMsgILSupport" BO_ 965 0;
BA_ "GenMsgCycleTime" BO_ 964 100;
BA_ "GenMsgDelayTime" BO_ 964 50;
BA_ "GenMsgCycleTimeFast" BO_ 964 50;
BA_ "GenMsgNrOfRepetition" BO_ 964 2;
BA_ "MsgRoutingId" BO_ 964 "274 ";
BA_ "GenMsgILSupport" BO_ 964 0;
BA_ "GenMsgCycleTime" BO_ 806 100;
BA_ "GenMsgDelayTime" BO_ 806 50;
BA_ "GenMsgCycleTimeFast" BO_ 806 50;
BA_ "GenMsgNrOfRepetition" BO_ 806 2;
BA_ "MsgRoutingId" BO_ 806 "272 ";
BA_ "GenMsgILSupport" BO_ 806 0;
BA_ "GenMsgCycleTime" BO_ 805 100;
BA_ "GenMsgDelayTime" BO_ 805 20;
BA_ "GenMsgCycleTimeFast" BO_ 805 50;
BA_ "GenMsgNrOfRepetition" BO_ 805 2;
BA_ "MsgRoutingId" BO_ 805 "271 ";
BA_ "GenMsgILSupport" BO_ 805 0;
BA_ "GenMsgCycleTime" BO_ 803 100;
BA_ "GenMsgDelayTime" BO_ 803 50;
BA_ "GenMsgCycleTimeFast" BO_ 803 50;
BA_ "GenMsgNrOfRepetition" BO_ 803 2;
BA_ "MsgRoutingId" BO_ 803 "269 ";
BA_ "GenMsgILSupport" BO_ 803 0;
BA_ "GenMsgCycleTime" BO_ 802 100;
BA_ "GenMsgDelayTime" BO_ 802 50;
BA_ "GenMsgCycleTimeFast" BO_ 802 50;
BA_ "GenMsgNrOfRepetition" BO_ 802 2;
BA_ "MsgRoutingId" BO_ 802 "268 ";
BA_ "GenMsgILSupport" BO_ 802 0;
BA_ "GenMsgCycleTime" BO_ 801 100;
BA_ "GenMsgDelayTime" BO_ 801 50;
BA_ "GenMsgCycleTimeFast" BO_ 801 50;
BA_ "GenMsgNrOfRepetition" BO_ 801 2;
BA_ "MsgRoutingId" BO_ 801 "267 ";
BA_ "GenMsgILSupport" BO_ 801 0;
BA_ "GenMsgCycleTime" BO_ 556 50;
BA_ "MsgRoutingId" BO_ 556 "266 ";
BA_ "GenMsgILSupport" BO_ 556 0;
BA_ "GenMsgCycleTime" BO_ 545 50;
BA_ "MsgRoutingId" BO_ 545 "265 ";
BA_ "GenMsgILSupport" BO_ 545 0;
BA_ "GenMsgCycleTime" BO_ 287 20;
BA_ "MsgRoutingId" BO_ 287 "263 ";
BA_ "GenMsgILSupport" BO_ 287 0;
BA_ "GenMsgCycleTime" BO_ 292 20;
BA_ "MsgRoutingId" BO_ 292 "262 ";
BA_ "GenMsgILSupport" BO_ 292 0;
BA_ "GenMsgCycleTime" BO_ 279 20;
BA_ "MsgRoutingId" BO_ 279 "261 ";
BA_ "GenMsgILSupport" BO_ 279 0;
BA_ "GenMsgCycleTime" BO_ 845 100;
BA_ "GenMsgCycleTime" BO_ 1109 100;
BA_ "GenMsgCycleTime" BO_ 116 10;
BA_ "MsgRoutingId" BO_ 116 "209 ";
BA_ "GenMsgILSupport" BO_ 116 0;
BA_ "GenMsgSendType" BO_ 2564481223 8;
BA_ "GenMsgNrOfRepetition" BO_ 2564481223 1;
BA_ "DiagResponse" BO_ 2564481223 1;
BA_ "GenMsgILSupport" BO_ 2564481223 0;
BA_ "MsgRoutingId" BO_ 2564481223 "196 ";
BA_ "GenMsgSendType" BO_ 2564474848 8;
BA_ "GenMsgNrOfRepetition" BO_ 2564474848 1;
BA_ "DiagRequest" BO_ 2564474848 1;
BA_ "GenMsgILSupport" BO_ 2564474848 0;
BA_ "MsgRoutingId" BO_ 2564474848 "195 ";
BA_ "GenMsgSendType" BO_ 2564550625 8;
BA_ "GenMsgNrOfRepetition" BO_ 2564550625 1;
BA_ "DiagState" BO_ 2564550625 1;
BA_ "GenMsgILSupport" BO_ 2564550625 0;
BA_ "GenMsgCycleTime" BO_ 996 500;
BA_ "GenMsgDelayTime" BO_ 996 10;
BA_ "GenMsgCycleTimeFast" BO_ 996 20;
BA_ "GenMsgNrOfRepetition" BO_ 996 5;
BA_ "GenMsgCycleTime" BO_ 1280 1000;
BA_ "GenMsgCycleTime" BO_ 1749 1000;
BA_ "GenMsgDelayTime" BO_ 1749 10;
BA_ "GenMsgCycleTimeFast" BO_ 1749 20;
BA_ "GenMsgNrOfRepetition" BO_ 1749 10;
BA_ "GenMsgCycleTime" BO_ 1753 1200;
BA_ "GenMsgDelayTime" BO_ 1753 10;
BA_ "GenMsgNrOfRepetition" BO_ 1753 1;
BA_ "GenMsgCycleTime" BO_ 723 50;
BA_ "GenMsgDelayTime" BO_ 723 10;
BA_ "GenMsgCycleTimeFast" BO_ 723 10;
BA_ "GenMsgNrOfRepetition" BO_ 723 3;
BA_ "GenMsgDelayTime" BO_ 1739 10;
BA_ "GenMsgSendType" BO_ 1739 8;
BA_ "GenMsgCycleTimeFast" BO_ 1739 20;
BA_ "GenMsgNrOfRepetition" BO_ 1739 1;
BA_ "MsgRoutingId" BO_ 1739 "114 ";
BA_ "GenMsgILSupport" BO_ 1739 0;
BA_ "GenMsgCycleTime" BO_ 1705 1000;
BA_ "GenMsgDelayTime" BO_ 1705 10;
BA_ "GenMsgCycleTimeFast" BO_ 1705 200;
BA_ "GenMsgNrOfRepetition" BO_ 1705 5;
BA_ "MsgRoutingId" BO_ 1705 "111 ";
BA_ "GenMsgILSupport" BO_ 1705 0;
BA_ "GenMsgCycleTime" BO_ 930 100;
BA_ "GenMsgDelayTime" BO_ 930 10;
BA_ "GenMsgCycleTimeFast" BO_ 930 50;
BA_ "GenMsgNrOfRepetition" BO_ 930 4;
BA_ "MsgRoutingId" BO_ 930 "110 ";
BA_ "GenMsgILSupport" BO_ 930 0;
BA_ "GenMsgCycleTime" BO_ 1677 1200;
BA_ "GenMsgDelayTime" BO_ 1677 10;
BA_ "GenMsgCycleTimeFast" BO_ 1677 200;
BA_ "GenMsgNrOfRepetition" BO_ 1677 5;
BA_ "MsgRoutingId" BO_ 1677 "109 ";
BA_ "GenMsgILSupport" BO_ 1677 0;
BA_ "GenMsgCycleTime" BO_ 1676 1200;
BA_ "GenMsgDelayTime" BO_ 1676 10;
BA_ "GenMsgCycleTimeFast" BO_ 1676 20;
BA_ "MsgRoutingId" BO_ 1676 "108 ";
BA_ "GenMsgILSupport" BO_ 1676 0;
BA_ "GenMsgCycleTime" BO_ 922 200;
BA_ "GenMsgDelayTime" BO_ 922 10;
BA_ "GenMsgCycleTimeFast" BO_ 922 20;
BA_ "GenMsgNrOfRepetition" BO_ 922 5;
BA_ "MsgRoutingId" BO_ 922 "107 ";
BA_ "GenMsgILSupport" BO_ 922 0;
BA_ "GenMsgCycleTime" BO_ 915 100;
BA_ "GenMsgDelayTime" BO_ 915 10;
BA_ "GenMsgCycleTimeFast" BO_ 915 20;
BA_ "GenMsgNrOfRepetition" BO_ 915 2;
BA_ "MsgRoutingId" BO_ 915 "106 ";
BA_ "GenMsgILSupport" BO_ 915 0;
BA_ "GenMsgCycleTime" BO_ 912 100;
BA_ "GenMsgDelayTime" BO_ 912 10;
BA_ "GenMsgCycleTimeFast" BO_ 912 50;
BA_ "GenMsgNrOfRepetition" BO_ 912 4;
BA_ "MsgRoutingId" BO_ 912 "105 ";
BA_ "GenMsgILSupport" BO_ 912 0;
BA_ "GenSigStartValue" SG_ 552 RDR228_6_5_BLOCKAGE_STS 5;
BA_ "GenSigSendType" SG_ 552 RDR228_4_3_WARN_DOW_2ST_R 3;
BA_ "GenSigSendType" SG_ 552 RDR228_4_4_WARN_DOW_2ST_L 3;
BA_ "GenSigStartValue" SG_ 552 RDR228_3_0_WARN_BSD_LCA_R_2ND 1;
BA_ "Fhi_SignalComment" SG_ 552 RDR228_2_6_ON_OFF_RDRSYS "SW情報：ﾗｽﾄﾒﾓﾘ

";
BA_ "GenSigStartValue" SG_ 552 RDR228_1_4_BATT_OFF_CAUSE 1;
BA_ "GenSigStartValue" SG_ 806 EYE326_5_0_TIME 16777215;
BA_ "GenSigStartValue" SG_ 806 EYE326_3_0_YEAR 127;
BA_ "GenSigStartValue" SG_ 806 EYE326_3_7_MONTH 15;
BA_ "GenSigStartValue" SG_ 805 EYE325_2_0_RAB_OFF 1;
BA_ "GenSigStartValue" SG_ 805 EYE325_2_1_SONAR_OFF 1;
BA_ "GenSigStartValue" SG_ 805 EYE325_2_6_RAB_DISABLE 1;
BA_ "GenSigStartValue" SG_ 805 EYE325_2_7_SONAR_DISABLE 1;
BA_ "GenSigStartValue" SG_ 805 EYE325_1_7_SONAR_NO_DISP 1;
BA_ "GenSigStartValue" SG_ 803 EYE323_7_0_ISA_OFFSET_CURR 10;
BA_ "GenSigStartValue" SG_ 803 EYE323_6_1_LDW_ON_OFF_SET 1;
BA_ "GenSigStartValue" SG_ 803 EYE323_5_3_FCW_ON_OFF_SET 1;
BA_ "GenSigStartValue" SG_ 801 EYE321_4_2_SRVD_LASTMEM_ST_REQ 1;
BA_ "GenSigStartValue" SG_ 801 EYE321_1_4_PRECRASH_BRAKE_OFF 1;
BA_ "GenSigStartValue" SG_ 801 EYE321_1_5_LANE_DEPARTURE_OFF 1;
BA_ "GenSigStartValue" SG_ 556 EYE22C_5_0_TRQDWN_FORCE_LIMIT 255;
BA_ "Fhi_SignalComment" SG_ 556 EYE22C_5_0_TRQDWN_FORCE_LIMIT "※

ｶﾞｿﾘﾝ車＝“トルクダウン指示”を送信

HEV車＝“駆動力制限値指示”を送信

";
BA_ "Fhi_SignalComment" SG_ 556 EYE22C_2_0_TGT_SPD_TRQ_FORCE "※

ｶﾞｿﾘﾝ車：“目標トルク”を送信

HEV車：“目標駆動力”を送信

";
BA_ "GenSigStartValue" SG_ 545 EYE221_5_0_TRQDWN_FORCE_LIMIT 255;
BA_ "Fhi_SignalComment" SG_ 545 EYE221_5_0_TRQDWN_FORCE_LIMIT "※

ｶﾞｿﾘﾝ車＝“トルクダウン指示”を送信

HEV車＝“駆動力制限値指示”を送信

";
BA_ "GenSigStartValue" SG_ 545 EYE221_4_2_FORCED_CANCEL_ACC 1;
BA_ "Fhi_SignalComment" SG_ 545 EYE221_2_0_TGT_SPD_TRQ_FORCE "※

ｶﾞｿﾘﾝ車：“目標トルク”を送信

HEV車：“目標駆動力”を送信

";
BA_ "GenSigStartValue" SG_ 279 SNR117_5_2_TORQUE_LIM_VAL 63;
BA_ "GenSigStartValue" SG_ 845 ADAS34D_15_0_CSTM_SNR_CLEAR 1;
BA_ "GenSigStartValue" SG_ 845 ADAS34D_15_1_CSTM_RAB 1;
BA_ "GenSigStartValue" SG_ 845 ADAS34D_15_2_CSTM_RAB_PED 1;
BA_ "GenSigStartValue" SG_ 845 ADAS34D_5_2_TORQUE_LIM_VAL 63;
BA_ "GenSigStartValue" SG_ 1109 CHR455_28_4_VEH_CHGPWRUPLMT 131070;
BA_ "GenSigStartValue" SG_ 1109 CHR455_25_0_CHGVLT_DISP 1022;
BA_ "GenSigStartValue" SG_ 1109 CHR455_23_0_CHGCUR_DISP 65534;
BA_ "GenSigStartValue" SG_ 1109 CHR455_19_2_DLTSOCCALC_FIN 126;
BA_ "GenSigStartValue" SG_ 1109 CHR455_18_3_DLTSOCCALC_STRT 126;
BA_ "GenSigStartValue" SG_ 1109 CHR455_16_6_EVSEOUTPWR 1022;
BA_ "GenSigStartValue" SG_ 1109 CHR455_13_3_CHG_FINTIM 137217726;
BA_ "GenSigStartValue" SG_ 1109 CHR455_10_7_DCPWRSUP_PWR_DISP 254;
BA_ "GenSigStartValue" SG_ 1109 CHR455_7_1_DCPWRSUP_ADMTIM 16382;
BA_ "GenSigStartValue" SG_ 1109 CHR455_6_1_CHGSTT 254;
BA_ "GenSigStartValue" SG_ 1109 CHR455_4_6_DCCHG_PWRUPLMT 14;
BA_ "GenSigStartValue" SG_ 1109 CHR455_4_2_ACCHG_CURUPLMT 14;
BA_ "GenSigStartValue" SG_ 1109 CHR455_3_3_CHG_HILMT 126;
BA_ "GenSigStartValue" SG_ 116 BEV074_3_0_RANGE_POS 6;
BA_ "GenSigSendType" SG_ 2564481223 AIL18DAE0C7_DIAG_DATA 2;
BA_ "GenSigSendType" SG_ 2564474848 DNT18DAC7E0_DIAG_DATA 2;
BA_ "GenSigSendType" SG_ 2564550625 CECU18DBEFE1_DIAG_DATA 2;
BA_ "GenSigStartValue" SG_ 996 CECU3E4_6_0_CHARGE_LEVEL_ENG_RUN 3;
BA_ "GenSigStartValue" SG_ 996 CECU3E4_6_4_CHARGE_LEVEL_IGN_ON 3;
BA_ "GenSigSendType" SG_ 1753 CECU6D9_2_0_RCC_DOOR_LOCK_REQ 3;
BA_ "GenSigSendType" SG_ 1753 CECU6D9_2_1_RCC_KEY_SEARCH_REQ 3;
BA_ "GenSigSendType" SG_ 1753 CECU6D9_2_2_RCC_BWAM_SETTING 3;
BA_ "GenSigSendType" SG_ 1753 CECU6D9_1_4_RCC_FLG 3;
BA_ "GenSigSendType" SG_ 1753 CECU6D9_0_0_CHECK_SUM 3;
BA_ "GenSigSendType" SG_ 1739 DCM6CB_5_0_DKY_SLOT_ID 4;
BA_ "GenSigSendType" SG_ 1739 DCM6CB_4_0_DKY_COM_REQ 4;
BA_ "GenSigSendType" SG_ 1739 DCM6CB_3_5_PNC_SW_REQ_SRV 4;
BA_ "GenSigSendType" SG_ 1739 DCM6CB_2_0_SHUTDOWN_REQ 4;
BA_ "GenSigSendType" SG_ 1739 DCM6CB_2_3_IGB_OFF_REQUEST 4;
BA_ "GenSigSendType" SG_ 1739 DCM6CB_2_4_IGB_ON_REQUEST 4;
BA_ "GenSigSendType" SG_ 1739 DCM6CB_2_5_REARGATE_UNLOCK_REQ 4;
BA_ "GenSigSendType" SG_ 1739 DCM6CB_2_6_DOOR_UNLOCK_REQ 4;
BA_ "GenSigSendType" SG_ 1739 DCM6CB_2_7_DOOR_LOCK_REQUEST 4;
BA_ "GenSigSendType" SG_ 1739 DCM6CB_1_4_REQ_SVR_HAZARD_ON 4;
BA_ "GenSigSendType" SG_ 1739 DCM6CB_1_5_HORNHZRD_DEACT_REQ 4;
BA_ "GenSigSendType" SG_ 1739 DCM6CB_1_6_HAZARD_ACT_REQ 4;
BA_ "GenSigSendType" SG_ 1739 DCM6CB_1_7_HORNHAZARD_ACT_REQ 4;
BA_ "GenSigStartValue" SG_ 930 MET3A2_7_0_FUEL_AMOUNT 254;
BA_ "GenSigStartValue" SG_ 1677 MET68D_5_0_TEMP_FOR_PPA 8191;
BA_ "Fhi_SignalComment" SG_ 1677 MET68D_2_0_ODO "000000h～98967Fh：正常

989680h～FFFFFEh：未使用

FFFFFFh：異常

";
BA_ "GenSigStartValue" SG_ 1676 MET68C_2_0_CRUISING_RADIUS 254;
BA_ "GenSigStartValue" SG_ 922 MET39A_5_2_AVE_FUEL_ECONOMY 1022;
BA_ "GenSigStartValue" SG_ 922 MET39A_4_0_INSTANTANEOUS_FUEL 1022;
BA_ "Fhi_SignalComment" SG_ 922 MET39A_3_1_STATUS_FUEL_LAMP "IGN_OFF時：IGN_OFF直前の値

";
BA_ "GenSigStartValue" SG_ 915 MET393_6_0_R_DIFF_TEMP 253;
BA_ "Fhi_SignalComment" SG_ 915 MET393_6_0_R_DIFF_TEMP "IGN-ON初回送信時はFEhを送信する。

";
BA_ "GenSigStartValue" SG_ 915 MET393_4_0_FUEL_LEVEL_RESIST 1022;
BA_ "Fhi_SignalComment" SG_ 915 MET393_3_5_SI_DRIVE_SW "IGN　ON時の初期値は各SIドライブとXモードの組み合わせにより異なる。

";
BA_ "GenSigStartValue" SG_ 915 MET393_2_0_OUTTEMP_FOR_DIAG 8191;
BA_ "Fhi_SignalComment" SG_ 912 MET390_6_0_SEATBELT_DRVR "IGN-OFF中は0送信

";
BA_ "Fhi_SignalComment" SG_ 912 MET390_6_1_SEATBELT_PASS "IGN-OFF中は0送信

";
BA_ "GenSigStartValue" SG_ 912 MET390_4_0_OUTTEMP_FOR_IND 254;
BA_ "Fhi_SignalComment" SG_ 912 MET390_4_0_OUTTEMP_FOR_IND "IGN-OFF中は初期値：FEh送信

";
BA_ "Fhi_SignalComment" SG_ 912 MET390_2_0_VEHICLE_SERIES "GW:ID390-B2b2~b0→ID2BE-B5b2~b0

";
BA_ "Fhi_SignalComment" SG_ 912 MET390_2_3_DESTINATION "GW:ID390-B2b6~b3→ID2BE-B5b6~b3

";
VAL_ 552 RDR228_7_0_EYE_TIMEOUT_ERROR_FLG 1 "EYE Timeout or Error detect" 0 "Normal" ;
VAL_ 552 RDR228_7_1_BLOCKAGE_FORMING_2 1 "Blocakge2" 0 "Normal" ;
VAL_ 552 RDR228_7_2_WARN_LCA_R_1ST 1 "ON" 0 "OFF" ;
VAL_ 552 RDR228_7_3_WARN_LCA_L_1ST 1 "ON" 0 "OFF" ;
VAL_ 552 RDR228_7_4_WARN_LCA_R_2ND 1 "ON" 0 "OFF" ;
VAL_ 552 RDR228_7_5_WARN_LCA_L_2ND 1 "ON" 0 "OFF" ;
VAL_ 552 RDR228_7_6_WARN_RCTA_R 1 "ON" 0 "OFF" ;
VAL_ 552 RDR228_7_7_WARN_RCTA_L 1 "ON" 0 "OFF" ;
VAL_ 552 RDR228_6_0_WARN_BSD_R_1ST 1 "ON" 0 "OFF" ;
VAL_ 552 RDR228_6_1_WARN_BSD_L_1ST 1 "ON" 0 "OFF" ;
VAL_ 552 RDR228_6_2_WARN_BSD_R_2ND 1 "ON" 0 "OFF" ;
VAL_ 552 RDR228_6_3_WARN_BSD_L_2ND 1 "ON" 0 "OFF" ;
VAL_ 552 RDR228_6_5_BLOCKAGE_STS 5 "INVALID" 4 "BLIND" 3 "HIGH" 2 "MID" 1 "LOW" 0 "NONE" ;
VAL_ 552 RDR228_5_0_BSD_R_E 1 "ON" 0 "OFF" ;
VAL_ 552 RDR228_5_1_BSD_L_E 1 "ON" 0 "OFF" ;
VAL_ 552 RDR228_5_2_LCA_R_E 1 "ON" 0 "OFF" ;
VAL_ 552 RDR228_5_3_LCA_L_E 1 "ON" 0 "OFF" ;
VAL_ 552 RDR228_5_4_BSD_R_A 1 "ON" 0 "OFF" ;
VAL_ 552 RDR228_5_5_BSD_L_A 1 "ON" 0 "OFF" ;
VAL_ 552 RDR228_5_6_LCA_R_A 1 "ON" 0 "OFF" ;
VAL_ 552 RDR228_5_7_LCA_L_A 1 "ON" 0 "OFF" ;
VAL_ 552 RDR228_4_0_DOW_ACTIVELAMP 1 "ON" 0 "OFF" ;
VAL_ 552 RDR228_4_1_WARN_DOW_1ST_R 1 "ON" 0 "OFF" ;
VAL_ 552 RDR228_4_2_WARN_DOW_1ST_L 1 "ON" 0 "OFF" ;
VAL_ 552 RDR228_4_3_WARN_DOW_2ST_R 1 "ON" 0 "OFF" ;
VAL_ 552 RDR228_4_4_WARN_DOW_2ST_L 1 "ON" 0 "OFF" ;
VAL_ 552 RDR228_4_6_CSTM_STS_BSD_LCA_2ND 1 "ON" 0 "OFF" ;
VAL_ 552 RDR228_4_7_CSTM_STS_RCTA 1 "ON" 0 "OFF" ;
VAL_ 552 RDR228_3_0_WARN_BSD_LCA_R_2ND 1 "ON" 0 "OFF" ;
VAL_ 552 RDR228_3_1_WARN_BSD_LCA_L_2ND 1 "ON" 0 "OFF" ;
VAL_ 552 RDR228_3_2_CSTM_STS_DOW 1 "ON" 0 "OFF" ;
VAL_ 552 RDR228_3_3_CSTM_STS_DOW_SFT_POS 1 "ONLY_P" 0 "OTHER_THAN_R" ;
VAL_ 552 RDR228_3_6_CSTM_DSP_BSD_LCA_2ND 1 "ON" 0 "OFF" ;
VAL_ 552 RDR228_3_7_CSTM_DSP_RCTA 1 "ON" 0 "OFF" ;
VAL_ 552 RDR228_2_0_CSTM_DSP_DOW 1 "ON" 0 "OFF" ;
VAL_ 552 RDR228_2_1_EYE_LOCAL_BUS1_FAIL 1 "EYE LOCAL BUS1 FAIL" 0 "NORMAL" ;
VAL_ 552 RDR228_2_2_CSTM_DSP_DOW_SFT_POS 1 "ON" 0 "OFF" ;
VAL_ 552 RDR228_2_3_ELK_STOP_REQ_FLG 1 "ELK stop request flag" 0 "NORMAL" ;
VAL_ 552 RDR228_2_4_FAIL_RDRSYS 1 "FAIL" 0 "NORMAL" ;
VAL_ 552 RDR228_2_5_STOP_RDRSYS 1 "HALT" 0 "NORMAL" ;
VAL_ 552 RDR228_2_6_ON_OFF_RDRSYS 1 "ON" 0 "OFF" ;
VAL_ 552 RDR228_2_7_BLOCKAGE_FORMING 1 "BLOCKAGE" 0 "NORMAL" ;
VAL_ 552 RDR228_1_4_BATT_OFF_CAUSE 1 "OFF required" 0 "ON required" ;
VAL_ 552 RDR228_1_5_CSTM_GLO_1 1 "ON" 0 "OFF" ;
VAL_ 552 RDR228_1_6_CSTM_GLO_3 1 "ON" 0 "OFF" ;
VAL_ 552 RDR228_1_7_CSTM_GLO_2 1 "ON" 0 "OFF" ;
VAL_ 967 EYE3C7_7_3_WARN_ESCALATION_REQ 7 "Reserve" 6 "MSB_WARN_5" 5 "MSB_WARN_4" 4 "MSB_WARN_3" 3 "MSB_WARN_2" 2 "MSB_WARN_1" 1 "Standby" 0 "OFF" ;
VAL_ 967 EYE3C7_7_6_AEB_MSB_LINK 3 "MSB_AEB_REQ" 2 "MSB_WARN" 1 "Standby" 0 "OFF" ;
VAL_ 967 EYE3C7_4_0_LKS_DMS_COOPERATION 1 "ON" 0 "OFF" ;
VAL_ 967 EYE3C7_4_1_LKS_ACTIVE 1 "ON" 0 "OFF" ;
VAL_ 967 EYE3C7_2_0_ALC_CONTROL 1 "ON" 0 "OFF" ;
VAL_ 967 EYE3C7_2_1_WINKER_OFF_REQ 1 "ON" 0 "OFF" ;
VAL_ 967 EYE3C7_2_2_HORN_HAZARD_ON_REQ 3 "Horn_On" 2 "HornHazard_On" 1 "Hazard_On" 0 "Off" ;
VAL_ 967 EYE3C7_2_4_DR_UNLOCK_REQ 1 "ドアアンロック要求" 0 "要求なし" ;
VAL_ 967 EYE3C7_2_5_WINKER_ON_REQ 3 "OFF_Request" 2 "Turn_Right_Request" 1 "Turn_Left_Request" 0 "OFF" ;
VAL_ 967 EYE3C7_2_7_MRM_ACTIVE 1 "ON" 0 "OFF" ;
VAL_ 966 EYE3C6_7_7_VEHICLE_L_LANE1 1 "ON" 0 "OFF" ;
VAL_ 966 EYE3C6_6_7_VEHICLE_R_LANE1 1 "ON" 0 "OFF" ;
VAL_ 966 EYE3C6_5_7_VEHICLE_MY_WAY1 1 "ON" 0 "OFF" ;
VAL_ 966 EYE3C6_3_0_RADER_RR 3 "TURN_ON3" 2 "TURN_ON2" 1 "TURN_ON1" 0 "TURN_OFF" ;
VAL_ 966 EYE3C6_3_2_RADER_RL 3 "TURN_ON3" 2 "TURN_ON2" 1 "TURN_ON1" 0 "TURN_OFF" ;
VAL_ 966 EYE3C6_3_4_RADER_FR 3 "No_Definition" 2 "BLINK" 1 "TURN_ON" 0 "TURN_OFF" ;
VAL_ 966 EYE3C6_3_6_RADER_FL 3 "No_Definition" 2 "BLINK" 1 "TURN_ON" 0 "TURN_OFF" ;
VAL_ 966 EYE3C6_2_0_RADER_R 3 "TURN_ON3" 2 "TURN_ON2" 1 "TURN_ON1" 0 "TURN_OFF" ;
VAL_ 966 EYE3C6_2_2_MY_WAY_LANE_CAR_COLOR 3 "TURN_AMBER" 2 "TURN_LIGHT_TJA" 1 "TURN_LIGHT" 0 "TURN_DARK" ;
VAL_ 966 EYE3C6_2_4_TARGET_CAR 7 "No_Definition" 6 "No_Definition" 5 "No_Definition" 4 "No_Definition" 3 "LEFT_LANE" 2 "RIGHT_LANE" 1 "OWN_LANE" 0 "OFF" ;
VAL_ 966 EYE3C6_2_7_ALC_STS 1 "ACTIVE" 0 "NOT_ACTIVE" ;
VAL_ 966 EYE3C6_1_4_L_LANE_CAR_COLOR 3 "TURN_AMBER" 2 "TURN_LIGHT_TJA" 1 "TURN_LIGHT" 0 "TURN_DARK" ;
VAL_ 966 EYE3C6_1_6_R_LANE_CAR_COLOR 3 "TURN_AMBER" 2 "TURN_LIGHT_TJA" 1 "TURN_LIGHT" 0 "TURN_DARK" ;
VAL_ 965 EYE3C5_7_0_GSR_AEBS_FUNC_INFO 1 "Requirement" 0 "No requirement" ;
VAL_ 965 EYE3C5_7_1_CSTM_CRV_ADJUST 3 "HARD" 2 "NORMAL" 1 "SOFT" 0 "OFF" ;
VAL_ 965 EYE3C5_7_3_BRAKE_HAPTIC_CURR 3 "BUZZER OFF/BREAK OFF" 2 "BUZZER OFF/BREAK ON" 1 "BUZZER ON/BREAK OFF" 0 "BUZZER ON/BREAK ON" ;
VAL_ 965 EYE3C5_7_5_SAFETY_MODE_FUNC_INFO 1 "Requirement" 0 "No requirement" ;
VAL_ 965 EYE3C5_7_6_SAFETY_MODE_CURR 1 "enable" 0 "disable" ;
VAL_ 965 EYE3C5_7_7_GSR_DDAW_FUNC_INFO 1 "Requirement" 0 "No requirement" ;
VAL_ 965 EYE3C5_6_0_IND_SAFETY_MODE 1 "TURN_ON" 0 "TURN_OFF" ;
VAL_ 965 EYE3C5_6_1_ALC_ACTIVE_L 1 "TURN_ON" 0 "TURN_OFF" ;
VAL_ 965 EYE3C5_6_2_FLASHING_IND_SAFETY 1 "Blinking" 0 "Nomally indicate" ;
VAL_ 965 EYE3C5_6_3_OVERTAKE_FUNC_INFO 1 "Requirement" 0 "No requirement" ;
VAL_ 965 EYE3C5_6_4_CRV_ADJUST_FUNC_INFO 1 "Requirement" 0 "No requirement" ;
VAL_ 965 EYE3C5_6_5_STRG_TOUCHSENSOR_WRNG 1 "TURN_ON" 0 "TURN_OFF" ;
VAL_ 965 EYE3C5_6_6_ALC_ACTIVE_R 1 "TURN_ON" 0 "TURN_OFF" ;
VAL_ 965 EYE3C5_6_7_CSTM_GSR_ISA 1 "Requirement" 0 "No requirement" ;
VAL_ 965 EYE3C5_5_0_LANE_COLOR_R 3 "BLUE" 2 "No_Definition" 1 "GRAY" 0 "OFF" ;
VAL_ 965 EYE3C5_5_2_LINE_LANE_R 3 "No_Definition" 2 "WHITE" 1 "GRAY" 0 "OFF" ;
VAL_ 965 EYE3C5_5_4_LANE_COLOR_L 3 "BLUE" 2 "No_Definition" 1 "GRAY" 0 "OFF" ;
VAL_ 965 EYE3C5_5_6_LINE_LANE_L 3 "No_Definition" 2 "WHITE" 1 "GRAY" 0 "OFF" ;
VAL_ 965 EYE3C5_4_4_ROAD_SHAPE_DIRECTION 1 "LEFT" 0 "RIGHT" ;
VAL_ 965 EYE3C5_4_5_CSTM_GSR_ELKS 1 "Requirement" 0 "No requirement" ;
VAL_ 965 EYE3C5_4_6_MY_WAY_COLOR 3 "BLUE" 2 "No_Definition" 1 "GRAY" 0 "OFF" ;
VAL_ 965 EYE3C5_3_0_AD_DRV_ICON 3 "No_Definition" 2 "BLUE" 1 "WHITE" 0 "TURN_OFF" ;
VAL_ 965 EYE3C5_3_2_AUTO_HANDLE_ICON 3 "No_Definition" 2 "BLINK" 1 "TURN_ON" 0 "TURN_OFF" ;
VAL_ 965 EYE3C5_3_4_WITH_HANDS_ICON 1 "ON" 0 "OFF" ;
VAL_ 965 EYE3C5_3_5_STRG_HAPTIC_WRNG 1 "TURN_ON" 0 "TURN_OFF" ;
VAL_ 965 EYE3C5_3_6_BRK_HPTC_FUNC_INFO 1 "Requirement" 0 "No requirement" ;
VAL_ 965 EYE3C5_3_7_SPECIAL_DISP_INFO 1 "Requirement" 0 "No requirement" ;
VAL_ 965 EYE3C5_2_0_SLOWDWN_CURVE_ICON 7 "No_Definition" 6 "BLINK③" 5 "TURN_ON③" 4 "BLINK②" 3 "TURN_ON②" 2 "BLINK①" 1 "TURN_ON①" 0 "TURN_OFF" ;
VAL_ 965 EYE3C5_2_3_FLASHING_IND 1 "BLINK" 0 "TURN_ON" ;
VAL_ 965 EYE3C5_2_4_ATTENTION_TOLLGATE 3 "No_Definition" 2 "BLINK" 1 "TURN_ON" 0 "TURN_OFF" ;
VAL_ 965 EYE3C5_2_6_MAPLOCATOR_IND 3 "No_Definition" 2 "FAIL_ON" 1 "TURN_ON" 0 "TURN_OFF" ;
VAL_ 965 EYE3C5_1_4_ISA_FAIL_IND 1 "TURN_ON" 0 "TURN_OFF" ;
VAL_ 965 EYE3C5_1_5_SLWF_OFF_IND 1 "TURN_ON" 0 "TURN_OFF" ;
VAL_ 965 EYE3C5_1_6_CSTM_SLWF_SET 1 "ON" 0 "OFF" ;
VAL_ 965 EYE3C5_1_7_CSTM_TSR_SOUND_SET 1 "ON" 0 "OFF" ;
VAL_ 964 EYE3C4_7_0_PCR_FAIL_OFF_IND 3 "No_Definition" 2 "FAIL" 1 "HALT/Customize OFF" 0 "NORMAL" ;
VAL_ 964 EYE3C4_7_2_AES_FAIL_OFF_IND 3 "No_Definition" 2 "FAIL" 1 "HALT/Customize OFF" 0 "NORMAL" ;
VAL_ 964 EYE3C4_7_4_LDP_FAIL_OFF_IND 3 "No_Definition" 2 "FAIL" 1 "HALT/Customize OFF" 0 "NORMAL" ;
VAL_ 964 EYE3C4_7_6_ELK_FAIL_OFF_IND 3 "No_Definition" 2 "FAIL" 1 "HALT/Customize OFF" 0 "NORMAL" ;
VAL_ 964 EYE3C4_6_0_MCAM_SYS_FAIL_HALT 3 "No_Definition" 2 "FAIL" 1 "HALT" 0 "NORMAL" ;
VAL_ 964 EYE3C4_6_2_MCAM_FUNC_INFO 1 "ON" 0 "OFF" ;
VAL_ 964 EYE3C4_6_3_EYE_DRV_ACTION_REQ 7 "No_Definition" 6 "No_Definition" 5 "No_Definition" 4 "restriction2" 3 "restriction1" 2 "permission" 1 "Prohibition" 0 "No Requirement" ;
VAL_ 964 EYE3C4_6_6_LDW_SND_OFF_FAIL_IND 3 "No_Definition" 2 "FAIL" 1 "OFF" 0 "TURN OFF" ;
VAL_ 964 EYE3C4_5_0_EAM_GREEN 3 "PATTERN3" 2 "PATTERN2" 1 "PATTERN1" 0 "TURN_OFF" ;
VAL_ 964 EYE3C4_5_2_EAM_BLUE 3 "PATTERN3" 2 "PATTERN2" 1 "PATTERN1" 0 "TURN_OFF" ;
VAL_ 964 EYE3C4_5_4_EAM_GREEN_2 3 "No_Definition" 2 "BLINK" 1 "ON" 0 "OFF" ;
VAL_ 964 EYE3C4_5_6_FCW_SND_OFF_FAIL_IND 3 "No_Definition" 2 "FAIL" 1 "OFF" 0 "TURN OFF" ;
VAL_ 964 EYE3C4_4_0_EAM_YELLOW 15 "No Definition" 14 "No_Definition" 13 "No_Definition" 12 "No_Definition" 11 "No_Definition" 10 "No_Definition" 9 "No_Definition" 8 "No_Definition" 7 "PATTERN⑦" 6 "PATTERN⑥" 5 "PATTERN⑤" 4 "PATTERN④" 3 "PATTERN③" 2 "PATTERN②" 1 "PATTERN①" 0 "TURN_OFF" ;
VAL_ 964 EYE3C4_4_4_EAM_RED 15 "No Definition" 14 "No_Definition" 13 "No_Definition" 12 "No_Definition" 11 "No_Definition" 10 "No_Definition" 9 "No_Definition" 8 "No_Definition" 7 "PATTERN⑦" 6 "PATTERN⑥" 5 "PATTERN⑤" 4 "PATTERN④" 3 "PATTERN③" 2 "PATTERN②" 1 "PATTERN①" 0 "TURN_OFF" ;
VAL_ 964 EYE3C4_3_0_CODE_NO_BUZZER 255 "Pattern255" 90 "Pattern90" 89 "Pattern89" 88 "Pattern88" 87 "Pattern87" 86 "Pattern86" 84 "Pattern84" 83 "Pattern83" 82 "Pattern82" 81 "Pattern81" 80 "Pattern80" 79 "Pattern79" 78 "Pattern78" 77 "Pattern77" 76 "Pattern76" 75 "Pattern75" 74 "Pattern74" 73 "Pattern73" 72 "Pattern72" 71 "Pattern71" 70 "Pattern70" 69 "Pattern69" 68 "Pattern68" 67 "Pattern67" 66 "Pattern66" 65 "Pattern65" 64 "Pattern64" 63 "Pattern63" 62 "Pattern62" 61 "Pattern61" 60 "Pattern60" 59 "Pattern59" 49 "Pattern49" 48 "Pattern48" 47 "Pattern47" 46 "Pattern46" 45 "Pattern45" 44 "Pattern44" 43 "Pattern43" 42 "Pattern42" 41 "Pattern41" 40 "Pattern40" 39 "Pattern39" 38 "Pattern38" 37 "Pattern37" 36 "Pattern36" 35 "Pattern35" 34 "Pattern34" 33 "Pattern33" 32 "Pattern32" 31 "Pattern31" 30 "Pattern30" 29 "Pattern29" 28 "Pattern28" 27 "Pattern27" 26 "Pattern26" 25 "Pattern25" 24 "Pattern24" 23 "Pattern23" 22 "Pattern22" 21 "Pattern21" 20 "Pattern20" 19 "Pattern19" 18 "Pattern18" 17 "Pattern17" 16 "Pattern16" 15 "Pattern15" 14 "Pattern14" 13 "Pattern13" 12 "Pattern12" 11 "Pattern11" 10 "Pattern10" 9 "Pattern9" 8 "Pattern8" 7 "Pattern7" 6 "Pattern6" 5 "Pattern5" 4 "Pattern4" 3 "Pattern3" 2 "Pattern2" 1 "Pattern1" 0 "OFF" ;
VAL_ 964 EYE3C4_2_0_CODE_WARN 255 "Pattern255" 166 "Pattern166" 165 "Pattern165" 164 "Pattern164" 163 "Pattern163" 162 "Pattern162" 161 "Pattern161" 160 "Pattern160" 159 "Pattern159" 158 "Pattern158" 157 "Pattern157" 156 "Pattern156" 155 "Pattern155" 154 "Pattern154" 153 "Pattern153" 152 "Pattern152" 151 "Pattern151" 150 "Pattern150" 149 "Pattern149" 148 "Pattern148" 147 "Pattern147" 146 "Pattern146" 145 "Pattern145" 144 "Pattern144" 90 "Pattern90" 89 "Pattern89" 88 "Pattern88" 87 "Pattern87" 86 "Pattern86" 85 "Pattern85" 84 "Pattern84" 83 "Pattern83" 82 "Pattern82" 81 "Pattern81" 80 "Pattern80" 79 "Pattern79" 78 "Pattern78" 77 "Pattern77" 76 "Pattern76" 75 "Pattern75" 74 "Pattern74" 73 "Pattern73" 72 "Pattern72" 71 "Pattern71" 70 "Pattern70" 69 "Pattern69" 68 "Pattern68" 67 "Pattern67" 66 "Pattern66" 65 "Pattern65" 64 "Pattern64" 63 "Pattern63" 62 "Pattern62" 61 "Pattern61" 60 "Pattern60" 59 "Pattern59" 58 "Pattern58" 57 "Pattern57" 56 "Pattern56" 55 "Pattern55" 54 "Pattern54" 53 "Pattern53" 52 "Pattern52" 51 "Pattern51" 50 "Pattern50" 49 "Pattern49" 48 "Pattern48" 47 "Pattern47" 46 "Pattern46" 45 "Pattern45" 44 "Pattern44" 43 "Pattern43" 42 "Pattern42" 41 "Pattern41" 40 "Pattern40" 39 "Pattern39" 38 "Pattern38" 37 "Pattern37" 36 "Pattern36" 35 "Pattern35" 34 "Pattern34" 33 "Pattern33" 32 "Pattern32" 31 "Pattern31" 30 "Pattern30" 29 "Pattern29" 28 "Pattern28" 27 "Pattern27" 26 "Pattern26" 25 "Pattern25" 24 "Pattern24" 23 "Pattern23" 22 "Pattern22" 21 "Pattern21" 20 "Pattern20" 19 "Pattern19" 18 "Pattern18" 17 "Pattern17" 16 "Pattern16" 15 "Pattern15" 14 "Pattern14" 13 "Pattern13" 12 "Pattern12" 11 "Pattern11" 10 "Pattern10" 9 "Pattern9" 8 "Pattern8" 7 "Pattern7" 6 "Pattern6" 5 "Pattern5" 4 "Pattern4" 3 "Pattern3" 2 "Pattern2" 1 "Pattern1" 0 "OFF" ;
VAL_ 964 EYE3C4_1_5_SNR_DRV_ACTION_REQ 7 "No_Definition" 6 "No_Definition" 5 "No_Definition" 4 "Restriction2" 3 "Restriction1" 2 "Permission" 1 "Prohibition" 0 "No Requirement" ;
VAL_ 806 EYE326_2_0_MRM_OPE_ST 1 "ON" 0 "OFF" ;
VAL_ 806 EYE326_2_1_DRIVER_TORQUE_STATE 3 "LEVEL_3" 2 "LEVEL_2" 1 "LEVEL_1" 0 "OFF" ;
VAL_ 806 EYE326_2_3_DRIVER_ACCEL_STATE 3 "LEVEL_3" 2 "LEVEL_2" 1 "LEVEL_1" 0 "OFF" ;
VAL_ 806 EYE326_1_4_SYS_ST 1 "ON" 0 "OFF" ;
VAL_ 806 EYE326_1_5_TAKE_OVR_REQ 3 "ON(Type3)" 2 "ON(Type2)" 1 "ON(Type1)" 0 "OFF" ;
VAL_ 806 EYE326_1_7_OVERRIDE 1 "ON" 0 "OFF" ;
VAL_ 805 EYE325_6_5_SONAR_DISP_INT 1 "DISP_INT_ON" 0 "DISP_INT_OFF" ;
VAL_ 805 EYE325_5_0_SONAR_R_L_CORNER_4LVL 7 "No_Definition" 6 "No_Definition" 5 "No_Definition" 4 "MOST_NEAR" 3 "NEAR" 2 "MIDDLE" 1 "FAR" 0 "CLEAR" ;
VAL_ 805 EYE325_5_3_SONAR_R_R_CORNER_4LVL 7 "No_Definition" 6 "No_Definition" 5 "No_Definition" 4 "MOST_NEAR" 3 "NEAR" 2 "MIDDLE" 1 "FAR" 0 "CLEAR" ;
VAL_ 805 EYE325_4_0_SONAR_R_CENTER 7 "No_Definition" 6 "No_Definition" 5 "No_Definition" 4 "MOST_NEAR" 3 "NEAR" 2 "MIDDLE" 1 "FAR" 0 "CLEAR" ;
VAL_ 805 EYE325_4_3_SONAR_LEVEL 7 "No_Definition" 6 "FAR" 5 "FIRST_BRAKE" 4 "SECOND_BRAKE" 3 "MOST_NEAR" 2 "NEAR" 1 "MIDDLE" 0 "OFF" ;
VAL_ 805 EYE325_4_6_RAB_WARNING 3 "RAB_Interrupt_3" 2 "RAB_Interrupt_2" 1 "RAB_Interrupt_1" 0 "OFF" ;
VAL_ 805 EYE325_3_0_SONAR_R_L_CORNER 3 "NEAR" 2 "MIDDLE" 1 "FAR" 0 "CLEAR" ;
VAL_ 805 EYE325_3_2_SONAR_R_R_CORNER 3 "NEAR" 2 "MIDDLE" 1 "FAR" 0 "CLEAR" ;
VAL_ 805 EYE325_3_4_SONAR_R_L_SIDE 3 "NEAR" 2 "MIDDLE" 1 "FAR" 0 "CLEAR" ;
VAL_ 805 EYE325_3_6_SONAR_R_R_SIDE 3 "NEAR" 2 "MIDDLE" 1 "FAR" 0 "CLEAR" ;
VAL_ 805 EYE325_2_0_RAB_OFF 1 "RAB_OFF" 0 "RAB_ON" ;
VAL_ 805 EYE325_2_1_SONAR_OFF 1 "SONAR_OFF" 0 "SONAR_ON" ;
VAL_ 805 EYE325_2_2_SONAR_SYS_HALT 3 "No_Definition" 2 "HALT_2" 1 "HALT_1" 0 "NO_HALT" ;
VAL_ 805 EYE325_2_4_SONAR_SYS_FAIL 3 "No_Definition" 2 "FAIL_2" 1 "FAIL_1" 0 "NO_FAIL" ;
VAL_ 805 EYE325_2_6_RAB_DISABLE 1 "ON" 0 "OFF" ;
VAL_ 805 EYE325_2_7_SONAR_DISABLE 1 "ON" 0 "OFF" ;
VAL_ 805 EYE325_1_4_CSTM_RAB_SET 1 "ON" 0 "OFF" ;
VAL_ 805 EYE325_1_5_CSTM_CLR_SNR_SET 1 "ON" 0 "OFF" ;
VAL_ 805 EYE325_1_6_RAB 1 "ON" 0 "OFF" ;
VAL_ 805 EYE325_1_7_SONAR_NO_DISP 1 "ON" 0 "OFF" ;
VAL_ 803 EYE323_7_5_SLIF_FUNC_INFO 1 "Requirement" 0 "No requirement" ;
VAL_ 803 EYE323_7_6_ISA_FUNC_INFO 1 "Requirement" 0 "No requirement" ;
VAL_ 803 EYE323_7_7_ISA_CUSTOMIZE_CURR 1 "ISA enable" 0 "ISA disable" ;
VAL_ 803 EYE323_6_0_LDW_OFFSW_INFO 1 "requirement" 0 "No requirement" ;
VAL_ 803 EYE323_6_1_LDW_ON_OFF_SET 1 "enable" 0 "disable" ;
VAL_ 803 EYE323_6_2_CSTM_DDAW_WARN_SET 1 "ON" 0 "OFF" ;
VAL_ 803 EYE323_6_3_IACC_FUNC_INFO 1 "Requirement" 0 "No requirement" ;
VAL_ 803 EYE323_6_5_CSTM_LDW_TIMING_SET 1 "LATE" 0 "EARLY" ;
VAL_ 803 EYE323_6_6_CSTM_LDW_TIMING 1 "Requirement" 0 "No requirement" ;
VAL_ 803 EYE323_6_7_SLOWDOWNL_FUNC_INFO 1 "Requirement" 0 "No requirement" ;
VAL_ 803 EYE323_5_0_CNG_GRN_CONT_CURR 1 "enable" 0 "disable" ;
VAL_ 803 EYE323_5_1_TRAFFIC_FUNC_INFO 1 "Requirement" 0 "No requirement" ;
VAL_ 803 EYE323_5_2_FCW_OFFSW_INFO 1 "requirement" 0 "No requirement" ;
VAL_ 803 EYE323_5_3_FCW_ON_OFF_SET 1 "enable" 0 "disable" ;
VAL_ 803 EYE323_5_4_WARNING_SEL_CURR 1 "Vibration" 0 "Sound" ;
VAL_ 803 EYE323_5_5_HAPT_FUNC_INFO 1 "Requirement" 0 "No requirement" ;
VAL_ 803 EYE323_5_6_TOLLGATE_CONT_CURR 1 "enable" 0 "disable" ;
VAL_ 803 EYE323_5_7_CURVE_CONT_CURR 1 "enable" 0 "disable" ;
VAL_ 803 EYE323_4_0_FCTB_ICON_L 3 "No_Definition" 2 "BLINK" 1 "TURN_ON" 0 "TURN_OFF" ;
VAL_ 803 EYE323_4_2_FCTB_ICON_R 3 "No_Definition" 2 "BLINK" 1 "TURN_ON" 0 "TURN_OFF" ;
VAL_ 803 EYE323_4_4_FCW_CONT_CURR 3 "OFF" 2 "FAR" 1 "NEAR" 0 "ON/STD." ;
VAL_ 803 EYE323_4_6_FCW_DISPLAY_SEL 3 "FULL SELECT" 2 "ON/OFF SELECT" 1 "Distance SELECT" 0 "TURN OFF" ;
VAL_ 803 EYE323_3_0_AES_FUNC_INFO 1 "Requirement" 0 "No requirement" ;
VAL_ 803 EYE323_3_1_CSTM_TSR_NO_ENTRY_SET 1 "ON" 0 "OFF" ;
VAL_ 803 EYE323_3_2_CSTM_TSR_STOP_SET 1 "ON" 0 "OFF" ;
VAL_ 803 EYE323_3_3_CSTM_TSR_GIVE_WAY_SET 1 "ON" 0 "OFF" ;
VAL_ 803 EYE323_3_4_WILDERNESS 1 "WILDERNESS" 0 "NOT_WILDERNESS" ;
VAL_ 803 EYE323_3_5_AES_OFF 1 "TURN_ON" 0 "TURN_OFF" ;
VAL_ 803 EYE323_3_6_FCTB_IND 3 "No_Definition" 2 "FAIL_ON" 1 "TURN_ON" 0 "TURN_OFF" ;
VAL_ 803 EYE323_2_0_CSTM_LDW_ALK_B 3 "ALK-B ON /LDW ON" 2 "ALK-B ON /LDW OFF" 1 "ALK-B OFF/LDW ON" 0 "ALK-B OFF/LDW OFF" ;
VAL_ 803 EYE323_2_2_CSTM_P_CR 1 "ON" 0 "OFF" ;
VAL_ 803 EYE323_2_3_SLOWDOWN_FUNC_INFO2 1 "Requirement" 0 "No requirement" ;
VAL_ 803 EYE323_2_4_CID_CODE_WARN 15 "Drowsiness attention" 14 "Eyes on request(3rd/4th)" 13 "Eyes on request(2nd)" 12 "MRM Interruption Vehicle" 11 "MRM Interruption Steering" 10 "MRM Interruption Lane change" 9 "MRM Stop" 8 "Handle steering" 7 "MRM Lane change Left" 6 "MRM Lane change Right" 5 "MRM Road shoulder Evacuation" 4 "B1 no-opr. cancel alarm" 3 "B1 no-opr. warning(long)" 2 "MRM Operation Notice" 1 "PreCrashBreak(1st)/Brake incr. alarm" 0 "No alarm " ;
VAL_ 803 EYE323_1_4_DISP_FOLLOW_FORWARD 1 "ON" 0 "OFF" ;
VAL_ 803 EYE323_1_5_KEEP_LINE_SENTER_ACT 1 "ON" 0 "OFF" ;
VAL_ 803 EYE323_1_6_DDAW_FAIL_OFF 3 "No_Definition" 2 "OFF" 1 "FAIL" 0 "TURN_OFF" ;
VAL_ 802 EYE322_7_0_CSTM_ACC_CONT_SET 3 "Lv.4" 2 "Lv.3" 1 "Lv.2" 0 "Lv.1" ;
VAL_ 802 EYE322_7_2_ELK_OFF_IND 1 "ON" 0 "OFF" ;
VAL_ 802 EYE322_7_3_LIGHT_EAM_YELLOW 3 "TURN_ON" 2 "BLINK_FAST" 1 "NONE" 0 "NONE" ;
VAL_ 802 EYE322_7_5_BROKEN_LINE_L 1 "DASHEDLINE" 0 "SOLIDLINE" ;
VAL_ 802 EYE322_7_6_TJA_ACTIVE 1 "ON" 0 "OFF" ;
VAL_ 802 EYE322_7_7_BROKEN_LINE_R 1 "DASHEDLINE" 0 "SOLIDLINE" ;
VAL_ 802 EYE322_6_0_CSTM_MIS_AT_START 3 "ON(20km/h)/(15mph)" 2 "ON(15km/h)/(10mph)" 1 "ON(10km/h)/(5mph)" 0 "OFF" ;
VAL_ 802 EYE322_6_2_CSTM_ALK_TJA_SET 1 "ON" 0 "OFF" ;
VAL_ 802 EYE322_6_3_CSTM_LANE_SET 1 "LEFT" 0 "RIGHT" ;
VAL_ 802 EYE322_6_4_LDP_OFF_IND 1 "TURN_ON" 0 "TURN_OFF" ;
VAL_ 802 EYE322_6_5_INDICATOR_MODE_L 3 "NONE" 2 "BLINK" 1 "TURN_ON" 0 "TURN_OFF" ;
VAL_ 802 EYE322_6_7_CSTM_ELK_SET 1 "ON" 0 "OFF" ;
VAL_ 802 EYE322_5_0_CSTM_MIS_AT_BACK 1 "ACTIVE" 0 "NON_ACTIVE" ;
VAL_ 802 EYE322_5_1_CSTM_ALK_TJA 1 "ACTIVE" 0 "NON_ACTIVE" ;
VAL_ 802 EYE322_5_2_CSTM_SAS 1 "ACTIVE" 0 "NON_ACTIVE" ;
VAL_ 802 EYE322_5_3_CSTM_HBA 1 "ACTIVE" 0 "NON_ACTIVE" ;
VAL_ 802 EYE322_5_4_CSTM_ACC_CONT 1 "ACTIVE" 0 "NON_ACTIVE" ;
VAL_ 802 EYE322_5_5_CSTM_LANE 1 "ACTIVE" 0 "NON_ACTIVE" ;
VAL_ 802 EYE322_5_6_LDW_SOUND_OFF_IND 1 "TURN_ON" 0 "TURN_OFF" ;
VAL_ 802 EYE322_5_7_CSTM_ELK_SET 1 "CSTM_ELK_ON" 0 "CSTM_ELK_OFF" ;
VAL_ 802 EYE322_4_0_CODE_WARN 31 "No_Definition" 30 "WARN_ALK_No_Steering_CONT(Only_Buzzer)" 29 "No_Definition" 28 "WARN_LKSA(No_Steering_CONT_Long)" 27 "ALK_Cancel(Only_Buzzer)" 26 "ACC_Cancel(Only_Buzzer)" 25 "Catch/Lost_Buzzer" 24 "Buzzer(No_Display)" 23 "No_Definition" 22 "No_Definition" 21 "No_Definition" 20 "Long Intervention(ALKB)" 19 "Blue Traffic Light Alert" 18 "WARN_ALK_System_Limit" 17 "No_Definition" 16 "WARN_ELK_Left" 15 "WARN_ELK_Right" 14 "Forward_Start_INFO" 13 "WARN_Lane_Sway" 12 "WARN_Lane_Departure(LDW/LDP) Left" 11 "WARN_Lane_Departure(LDW/LDP) Right" 10 "No_Definition" 9 "PreCrash_BRK(Stop_Warning)" 8 "WARN_Red_Signal" 7 "No_Definition" 6 "No_Definition" 5 "AfterPreCrash_BRK(Stopping)" 4 "AT_Accidental_Backward_Start(FMW)" 3 "AT_Accidental_Backward_Start(Speed_Limit_Warning)" 2 "PreCrash_BRK(First)" 1 "PreCrash_BRK(Second)" 0 "No_Warning" ;
VAL_ 802 EYE322_4_5_CSTM_GSR 1 "Requirement" 0 "No Requirement" ;
VAL_ 802 EYE322_3_0_LANE_L 3 "No_Definition" 2 "BLINK" 1 "TURN_ON" 0 "TURN_OFF" ;
VAL_ 802 EYE322_3_2_LANE_R 3 "No_Definition" 2 "BLINK" 1 "TURN_ON" 0 "TURN_OFF" ;
VAL_ 802 EYE322_3_4_LANE_L_COLOR 3 "AMBER" 2 "OTHER" 1 "WHITE" 0 "SUB" ;
VAL_ 802 EYE322_3_6_LANE_R_COLOR 3 "AMBER" 2 "OTHER" 1 "WHITE" 0 "SUB" ;
VAL_ 802 EYE322_2_0_FCW_OFF_IND 1 "TURN_ON" 0 "TURN_OFF" ;
VAL_ 802 EYE322_2_1_MOV_EYESIGHT_SCREEN 1 "DISP_EYE" 0 "OFF" ;
VAL_ 802 EYE322_2_2_ALK_ICON 3 "BLINK_GREEN" 2 "TURN_ON_GREEN" 1 "TURN_ON_WHITE" 0 "TURN_OFF" ;
VAL_ 802 EYE322_2_4_INDICATOR_CTRL_REQ 1 "ON" 0 "OFF" ;
VAL_ 802 EYE322_2_5_INDICATOR_MODE_R 3 "NONE" 2 "BLINK" 1 "TURN_ON" 0 "TURN_OFF" ;
VAL_ 802 EYE322_2_7_LIMITER_BACK_SPEED 1 "ON" 0 "OFF" ;
VAL_ 802 EYE322_1_4_CODE_NO_BUZZER 7 "WARN_LKSA(No_Steering_CONT_Long)" 6 "AfterPreCrash_BRK(Running)" 5 "Driver_Over_Ride" 4 "MT_Put_In_Gear_Request" 3 "MT_Shift_Down_Request" 2 "MT_Shift_Up_Request" 1 "WARN_LKSA(No_Steering_CONT)" 0 "No_Warning" ;
VAL_ 802 EYE322_1_7_DISTWARN_DMS 1 "ON" 0 "OFF" ;
VAL_ 801 EYE321_7_0_INFO_DIST_FORWARD 15 "75 ≦ x" 14 "70 ≦ x < 75" 13 "65 ≦ x < 70" 12 "60 ≦ x < 65" 11 "55 ≦ x < 60" 10 "50 ≦ x < 55" 9 "45 ≦ x < 50" 8 "40 ≦ x < 45" 7 "35 ≦ x < 40" 6 "30 ≦ x < 35" 5 "25 ≦ x < 30" 4 "20 ≦ x < 25" 3 "15 ≦ x < 20" 2 "10 ≦ x < 15" 1 "5 ≦ x < 10" 0 "0 ≦ x < 5" ;
VAL_ 801 EYE321_7_4_INFO_KEEP_STOP 1 "TURN_ON" 0 "TURN_OFF" ;
VAL_ 801 EYE321_7_5_INFO_READY 1 "TURN_ON" 0 "TURN_OFF" ;
VAL_ 801 EYE321_7_6_INFO_SET_CC 1 "TURN_ON" 0 "TURN_OFF" ;
VAL_ 801 EYE321_7_7_INFO_OFF 1 "TURN_ON" 0 "TURN_OFF" ;
VAL_ 801 EYE321_6_0_FAIL_EYESIGHT 1 "FAIL" 0 "NORMAL" ;
VAL_ 801 EYE321_6_1_MOV_EYESIGHT_SCREEN 1 "DISP_EYE" 0 "OFF" ;
VAL_ 801 EYE321_6_2_IND_VEHICLE 1 "TURN_ON" 0 "TURN_OFF" ;
VAL_ 801 EYE321_6_3_BRAKELAMP_VEHICLE 1 "TURN_ON" 0 "TURN_OFF" ;
VAL_ 801 EYE321_6_4_IND_FORWARD_VECL 1 "TURN_ON" 0 "TURN_OFF" ;
VAL_ 801 EYE321_6_5_BRAKELAMP_FORWARD 1 "TURN_ON" 0 "TURN_OFF" ;
VAL_ 801 EYE321_6_6_CC_OR_LIM_SON 1 "SET" 0 "Non-SET" ;
VAL_ 801 EYE321_6_7_TEMP_OFF_STATE 1 "Temp OFF State" 0 "Normal State" ;
VAL_ 801 EYE321_4_0_ACC_MODE 3 "No_Definition" 2 "SAS" 1 "CC" 0 "ACC" ;
VAL_ 801 EYE321_4_2_SRVD_LASTMEM_ST_REQ 1 "LASTMEM_STARTUP_REQ" 0 "ON_STARTUP_REQ" ;
VAL_ 801 EYE321_4_3_INFO_MAIN_CC 3 "TURN_ON_BLUE or BLINK_GREEN" 2 "TURN_ON_GREEN" 1 "TURN_ON_WHITE" 0 "TURN_OFF" ;
VAL_ 801 EYE321_4_5_TRAFFIC_LIGHT 7 "No_Definition" 6 "No_Definition" 5 "BLINK_BLUE" 4 "TURN_ON_BLUE" 3 "BLINK_RED" 2 "TURN_ON_RED" 1 "TURN_ON_DISP" 0 "TURN_OFF" ;
VAL_ 801 EYE321_3_0_CODE_HALT 7 "HALT_NOTICE" 6 "No_Definition" 5 "No_Definition" 4 "HALT_E3" 3 "HALT_E2" 2 "HALT_E1-2" 1 "HALT_E1-1" 0 "No HALT" ;
VAL_ 801 EYE321_3_3_ELK_EQUIP 1 "EQUIP_ELK" 0 "NOT_EQUIP_ELK" ;
VAL_ 801 EYE321_3_4_SET_DIST 7 "No_Definition" 6 "No_Definition" 5 "No_Definition" 4 "Distance(4)" 3 "Distance(3)" 2 "Distance(2)" 1 "Distance(1)" 0 "No_Display" ;
VAL_ 801 EYE321_3_7_TJA 1 "ON" 0 "OFF" ;
VAL_ 801 EYE321_2_0_ACC_CANCEL_OR_CSTM 15 "No_Definition" 14 "No_Definition" 13 "No_Definition" 12 "No_Definition" 11 "Pattern11" 10 "Pattern10" 9 "Pattern9" 8 "Pattern8" 7 "Pattern7" 6 "Pattern6" 5 "Pattern5" 4 "Pattern4" 3 "Pattern3" 2 "Pattern2" 1 "Pattern1" 0 "OFF" ;
VAL_ 801 EYE321_2_4_ALK_CANCEL_OR_CSTM 7 "Lka_Cancel_DMS_Undetected" 6 "No_Definition" 5 "Lka_Cancel_Speed_High" 4 "Lka_Cancel_Speed_Low" 3 "Lka_Cancel_Other" 2 "Lka_Cancel_No_Steering_CONT" 1 "Lka_Cancel_Curve" 0 "No_Display" ;
VAL_ 801 EYE321_2_7_ALK_CANCEL_DISP_TYPE 1 "ALK-Bｷｬﾝｾﾙ時" 0 "ALK-Cｷｬﾝｾﾙ時" ;
VAL_ 801 EYE321_1_4_PRECRASH_BRAKE_OFF 1 "TURN_ON" 0 "TURN_OFF" ;
VAL_ 801 EYE321_1_5_LANE_DEPARTURE_OFF 1 "TURN_ON" 0 "TURN_OFF" ;
VAL_ 801 EYE321_1_6_MET_AD_DRV_ASS 1 "ON" 0 "OFF" ;
VAL_ 801 EYE321_1_7_ALC_EQUIP 1 "ON" 0 "OFF" ;
VAL_ 556 EYE22C_7_0_COMMANDSW_CC 7 "MSA_SW_ON" 6 "CANCEL_SW_ON" 5 "DISTANCE_SW_ON" 4 "RES/+_SW_ON" 3 "LKS_SW_ON" 2 "SET/-_SW_ON" 1 "CRUISE_MAIN_SW_ON" 0 "ALL_SW_OFF" ;
VAL_ 556 EYE22C_7_3_MODE_CC 1 "CC" 0 "ACC" ;
VAL_ 556 EYE22C_7_4_CC_SETLAMP_INFO 1 "ON" 0 "OFF" ;
VAL_ 556 EYE22C_7_5_MSA_CNT_STS_EGI_HEV 1 "During control" 0 "Uncontrolled" ;
VAL_ 556 EYE22C_7_6_SET_MSA 1 "SET" 0 "Non-SET" ;
VAL_ 556 EYE22C_7_7_SET_CC 1 "SET" 0 "Non-SET" ;
VAL_ 556 EYE22C_4_0_BLIPPING_INHI 1 "ON" 0 "OFF" ;
VAL_ 556 EYE22C_4_4_ACTIVE_BRAKE_ACC 1 "ACTIVE" 0 "PASSIVE" ;
VAL_ 556 EYE22C_4_5_REQ_FMW 1 "REQ" 0 "NON_REQ" ;
VAL_ 556 EYE22C_4_6_FLG_BEFORE_RESERVE 1 "Keep Stop&Before Reseve" 0 "Not Keep Stop" ;
VAL_ 556 EYE22C_4_7_REQ_TARGET_TORQUE 1 "TORQUE" 0 "FORCE" ;
VAL_ 556 EYE22C_1_4_FLG_ADAPTIVE_CC 1 "ADAPTIVE_CC" 0 "OTHER" ;
VAL_ 556 EYE22C_1_5_MAIN_CC 1 "ON" 0 "OFF" ;
VAL_ 556 EYE22C_1_6_FLG_EYESIGHT_VERSION 1 "Ver.4" 0 "Ver.3" ;
VAL_ 556 EYE22C_1_7_FAIL_EYESIGHT 1 "FAIL" 0 "NORMAL" ;
VAL_ 545 EYE221_7_0_COMMANDSW_CC 7 "MSAｽｲｯﾁON" 6 "ｷｬﾝｾﾙｽｲｯﾁON" 5 "RES/＋（深）ｽｲｯﾁON" 4 "RES/＋（浅）ｽｲｯﾁON" 3 "SET/－（深）ｽｲｯﾁON" 2 "SET/－（浅）ｽｲｯﾁON" 1 "CRUISEﾒｲﾝｽｲｯﾁON" 0 "ｸﾙｺﾝｽｲｯﾁALL OFF" ;
VAL_ 545 EYE221_7_3_MODE_CC 1 "CC" 0 "ACC" ;
VAL_ 545 EYE221_7_4_MSA_CNT_STS_EGI_HEV 2 "override" 1 "control" 0 "NON_Control" ;
VAL_ 545 EYE221_7_6_EQUIP_MSA 1 "EQUIP_MSA" 0 "NOT_EQUIP_MSA" ;
VAL_ 545 EYE221_7_7_INHIBIT_FUEL_CUT 1 "FUELCUT_NG" 0 "FUELCUT_OK" ;
VAL_ 545 EYE221_4_0_STATE_TRACKING 1 "TRACKING" 0 "NON_TRACKING" ;
VAL_ 545 EYE221_4_1_STATE_LSF 1 "LSF" 0 "NON_LSF" ;
VAL_ 545 EYE221_4_2_FORCED_CANCEL_ACC 1 "CANCEL" 0 "NON_CANCEL" ;
VAL_ 545 EYE221_4_3_BRAKE_TYPE 1 "ACTIVE_BOOSTER" 0 "VDC" ;
VAL_ 545 EYE221_4_4_ACTIVE_BRAKE_ACC 1 "ACTIVE" 0 "PASSIVE" ;
VAL_ 545 EYE221_4_5_REQ_FMW 1 "REQ" 0 "NON_REQ" ;
VAL_ 545 EYE221_4_6_FLG_BEFORE_RESERVE 1 "Keep Stop&Before Reseve" 0 "Not Keep Stop" ;
VAL_ 545 EYE221_1_4_FLG_ADAPTIVE_CC 1 "ADAPTIVE_CC" 0 "OTHER" ;
VAL_ 545 EYE221_1_5_CANCEL_SW_INFO 1 "ACTIVE" 0 "NON_ACTIVE" ;
VAL_ 545 EYE221_1_6_FLG_EYESIGHT_VERSION 1 "Ver.4" 0 "Ver.3" ;
VAL_ 545 EYE221_1_7_FAIL_EYESIGHT 1 "FAIL" 0 "NORMAL" ;
VAL_ 287 ADAS11F_3_4_HANDSOFF_FLG 1 "HANDSON" 0 "HANDSOFF" ;
VAL_ 287 ADAS11F_3_5_TRQ_LIMIT_REQ_FLG 1 "ON" 0 "OFF" ;
VAL_ 292 ADAS124_7_3_TRQ_RATE_CHG 1 "RATE2" 0 "RATE1" ;
VAL_ 292 ADAS124_7_4_STR_RATE_CHG 3 "RATE3" 2 "RATE3" 1 "RATE2" 0 "RATE1" ;
VAL_ 292 ADAS124_7_6_OVR_STR_LVL 3 "LV4" 2 "LV3" 1 "LV2" 0 "LV1" ;
VAL_ 292 ADAS124_1_4_ACTIVE_FLG 3 "NORMAL" 2 "STEER_ANGLE" 1 "NORMAL_AND_STEER_ANGLE" 0 "NORMAL" ;
VAL_ 279 SNR117_16_0_CSTM_SNR_DSPREEQ 3 "No_Definition" 2 "Disp(Gray out)" 1 "Disp(Normal)" 0 "No Disp" ;
VAL_ 279 SNR117_16_2_CSTM_RAB_DSPREQ 3 "No_Definition" 2 "Disp(Gray out)" 1 "Disp(Normal)" 0 "No Disp" ;
VAL_ 279 SNR117_16_4_CSTM_PED_DSPREQ 3 "No_Definition" 2 "Disp(Gray out)" 1 "Disp(Normal)" 0 "No Disp" ;
VAL_ 279 SNR117_16_6_CSTM_PEDTIM_DSPREQ 3 "No_Definition" 2 "Disp(Gray out)" 1 "Disp(Normal)" 0 "No Disp" ;
VAL_ 279 SNR117_15_0_CSTM_SNR_CLEAR 1 "ON" 0 "OFF" ;
VAL_ 279 SNR117_15_1_CSTM_RAB 1 "ON" 0 "OFF" ;
VAL_ 279 SNR117_15_2_CSTM_RAB_PED 1 "ON" 0 "OFF" ;
VAL_ 279 SNR117_15_3_CSTM_RAB_PED_TIMING 3 "No_Definition" 2 "Far" 1 "Near" 0 "Middle" ;
VAL_ 279 SNR117_14_0_RAB_WARNING 7 "No_Definition" 6 "No_Definition" 5 "RAB_Interrupt_5" 4 "RAB_Interrupt_4" 3 "RAB_Interrupt_3" 2 "RAB_Interrupt_2" 1 "RAB_Interrupt_1" 0 "OFF" ;
VAL_ 279 SNR117_14_3_SONAR_LEVEL 8 "No_Definition" 7 "Pedestrian" 6 "FIRST_BRAKE" 5 "FAR" 4 "MIDDLE" 3 "NEAR" 2 "MOST_NEAR" 1 "SECOND_BRAKE" 0 "OFF" ;
VAL_ 279 SNR117_13_0_PED_WARN_CENTER 1 "ON" 0 "OFF" ;
VAL_ 279 SNR117_13_1_PED_WARN_LEFT 1 "ON" 0 "OFF" ;
VAL_ 279 SNR117_13_2_PED_WARN_RIGHT 1 "ON" 0 "OFF" ;
VAL_ 279 SNR117_13_3_RAB_TRIG_TYPE 3 "Cyclist" 2 "Pedestrian" 1 "USS" 0 "NoAct" ;
VAL_ 279 SNR117_9_0_SONAR_R_R_CORNER_4LV 7 "No_Definition" 6 "No_Definition" 5 "No_Definition" 4 "MOST_NEAR" 3 "NEAR" 2 "MIDDLE" 1 "FAR" 0 "CLEAR" ;
VAL_ 279 SNR117_8_0_SONAR_DISP_INT 1 "DISP_INT_ON" 0 "DISP_INT_OFF" ;
VAL_ 279 SNR117_8_1_SONAR_R_CENTER 7 "No_Definition" 6 "No_Definition" 5 "No_Definition" 4 "MOST_NEAR" 3 "NEAR" 2 "MIDDLE" 1 "FAR" 0 "CLEAR" ;
VAL_ 279 SNR117_8_4_SONAR_R_L_CORNER_4LV 7 "No_Definition" 6 "No_Definition" 5 "No_Definition" 4 "MOST_NEAR" 3 "NEAR" 2 "MIDDLE" 1 "FAR" 0 "CLEAR" ;
VAL_ 279 SNR117_7_0_SONAR_SYS_FAIL 3 "No_Definition" 2 "FAIL_2" 1 "FAIL_1" 0 "NO_FAIL" ;
VAL_ 279 SNR117_7_2_RAB_HALT 3 "No_Definition" 2 "HALT_2" 1 "HALT_1" 0 "NO_HALT" ;
VAL_ 279 SNR117_7_4_CAMERA_FAIL 3 "No_Definition" 2 "FAIL_2" 1 "FAIL_1" 0 "NO_FAIL" ;
VAL_ 279 SNR117_7_6_RAB_PED_HALT 3 "No_Definition" 2 "HALT_2" 1 "HALT_1" 0 "NO_HALT" ;
VAL_ 279 SNR117_6_0_REQ_ACT_EPB 1 "ON" 0 "OFF" ;
VAL_ 279 SNR117_6_1_STOP_HOJI_BUZ_ACT 1 "ON" 0 "OFF" ;
VAL_ 279 SNR117_6_2_RAB_OFF 1 "RAB_OFF" 0 "RAB_ON" ;
VAL_ 279 SNR117_6_3_SONAR_OFF 1 "SONAR_OFF" 0 "SONAR_ON" ;
VAL_ 279 SNR117_6_4_RAB_PED_OFF 1 "RAB_PED_OFF" 0 "RAB_PED_ON" ;
VAL_ 279 SNR117_6_5_SONAR_HALT 3 "No_Definition" 2 "HALT_2" 1 "HALT_1" 0 "NO_HALT" ;
VAL_ 279 SNR117_5_0_YOATSU_ACT 1 "ON" 0 "OFF" ;
VAL_ 279 SNR117_5_1_TORQUE_LIM_ACT 1 "ON" 0 "OFF" ;
VAL_ 279 SNR117_4_0_RAB_ACT 1 "ON" 0 "OFF" ;
VAL_ 279 SNR117_3_0_RAB 1 "ON" 0 "OFF" ;
VAL_ 279 SNR117_3_1_RAB_PED 1 "ON" 0 "OFF" ;
VAL_ 845 ADAS34D_16_0_CSTM_SNR_DSPREEQ 3 "No_Definition" 2 "Disp(Gray out)" 1 "Disp(Normal)" 0 "No Disp" ;
VAL_ 845 ADAS34D_16_2_CSTM_RAB_DSPREQ 3 "No_Definition" 2 "Disp(Gray out)" 1 "Disp(Normal)" 0 "No Disp" ;
VAL_ 845 ADAS34D_16_4_CSTM_PED_DSPREQ 3 "No_Definition" 2 "Disp(Gray out)" 1 "Disp(Normal)" 0 "No Disp" ;
VAL_ 845 ADAS34D_16_6_CSTM_PEDTIM_DSPREQ 3 "No_Definition" 2 "Disp(Gray out)" 1 "Disp(Normal)" 0 "No Disp" ;
VAL_ 845 ADAS34D_15_0_CSTM_SNR_CLEAR 1 "ON" 0 "OFF" ;
VAL_ 845 ADAS34D_15_1_CSTM_RAB 1 "ON" 0 "OFF" ;
VAL_ 845 ADAS34D_15_2_CSTM_RAB_PED 1 "ON" 0 "OFF" ;
VAL_ 845 ADAS34D_15_3_CSTM_RAB_PED_TIMING 3 "No_Definition" 2 "Far" 1 "Near" 0 "Middle" ;
VAL_ 845 ADAS34D_15_5_CSTM_TEMP_OFF 3 "未定義" 2 "OFF" 1 "ON" 0 "No Disp" ;
VAL_ 845 ADAS34D_15_7_TEMP_OFF_STATE 1 "Temp OFF State" 0 "Normal State" ;
VAL_ 845 ADAS34D_14_0_RAB_WARNING 7 "No_Definition" 6 "No_Definition" 5 "RAB_Interrupt_5" 4 "RAB_Interrupt_4" 3 "RAB_Interrupt_3" 2 "RAB_Interrupt_2" 1 "RAB_Interrupt_1" 0 "OFF" ;
VAL_ 845 ADAS34D_14_3_SONAR_LEVEL 8 "No_Definition" 7 "Pedestrian" 6 "FIRST_BRAKE" 5 "FAR" 4 "MIDDLE" 3 "NEAR" 2 "MOST_NEAR" 1 "SECOND_BRAKE" 0 "OFF" ;
VAL_ 845 ADAS34D_13_0_PED_WARN_CENTER 1 "ON" 0 "OFF" ;
VAL_ 845 ADAS34D_13_1_PED_WARN_LEFT 1 "ON" 0 "OFF" ;
VAL_ 845 ADAS34D_13_2_PED_WARN_RIGHT 1 "ON" 0 "OFF" ;
VAL_ 845 ADAS34D_13_3_RAB_TRIG_TYPE 3 "Cyclist" 2 "Pedestrian" 1 "USS" 0 "NoAct" ;
VAL_ 845 ADAS34D_9_0_SONAR_R_R_CORNER_4LV 7 "No_Definition" 6 "No_Definition" 5 "No_Definition" 4 "MOST_NEAR" 3 "NEAR" 2 "MIDDLE" 1 "FAR" 0 "CLEAR" ;
VAL_ 845 ADAS34D_8_0_SONAR_DISP_INT 1 "DISP_INT_ON" 0 "DISP_INT_OFF" ;
VAL_ 845 ADAS34D_8_1_SONAR_R_CENTER 7 "No_Definition" 6 "No_Definition" 5 "No_Definition" 4 "MOST_NEAR" 3 "NEAR" 2 "MIDDLE" 1 "FAR" 0 "CLEAR" ;
VAL_ 845 ADAS34D_8_4_SONAR_R_L_CORNER_4LV 7 "No_Definition" 6 "No_Definition" 5 "No_Definition" 4 "MOST_NEAR" 3 "NEAR" 2 "MIDDLE" 1 "FAR" 0 "CLEAR" ;
VAL_ 845 ADAS34D_7_0_SONAR_SYS_FAIL 3 "No_Definition" 2 "FAIL_2" 1 "FAIL_1" 0 "NO_FAIL" ;
VAL_ 845 ADAS34D_7_2_RAB_HALT 3 "No_Definition" 2 "HALT_2" 1 "HALT_1" 0 "NO_HALT" ;
VAL_ 845 ADAS34D_7_4_CAMERA_FAIL 3 "No_Definition" 2 "FAIL_2" 1 "FAIL_1" 0 "NO_FAIL" ;
VAL_ 845 ADAS34D_7_6_RAB_PED_HALT 3 "No_Definition" 2 "HALT_2" 1 "HALT_1" 0 "NO_HALT" ;
VAL_ 845 ADAS34D_6_0_REQ_ACT_EPB 1 "ON" 0 "OFF" ;
VAL_ 845 ADAS34D_6_1_STOP_HOJI_BUZ_ACT 1 "ON" 0 "OFF" ;
VAL_ 845 ADAS34D_6_2_RAB_OFF 1 "RAB_OFF" 0 "RAB_ON" ;
VAL_ 845 ADAS34D_6_3_SONAR_OFF 1 "SONAR_OFF" 0 "SONAR_ON" ;
VAL_ 845 ADAS34D_6_4_RAB_PED_OFF 1 "RAB_PED_OFF" 0 "RAB_PED_ON" ;
VAL_ 845 ADAS34D_6_5_SONAR_HALT 3 "No_Definition" 2 "HALT_2" 1 "HALT_1" 0 "NO_HALT" ;
VAL_ 845 ADAS34D_5_0_YOATSU_ACT 1 "ON" 0 "OFF" ;
VAL_ 845 ADAS34D_5_1_TORQUE_LIM_ACT 1 "ON" 0 "OFF" ;
VAL_ 845 ADAS34D_4_0_RAB_ACT 1 "ON" 0 "OFF" ;
VAL_ 845 ADAS34D_3_0_RAB 1 "ON" 0 "OFF" ;
VAL_ 845 ADAS34D_3_1_RAB_PED 1 "ON" 0 "OFF" ;
VAL_ 1109 CHR455_31_3_CHGCNRLOCSTT_DISPREQ 2 "Lock_Display_Request" 1 "Unlock_Display_Request" 0 "Hidden" ;
VAL_ 1109 CHR455_27_4_V2H_MODE 1 "ON_(Charge/Discharge_Possible)" 0 "OFF" ;
VAL_ 1109 CHR455_26_4_DCPWRSUPSTT 255 "Not_Connected_or_Out_of_Range" 7 "Power_Supply_Abnormality" 6 "Connector_Fault" 5 "Power_Supply_Stopped" 4 "Power_Supplying" 3 "Communicating" 2 "Before_Power_Supply" 1 "Before_Connection" 0 "Non_Power_Supply" ;
VAL_ 1109 CHR455_26_3_CHGMNTDISP_REQ 1 "Request" 0 "No_Request" ;
VAL_ 1109 CHR455_26_2_MNTLIT_REQ 1 "Request" 0 "No_Request" ;
VAL_ 1109 CHR455_22_1_CHGSTPCOMP 1 "通知あり" 0 "通知なし" ;
VAL_ 1109 CHR455_18_2_STLMT_TYPE 1 "PnC" 0 "EIM" ;
VAL_ 1109 CHR455_18_1_ACDC_INFO 1 "DC" 0 "AC" ;
VAL_ 1109 CHR455_6_1_CHGSTT 255 "Not_Connected_or_Out_of_Range" 254 "Initial_Value" 9 "Warming_Up" 8 "Charging_Abnormality" 7 "Connector_Fault" 6 "Charging_Reservation_Standby" 5 "Charging_Complete" 4 "Charging" 3 "Communicating" 2 "Before_Charging" 1 "Before_Connection" 0 "Non_Charging" ;
VAL_ 1109 CHR455_4_6_DCCHG_PWRUPLMT 15 "Fail" 14 "Initial" 8 "50kW" 7 "75kW" 6 "100kW" 5 "125kW" 4 "150kW" 3 "175kW" 2 "200kW" 1 "225kW" 0 "Norequest" ;
VAL_ 1109 CHR455_4_2_ACCHG_CURUPLMT 15 "Fail" 14 "Initial" 6 "8A" 5 "12A" 4 "16A" 3 "24A" 2 "32A" 1 "40A" 0 "MAX" ;
VAL_ 1109 CHR455_3_1_CHG_CNRLOCSTT 3 "Undefined" 2 "LockState" 1 "UnlockState" 0 "Initial" ;
VAL_ 1109 CHR455_3_0_CHG_CNRCNTSTT 1 "Connector_Connected" 0 "Connector_Not_Connected" ;
VAL_ 116 BEV074_7_0_LVPWRDWN 3 "抑制レベル3" 2 "抑制レベル2" 1 "抑制レベル1" 0 "抑制要求なし" ;
VAL_ 116 BEV074_7_6_CHRCONSTA 1 "Connected" 0 "NotConnected" ;
VAL_ 116 BEV074_7_7_VEHICLE_IGN 1 "ON" 0 "OFF" ;
VAL_ 116 BEV074_6_0_EV_CAU 3 "Undefine" 2 "Flash" 1 "Turn_On" 0 "Turn_Off" ;
VAL_ 116 BEV074_6_2_BEV_OBD_CAU 7 "Undefine" 6 "Undefine" 5 "Undefine" 4 "Initial_Check" 3 "Flash_3Hz" 2 "Flash_1Hz" 1 "Turn_On" 0 "Turn_Off" ;
VAL_ 116 BEV074_6_5_SIDRIVE_DISP 7 "PreS#" 6 "S#_TADAN" 5 "X(DEEP SNOW・MUD)" 4 "X(SNOW･DIRT)" 3 "S" 2 "I" 1 "S#" 0 "TURN_OFF" ;
VAL_ 116 BEV074_5_0_ACCHG_STATE 1 "充電実施中" 0 "充電未実施" ;
VAL_ 116 BEV074_5_1_DCCHG_STATE 1 "DC充電実施中" 0 "DC充電未実施" ;
VAL_ 116 BEV074_5_2_RANGE_DG 1 "異常" 0 "正常" ;
VAL_ 116 BEV074_5_3_ACCP_DG 1 "ON" 0 "OFF" ;
VAL_ 116 BEV074_5_4_REZ_SPD_BK 3 "FS固定値" 2 "FSバックアップ値(符号無し)" 1 "FSバックアップ値" 0 "センサ値" ;
VAL_ 116 BEV074_5_6_OBDRDY 1 "Ready-ON" 0 "Ready-OFF" ;
VAL_ 116 BEV074_5_7_FHVB 1 "ON" 0 "OFF" ;
VAL_ 116 BEV074_3_0_RANGE_POS 7 "未定義" 6 "blank" 5 "未定義" 4 "B" 3 "D" 2 "N" 1 "R" 0 "P" ;
VAL_ 116 BEV074_3_3_DRVRDY 3 "Undefine" 2 "Turn_ON" 1 "Flash" 0 "Turn_Off" ;
VAL_ 116 BEV074_3_5_HVSYSTS 3 "停止処理中" 2 "起動処理中" 1 "起動" 0 "停止" ;
VAL_ 116 BEV074_1_4_RANGE_DG2 1 "異常" 0 "正常" ;
VAL_ 116 BEV074_1_5_REZ_SPD_BK 5 "FS固定値" 4 "RrFSバックアップ値(符号無し)" 3 "FrFSバックアップ値(符号無し)" 2 "Rrセンサ値" 1 "Frセンサ値" 0 "FrRrセンサ値" ;
VAL_ 996 CECU3E4_7_0_SSM_COMM_INFO 1 "COMM_ON" 0 "COMM_OFF" ;
VAL_ 996 CECU3E4_6_0_CHARGE_LEVEL_ENG_RUN 9 "level10" 8 "level9" 7 "level8" 6 "level7" 5 "level6" 4 "level5" 3 "level4" 2 "level3" 1 "level2" 0 "level1" ;
VAL_ 996 CECU3E4_6_4_CHARGE_LEVEL_IGN_ON 9 "level10" 8 "level9" 7 "level8" 6 "level7" 5 "level6" 4 "level5" 3 "level4" 2 "level3" 1 "level2" 0 "level1" ;
VAL_ 996 CECU3E4_5_0_GENERATOR_OVER_FLG 3 "EvLoadRestrain2" 2 "EvLoadRestrain1" 1 "Overloaded" 0 "NormalState" ;
VAL_ 996 CECU3E4_5_3_DIAG_COM_REQ 1 "Diag_Com_Request" 0 "No_Request" ;
VAL_ 996 CECU3E4_5_4_HEADS_UP_FLG 1 "ChargeRequest" 0 "Normal" ;
VAL_ 996 CECU3E4_2_7_OCCUPATION_CSTM 1 "D_SEAT" 0 "ALL_SEATS" ;
VAL_ 1280 CGW500_1_4_ActiveWakeUpBit 1 "active wakeup" 0 "passive wakeup" ;
VAL_ 1749 CECU6D5_6_0_CSTM_FMHD 7 "Undefined" 6 "Undefined" 5 "90sec" 4 "60sec" 3 "30sec" 2 "20sec" 1 "10sec" 0 "OFF" ;
VAL_ 1749 CECU6D5_5_0_CSTM_WRH 1 "ON" 0 "OFF" ;
VAL_ 1749 CECU6D5_5_1_CSTM_LMHD 3 "30sec" 2 "20sec" 1 "10sec" 0 "OFF" ;
VAL_ 1749 CECU6D5_5_5_CSTM_HBA 3 "Undefined" 2 "Undefined" 1 "ON" 0 "OFF" ;
VAL_ 1749 CECU6D5_5_7_ADB_ACTIVE 1 "ON" 0 "OFF" ;
VAL_ 1749 CECU6D5_4_0_JUDGE_ILL 1 "YES" 0 "NO" ;
VAL_ 1749 CECU6D5_4_1_HEADLAMP_AUTO_SW 1 "ON" 0 "OFF" ;
VAL_ 1749 CECU6D5_4_2_IND_ACTIVE_HBA 3 "Undefined" 2 "Blink" 1 "ON" 0 "OFF" ;
VAL_ 1749 CECU6D5_4_4_FGT_LGTOFF_WARNING 1 "ON" 0 "OFF" ;
VAL_ 1749 CECU6D5_3_0_CRN_R_REQ 3 "Undefined" 2 "ON" 1 "Faded OFF" 0 "OFF" ;
VAL_ 1749 CECU6D5_3_2_CRN_L_REQ 3 "Undefined" 2 "ON" 1 "Faded OFF" 0 "OFF" ;
VAL_ 1749 CECU6D5_3_4_FMH 1 "ON" 0 "OFF" ;
VAL_ 1749 CECU6D5_3_5_LMH 1 "ON" 0 "OFF" ;
VAL_ 1749 CECU6D5_2_0_LGT_1 1 "ON" 0 "OFF" ;
VAL_ 1749 CECU6D5_2_1_LGT_LO 1 "ON" 0 "OFF" ;
VAL_ 1749 CECU6D5_2_2_LGT_HI 1 "ON" 0 "OFF" ;
VAL_ 1749 CECU6D5_2_4_FFOG_RELAY_REQ 1 "ON" 0 "OFF" ;
VAL_ 1749 CECU6D5_2_5_RFOG_RELAY_REQ 1 "ON" 0 "OFF" ;
VAL_ 1749 CECU6D5_2_6_LGT_DRL 1 "ON" 0 "OFF" ;
VAL_ 1753 CECU6D9_2_2_RCC_BWAM_SETTING 1 "ON" 0 "OFF" ;
VAL_ 1753 CECU6D9_1_4_RCC_FLG 1 "RCC実行中" 0 "RCC停止中" ;
VAL_ 723 CECU2D3_2_5_IGA_STATE 1 "ON" 0 "OFF" ;
VAL_ 723 CECU2D3_2_6_IGB_STATE 1 "ON" 0 "OFF" ;
VAL_ 1739 DCM6CB_4_0_DKY_COM_REQ 18 "Friend device key deletion request" 6 "Vehicle PK/SK update request" 5 "Owner device key deletion request" 4 "Friend device key deletion request" 2 "Digital key deletion request" 0 "No request" ;
VAL_ 1739 DCM6CB_3_5_PNC_SW_REQ_SRV 5 "Certificate deletion request" 4 "Key unlock request" 3 "Key lock request" 2 "ON request" 1 "OFF request" 0 "No request" ;
VAL_ 1739 DCM6CB_2_0_SHUTDOWN_REQ 1 "ON" 0 "OFF" ;
VAL_ 1739 DCM6CB_2_3_IGB_OFF_REQUEST 1 "REQUEST" 0 "NOT_REQUEST" ;
VAL_ 1739 DCM6CB_2_4_IGB_ON_REQUEST 1 "REQUEST" 0 "NOT_REQUEST" ;
VAL_ 1705 MVS6A9_6_0_CSTM_HITCHLINE_DSPREQ 3 "Reserved" 2 "Disp(Gray out)" 1 "Disp(Normal)" 0 "No Disp" ;
VAL_ 1705 MVS6A9_6_2_CSTM_HITCHLINE 1 "ON" 0 "OFF" ;
VAL_ 1705 MVS6A9_5_0_RR_WIDE_VIEW_SW_STATE 3 "Reserved" 2 "Selected" 1 "Not Selectable" 0 "Selectable" ;
VAL_ 1705 MVS6A9_5_2_RR_NRW_VIEW_SW_STATE 3 "Reserved" 2 "Selected" 1 "Not Selectable" 0 "Selectable" ;
VAL_ 1705 MVS6A9_5_4_HITCH_VIEW_SW_STATE 3 "Reserved" 2 "Selected" 1 "Not Selectable" 0 "Selectable" ;
VAL_ 1705 MVS6A9_4_0_FT_NRW_VIEW_SW_STATE 3 "Reserved" 2 "Selected" 1 "Not Selectable" 0 "Selectable" ;
VAL_ 1705 MVS6A9_4_2_FT_WIDE_VIEW_SW_STATE 3 "Reserved" 2 "Selected" 1 "Not Selectable" 0 "Selectable" ;
VAL_ 1705 MVS6A9_4_4_SIDE_VIEW_SW_STATE 3 "Reserved" 2 "Selected" 1 "Not Selectable" 0 "Selectable" ;
VAL_ 1705 MVS6A9_4_6_3D_VIEW_SW_STATE 3 "Reserved" 2 "Selected" 1 "Not Selectable" 0 "Selectable" ;
VAL_ 1705 MVS6A9_3_0_CSTM_AUTO_DISPLAY_SET 1 "Apply" 0 "No_Apply" ;
VAL_ 1705 MVS6A9_3_1_CSTM_AUTO_DISPLAY 1 "ON" 0 "OFF" ;
VAL_ 1705 MVS6A9_3_2_VIEW_MODE 3 "Other Mode" 2 "Parking Mode" 1 "Forward Mode" 0 "Backward Mode" ;
VAL_ 1705 MVS6A9_3_5_STOP_SWITCH 1 "Enable" 0 "Disable" ;
VAL_ 1705 MVS6A9_3_6_CSTM_HITCH_VIEW 1 "Available" 0 "Not Available" ;
VAL_ 1705 MVS6A9_2_0_CURRENT_VIEW 31 "Reserved" 30 "Reserved" 29 "Reserved" 28 "Reserved" 27 "Reserved" 26 "Reserved" 25 "Hitch Ball View" 24 "Top+3D View (FRONT)" 23 "Top View+Side and Side View" 22 "Top View+Front Narrow" 21 "Top View+Front Wide" 20 "Top View+Rear Narrow" 19 "Top View+Rear Wide" 18 "Left Side View Corresponded Regulation (reverse)" 17 "Left Side View Corresponded Regulation (Forward)" 16 "Top View (REAR)" 15 "3D Bird's View" 14 "Top and Rear View (RIGHT)" 13 "Top and Rear View (LEFT)" 12 "Top and Front View (RIGHT)" 11 "Top and Front View (LEFT)" 10 "Top View (FRONT)" 9 "Side and Side View" 8 "Front View and Side View (RIGHT)" 7 "Front View and Side View (LEFT)" 6 "Rear View and Side View (RIGHT)" 5 "Rear View and Side View (LEFT)" 4 "Side View (RIGHT)" 3 "Side View (LEFT)" 2 "Front View" 1 "Rear View" 0 "Black Display" ;
VAL_ 1705 MVS6A9_2_5_HOLD_TIME 1 "Short" 0 "Long" ;
VAL_ 1705 MVS6A9_1_4_FAIL_MVS 1 "FAIL" 0 "NORMAL" ;
VAL_ 1705 MVS6A9_1_5_FAIL_MVS_CAUSE 7 "No_Definition" 6 "No_Definition" 5 "No_Definition" 4 "EYE-MVS_CAN" 3 "Switch" 2 "Front_Camera" 1 "MVS" 0 "NORMAL" ;
VAL_ 930 MET3A2_6_0_SEATBELT_RR_RH 1 "ON_BeltOFF" 0 "OFF_BeltON" ;
VAL_ 930 MET3A2_6_1_SEATBELT_RR_CTR 1 "ON_BeltOFF" 0 "OFF_BeltON" ;
VAL_ 930 MET3A2_6_2_SEATBELT_RR_LH 1 "ON_BeltOFF" 0 "OFF_BeltON" ;
VAL_ 930 MET3A2_6_3_SEATBELT_THIRD_RH 1 "ON_BeltOFF" 0 "OFF_BeltON" ;
VAL_ 930 MET3A2_6_4_SEATBELT_THIRD_CTR 1 "ON_BeltOFF" 0 "OFF_BeltON" ;
VAL_ 930 MET3A2_6_5_SEATBELT_THIRD_LH 1 "ON_BeltOFF" 0 "OFF_BeltON" ;
VAL_ 930 MET3A2_5_0_FLG_RR_REMINDER 1 "REAR REMINDER ON" 0 "OFF" ;
VAL_ 930 MET3A2_1_4_FAIL_DISP 3 "Reserve" 2 "Reserve" 1 "MET_FAIL_DISP" 0 "NORMAL" ;
VAL_ 1677 MET68D_7_0_STATUS_WASHER_LAMP 1 "ON" 0 "OFF" ;
VAL_ 1677 MET68D_7_1_OILPRESSURE_SW 1 "SW_GND" 0 "SW_OPEN" ;
VAL_ 1677 MET68D_7_2_FLG_EAM 1 "EAM" 0 "NOT_EAM" ;
VAL_ 1677 MET68D_7_3_CSTM_IND_RED 1 "ON" 0 "OFF" ;
VAL_ 1677 MET68D_7_4_CSTM_IND_YELLOW 1 "ON" 0 "OFF" ;
VAL_ 1677 MET68D_7_5_CSTM_IND_GREEN 1 "ON" 0 "OFF" ;
VAL_ 1677 MET68D_7_6_REQ_CSTM_SRH 1 "required" 0 "NOT required" ;
VAL_ 1677 MET68D_7_7_CSTM_SRH 1 "ON" 0 "OFF" ;
VAL_ 1677 MET68D_6_5_REQ_CHG_CSTM_RAB 1 "required" 0 "NOT required" ;
VAL_ 1677 MET68D_6_6_CSTM_RAB 1 "ON" 0 "OFF" ;
VAL_ 1677 MET68D_6_7_CSTM_SONNER 1 "ON" 0 "OFF" ;
VAL_ 1677 MET68D_1_4_RESET_CSTM_TPMS_RAEB 1 "REQUIRED" 0 "NOT REQUIRED" ;
VAL_ 1677 MET68D_1_5_REQ_CHG_CSTM_TPMS 1 "required" 0 "NOT required" ;
VAL_ 1677 MET68D_1_6_CSTM_TIRE_UNIT 3 "未定義" 2 "bar" 1 "kPa" 0 "psi" ;
VAL_ 1676 MET68C_7_0_CSTM_OUTTEMP 15 "NONE" 14 "NONE" 13 "-5" 12 "-4" 11 "-3" 10 "-2" 9 "-1" 8 "-0" 7 "NONE" 6 "NONE" 5 "+5" 4 "+4" 3 "+3" 2 "+2" 1 "+1" 0 "+0" ;
VAL_ 1676 MET68C_4_6_UNIT_DEGREE 3 "reserved" 2 "deg F" 1 "deg C" 0 "Invalid" ;
VAL_ 1676 MET68C_3_0_MET_SW_STATE 3 "▼SW ON" 2 "i/SET SW ON" 1 "▲ SW ON" 0 "no SW input" ;
VAL_ 1676 MET68C_3_3_PERMIT_MFD_CSTM 1 "OK" 0 "NG" ;
VAL_ 1676 MET68C_3_5_FLG_RR_AC_PANEL 1 "REAR_AC_PANEL" 0 "NOT_REAR_AC_PANEL" ;
VAL_ 1676 MET68C_3_6_FLG_SEAT_VENT 1 "SEAT_VENT" 0 "NOT_SEAT_VENT" ;
VAL_ 1676 MET68C_3_7_FLG_SEAT_HEAT 1 "SEAT_HEATER" 0 "NOT_SEAT_HEATER" ;
VAL_ 1676 MET68C_1_4_CSTM_HU 1 "with HU" 0 "without HU" ;
VAL_ 1676 MET68C_1_5_CSTM_BRAND_NAME 1 "SBR" 0 "TMC" ;
VAL_ 922 MET39A_7_0_SET_LANGUAGE 21 "Norsk" 20 "Svenska" 19 "Dansk" 18 "Suomi" 17 "Ελληνικ?" 16 "Polski" 15 "Укра?нська" 14 "Turkce" 13 "Magyar" 12 "Ceske" 11 "Slovensky" 10 "Romana" 9 "China" 8 "Русский" 7 "Francais" 6 "Deutsh" 5 "Nederlands" 4 "Espanol" 3 "Portuges" 2 "Italiano" 1 "English" 0 "Japanese" ;
VAL_ 922 MET39A_7_5_ACTIVE_MET_CSTM 1 "ACTIVE" 0 "PASSIVE" ;
VAL_ 922 MET39A_7_6_MFD_SPEC 1 "color MFD" 0 "segment MFD" ;
VAL_ 922 MET39A_7_7_ICY_ROAD_SURFACE 2 "ON" 1 "OFF" ;
VAL_ 922 MET39A_6_4_STATUS_TRIP_A_B 1 "TRIP_B" 0 "TRIP_A" ;
VAL_ 922 MET39A_3_1_STATUS_FUEL_LAMP 3 "BLINK_SHORT/OPEN" 2 "TURN_ON_LFW" 1 "INITIAL_CHECK" 0 "TURN_OFF" ;
VAL_ 922 MET39A_3_3_TRANSIT_TIME 1 "1H" 0 "OFF" ;
VAL_ 922 MET39A_1_4_SET_UNIT_OF_FUEL 3 "MPG(英国ｶﾞﾛﾝ)" 2 "MPG(米国ｶﾞﾛﾝ)" 1 "l/100km" 0 "km/ｌ" ;
VAL_ 922 MET39A_1_6_WELCOME_TRIG 2 "ON" 1 "OFF" ;
VAL_ 922 MET39A_1_7_METER_DISPLAY_TYPE 2 "color TFT" 1 "segment LCD" ;
VAL_ 915 MET393_7_0_REQ_CHG_CSTM_EYE 1 "required" 0 "NOT required" ;
VAL_ 915 MET393_7_1_REQ_RESET_CSTM_EYE 1 "REQUIRED" 0 "NOT REQUIRED" ;
VAL_ 915 MET393_7_2_CSTM_ALK 1 "ON" 0 "OFF" ;
VAL_ 915 MET393_7_3_CSTM_HBA 1 "SAE_Mode" 0 "Normal" ;
VAL_ 915 MET393_7_4_CSTM_MIS_AT_BACK 3 "ON_FAST" 2 "ON_MIDDLE" 1 "ON_SLOW" 0 "OFF" ;
VAL_ 915 MET393_7_6_CSTM_ACC_CONT 3 "LEV4" 2 "LEV3" 1 "LEV2" 0 "LEV1" ;
VAL_ 915 MET393_5_2_WARN_R_DIFF_TEMP 3 "Turn_ON_Initial_Check" 2 "BLINK" 1 "Turn_ON" 0 "Turn_OFF" ;
VAL_ 915 MET393_5_4_ADAPTIVECC_NOALIVE 1 "NO_ALIVE" 0 "ALIVE" ;
VAL_ 915 MET393_5_5_DUAL_RANGE_LO 1 "SW GND" 0 "SW OPEN" ;
VAL_ 915 MET393_5_6_CSTM_SPD_LIMITER 1 "Control_ON" 0 "Control_OFF" ;
VAL_ 915 MET393_5_7_CSTM_LANE_CONT 1 "LEFT" 0 "RIGHT" ;
VAL_ 915 MET393_3_5_SI_DRIVE_SW 7 "BLANK_NoInput" 6 "I_Input" 5 "ECO-C_Input" 4 "I_Input" 3 "X_MUD_SAND_or_GRAVEL_Input" 2 "S#_Input" 1 "X_SNOW_DIRT_Input" 0 "BLANK_NoInput" ;
VAL_ 915 MET393_1_4_CSTM_IND_BLUE 1 "ON" 0 "OFF" ;
VAL_ 915 MET393_1_5_CSTM_AES_CONT 1 "ON" 0 "OFF" ;
VAL_ 915 MET393_1_6_FLG_PEDESTRIAN_AIRBAG 1 "OEDESTRIAN AIRBAG" 0 "OTHER" ;
VAL_ 912 MET390_7_0_VDC_ON_OFF 3 "BLANK_NoInput" 2 "VDC ON_Input" 1 "VDC OFF_Input" 0 "Neutral" ;
VAL_ 912 MET390_7_2_RR_DOOR_RECORD_L 1 "OPEN" 0 "CLOSE" ;
VAL_ 912 MET390_7_3_RR_DOOR_RECORD_R 1 "OPEN" 0 "CLOSE" ;
VAL_ 912 MET390_7_4_REQ_CHG_CSTM_PSM 1 "required" 0 "NOT required" ;
VAL_ 912 MET390_7_5_REQ_RESET_CSTM_PSM 1 "REQUIRED" 0 "NOT　REQUIRED" ;
VAL_ 912 MET390_7_6_CSTM_MIR_AFOLD_CONT 1 "ON" 0 "OFF" ;
VAL_ 912 MET390_7_7_CSTM_MIR_RTILT_CONT 1 "ON" 0 "OFF" ;
VAL_ 912 MET390_6_0_SEATBELT_DRVR 1 "ON" 0 "OFF" ;
VAL_ 912 MET390_6_1_SEATBELT_PASS 1 "ON" 0 "OFF" ;
VAL_ 912 MET390_6_2_TURN_SIG_LEFT 1 "Turn_L_OutPut" 0 "OFF" ;
VAL_ 912 MET390_6_3_TURN_SIG_RIGHT 1 "Turn_R_OutPut" 0 "OFF" ;
VAL_ 912 MET390_6_4_BRIGHT_SW 1 "ON" 0 "OFF" ;
VAL_ 912 MET390_6_5_FAIL_UART_WA_BOX 1 "FAIL" 0 "NORMAL" ;
VAL_ 912 MET390_6_6_ISS_OFF_SW 1 "While SW is being pushed down." 0 "While SW is not being pushed down." ;
VAL_ 912 MET390_6_7_FLG_DMS 1 "DMS" 0 "NOT_DMS" ;
VAL_ 912 MET390_3_0_UNIT_SPEED_TRIP 1 "MPH、miles" 0 "km/h、km" ;
VAL_ 912 MET390_3_1_FLG_EYESIGHT 1 "EYESIGHT" 0 "OTHER" ;
VAL_ 912 MET390_3_2_FLG_ISS 1 "ISS" 0 "OTHER" ;
VAL_ 912 MET390_3_3_FLG_HEV 1 "HEV" 0 "OTHER" ;
VAL_ 912 MET390_3_4_FLG_IMB 1 "IMB_ACTIVE" 0 "NON_IMB" ;
VAL_ 912 MET390_3_5_TIRE_SIZE 1 "SPECIAL_SIZE" 0 "STANDARD_SIZE" ;
VAL_ 912 MET390_3_6_FLG_XMODE 3 "X_2MODE(GRAVEL)" 2 "X_2MODE" 1 "X_1MODE" 0 "NOT_X" ;
VAL_ 912 MET390_2_0_VEHICLE_SERIES 7 "VEHICLE_Z" 6 "VEHICLE_W" 5 "VEHICLE_V" 4 "VEHICLE_B" 3 "VEHICLE_Y" 2 "VEHICLE_S" 1 "VEHICLE_G" 0 "NON" ;
VAL_ 912 MET390_2_3_DESTINATION 12 "KC" 11 "Korea_C6" 10 "China_EHETES" 9 "Australia_KA" 8 "Singapore_ERENKYKEKVKP" 7 "England_EK" 6 "SaudiArabia_KSKG" 5 "STANDARD_LH_K4E3E5C4" 4 "Europe_LH_ECEAE2EEEPE9E7E1" 3 "CANADA_C5C0" 2 "US_U4U5U6" 1 "DOM" 0 "NON" ;
VAL_ 912 MET390_2_7_PASS_DOOR_RECORD 1 "OPEN" 0 "CLOSE" ;
VAL_ 912 MET390_1_4_WAKE_UP_FRAME 1 "WakeUP_FRAME" 0 "Normal_FRAME" ;
VAL_ 912 MET390_1_5_REQ_COMM_CONT 1 "REQ" 0 "NON_REQ" ;
VAL_ 912 MET390_1_6_DMS_ID_SET 1 "REQUIRED" 0 "NOT REQUIRED" ;
VAL_ 912 MET390_1_7_FAIL_EEPROM 1 "FAIL" 0 "NORMAL" ;
